VERSION "dbc-export 1 2025.20.8"

NS_ :

BS_:

BU_: ADSP APB APP APS APSB BB BMS CC CMP CMPD CP DAS DI DIF DIR DPB EPAS3P EPAS3S EPASTP EPASTS EPBL EPBR ESP GTW HVP IBST ICR IDB OCS1P ODIN PARK PCS PLG PM PMF PMR PTC RADC RCM RCM2 RCU SCCM SDCR TAS TCU TPMS TRCM UDS UI UIS UMC USM VC VCFRONT VCLEFT VCRIGHT VCSEC

BO_ 998 RCU_alertMatrix: 8 RCU
 SG_ RCU_matrixIndex M : 0|4@1+ (1,0) [0|15] "" Vector__XXX
 SG_ RCU_a001_valveDriverFault m0 : 4|1@1+ (1,0) [0|1] "" Vector__XXX
 SG_ RCU_a002_solenoidValveFault m0 : 5|1@1+ (1,0) [0|1] "" Vector__XXX
 SG_ RCU_a003_pumpMotorFault m0 : 6|1@1+ (1,0) [0|1] "" Vector__XXX
 SG_ RCU_a004_supplyOvervoltage m0 : 7|1@1+ (1,0) [0|1] "" Vector__XXX
 SG_ RCU_a005_supplyUndervoltage m0 : 8|1@1+ (1,0) [0|1] "" Vector__XXX
 SG_ RCU_a006_wakeLineOpen m0 : 9|1@1+ (1,0) [0|1] "" Vector__XXX
 SG_ RCU_a007_pressureSensorFault m0 : 10|1@1+ (1,0) [0|1] "" Vector__XXX
 SG_ RCU_a008_pressureNotCalibrated m0 : 11|1@1+ (1,0) [0|1] "" Vector__XXX
 SG_ RCU_a009_brakeFluidLow m0 : 12|1@1+ (1,0) [0|1] "" Vector__XXX
 SG_ RCU_a010_pedalSensorFault m0 : 13|1@1+ (1,0) [0|1] "" Vector__XXX
 SG_ RCU_a011_idbPedalTravelMismatch m0 : 14|1@1+ (1,0) [0|1] "" Vector__XXX
 SG_ RCU_a012_pedalSensorNotCal m0 : 15|1@1+ (1,0) [0|1] "" Vector__XXX
 SG_ RCU_a013_mcuGenericFault m0 : 16|1@1+ (1,0) [0|1] "" Vector__XXX
 SG_ RCU_a014_asicTempHigh m0 : 17|1@1+ (1,0) [0|1] "" Vector__XXX
 SG_ RCU_a015_fluidLeakDetected m0 : 18|1@1+ (1,0) [0|1] "" Vector__XXX
 SG_ RCU_a016_partyBusOff m0 : 19|1@1+ (1,0) [0|1] "" Vector__XXX
 SG_ RCU_a017_chassisBusOff m0 : 20|1@1+ (1,0) [0|1] "" Vector__XXX
 SG_ RCU_a018_DItorquePathFaulted m0 : 21|1@1+ (1,0) [0|1] "" Vector__XXX
 SG_ RCU_a019_DItorquePathActive m0 : 22|1@1+ (1,0) [0|1] "" Vector__XXX
 SG_ RCU_a020_BBstatusDLC m0 : 23|1@1+ (1,0) [0|1] "" Vector__XXX
 SG_ RCU_a021_BBstatusChecksum m0 : 24|1@1+ (1,0) [0|1] "" Vector__XXX
 SG_ RCU_a022_BBstatusCounter m0 : 25|1@1+ (1,0) [0|1] "" Vector__XXX
 SG_ RCU_a023_IDBstatusDLC m0 : 26|1@1+ (1,0) [0|1] "" Vector__XXX
 SG_ RCU_a024_IDBstatusChecksum m0 : 27|1@1+ (1,0) [0|1] "" Vector__XXX
 SG_ RCU_a025_IDBstatusCounter m0 : 28|1@1+ (1,0) [0|1] "" Vector__XXX
 SG_ RCU_a026_DIchassisControlDLC m0 : 29|1@1+ (1,0) [0|1] "" Vector__XXX
 SG_ RCU_a027_DIchassisCtrlChecksum m0 : 30|1@1+ (1,0) [0|1] "" Vector__XXX
 SG_ RCU_a028_DIchassisControlCounter m0 : 31|1@1+ (1,0) [0|1] "" Vector__XXX
 SG_ RCU_a029_PMstate2DLC m0 : 32|1@1+ (1,0) [0|1] "" Vector__XXX
 SG_ RCU_a030_PMstate2Checksum m0 : 33|1@1+ (1,0) [0|1] "" Vector__XXX
 SG_ RCU_a031_PMstate2Counter m0 : 34|1@1+ (1,0) [0|1] "" Vector__XXX
 SG_ RCU_a032_VCFRONTLVPowerStateDLC m0 : 35|1@1+ (1,0) [0|1] "" Vector__XXX
 SG_ RCU_a033_VCFRONTLVPowerStateChec m0 : 36|1@1+ (1,0) [0|1] "" Vector__XXX
 SG_ RCU_a034_VCFRONTLVPowerStateCoun m0 : 37|1@1+ (1,0) [0|1] "" Vector__XXX
 SG_ RCU_a035_IDBpcpInvalid m0 : 38|1@1+ (1,0) [0|1] "" Vector__XXX
 SG_ RCU_a036_IDBpspInvalid m0 : 39|1@1+ (1,0) [0|1] "" Vector__XXX
 SG_ RCU_a037_IDBinputRodStrokeInvali m0 : 40|1@1+ (1,0) [0|1] "" Vector__XXX
 SG_ RCU_a038_DIsystemStatusDLC m0 : 41|1@1+ (1,0) [0|1] "" Vector__XXX
 SG_ RCU_a039_DIaccelPosInvalid m0 : 42|1@1+ (1,0) [0|1] "" Vector__XXX
 SG_ RCU_a040_DIgearInvalid m0 : 43|1@1+ (1,0) [0|1] "" Vector__XXX
 SG_ RCU_a041_DIsystemStatusCounter m0 : 44|1@1+ (1,0) [0|1] "" Vector__XXX
 SG_ RCU_a042_DIsystemStatusChecksum m0 : 45|1@1+ (1,0) [0|1] "" Vector__XXX
 SG_ RCU_a043_VCFRONTiBoosterLvStateI m0 : 46|1@1+ (1,0) [0|1] "" Vector__XXX
 SG_ RCU_a044_VCFRONTsensorsMIA m0 : 47|1@1+ (1,0) [0|1] "" Vector__XXX
 SG_ RCU_a045_VCFRONTtempInvalid m0 : 48|1@1+ (1,0) [0|1] "" Vector__XXX
 SG_ RCU_a046_brakeFluidLevelSNA m0 : 49|1@1+ (1,0) [0|1] "" Vector__XXX
 SG_ RCU_a047_ESPwheelSpeedsDLC m0 : 50|1@1+ (1,0) [0|1] "" Vector__XXX
 SG_ RCU_a048_ESPFrLWSSLInvalid m0 : 51|1@1+ (1,0) [0|1] "" Vector__XXX
 SG_ RCU_a049_ESPFrRWSSLInvalid m0 : 52|1@1+ (1,0) [0|1] "" Vector__XXX
 SG_ RCU_a050_ESPReLWSSLInvalid m0 : 53|1@1+ (1,0) [0|1] "" Vector__XXX
 SG_ RCU_a051_ESPReRWSSLInvalid m0 : 54|1@1+ (1,0) [0|1] "" Vector__XXX
 SG_ RCU_a052_ESPwheelSpeedsCounter m0 : 55|1@1+ (1,0) [0|1] "" Vector__XXX
 SG_ RCU_a053_ESPwheelSpeedsChecksum m0 : 56|1@1+ (1,0) [0|1] "" Vector__XXX
 SG_ RCU_a054_IDBcircuitPressFaulted m0 : 57|1@1+ (1,0) [0|1] "" Vector__XXX
 SG_ RCU_a055_IDBsimulatorPressFaulte m0 : 58|1@1+ (1,0) [0|1] "" Vector__XXX
 SG_ RCU_a056_redundantControllerIsMa m0 : 59|1@1+ (1,0) [0|1] "" Vector__XXX
 SG_ RCU_a057_PMebrCmdStateInvalid m0 : 60|1@1+ (1,0) [0|1] "" Vector__XXX
 SG_ RCU_a058_DIbrakeTorqueCommandAnd m0 : 61|1@1+ (1,0) [0|1] "" Vector__XXX

BO_ 831 RCU_info: 8 RCU
 SG_ RCU_infoIndex M : 0|8@1+ (1,0) [0|255] "" Vector__XXX
 SG_ RCU_infoPcbaID m11 : 16|8@1+ (1,0) [0|255] "" Vector__XXX
 SG_ RCU_infoAssemblyID m11 : 24|8@1+ (1,0) [0|255] "" Vector__XXX
 SG_ RCU_infoUsageID m11 : 32|16@1+ (1,0) [0|65535] "" Vector__XXX
 SG_ RCU_infoSubUsageID m11 : 48|16@1+ (1,0) [0|65535] "" Vector__XXX

BO_ 1344 SCCM_alertLog: 8 SCCM
 SG_ SCCM_alertID M : 0|15@1+ (1,0) [0|32767] "" Vector__XXX
 SG_ SCCM_alertState : 15|1@1+ (1,0) [0|1] "" Vector__XXX
 SG_ SCCM_a003_debouncePosition m3 : 16|8@1+ (1,0) [0|255] "-" Vector__XXX
 SG_ SCCM_a003_rawPosition m3 : 24|8@1+ (1,0) [0|255] "-" Vector__XXX
 SG_ SCCM_a003_errorPosition m3 : 32|8@1+ (1,0) [0|255] "-" Vector__XXX
 SG_ SCCM_a003_adcValue m3 : 40|8@1+ (1,0) [0|255] "-" Vector__XXX
 SG_ SCCM_a004_debouncePosition m4 : 16|8@1+ (1,0) [0|255] "-" Vector__XXX
 SG_ SCCM_a004_rawPosition m4 : 24|8@1+ (1,0) [0|255] "-" Vector__XXX
 SG_ SCCM_a004_errorPosition m4 : 32|8@1+ (1,0) [0|255] "-" Vector__XXX
 SG_ SCCM_a004_adcValue m4 : 40|8@1+ (1,0) [0|255] "-" Vector__XXX
 SG_ SCCM_a005_debouncePosition m5 : 16|8@1+ (1,0) [0|255] "-" Vector__XXX
 SG_ SCCM_a005_rawPosition m5 : 24|8@1+ (1,0) [0|255] "-" Vector__XXX
 SG_ SCCM_a005_errorPosition m5 : 32|8@1+ (1,0) [0|255] "-" Vector__XXX
 SG_ SCCM_a005_adcValue m5 : 40|8@1+ (1,0) [0|255] "-" Vector__XXX
 SG_ SCCM_a006_debouncePosition m6 : 16|8@1+ (1,0) [0|255] "-" Vector__XXX
 SG_ SCCM_a006_rawPosition m6 : 24|8@1+ (1,0) [0|255] "-" Vector__XXX
 SG_ SCCM_a006_errorPosition m6 : 32|8@1+ (1,0) [0|255] "-" Vector__XXX
 SG_ SCCM_a006_adcValue m6 : 40|8@1+ (1,0) [0|255] "-" Vector__XXX
 SG_ SCCM_a007_debouncePosition m7 : 16|8@1+ (1,0) [0|255] "-" Vector__XXX
 SG_ SCCM_a007_rawPosition m7 : 24|8@1+ (1,0) [0|255] "-" Vector__XXX
 SG_ SCCM_a007_errorPosition m7 : 32|8@1+ (1,0) [0|255] "-" Vector__XXX
 SG_ SCCM_a007_adcValue1 m7 : 40|8@1+ (1,0) [0|255] "-" Vector__XXX
 SG_ SCCM_a007_adcValue2 m7 : 48|8@1+ (1,0) [0|255] "-" Vector__XXX
 SG_ SCCM_a008_debouncePosition m8 : 16|8@1+ (1,0) [0|255] "-" Vector__XXX
 SG_ SCCM_a008_rawPosition m8 : 24|8@1+ (1,0) [0|255] "-" Vector__XXX
 SG_ SCCM_a008_errorPosition m8 : 32|8@1+ (1,0) [0|255] "-" Vector__XXX
 SG_ SCCM_a008_adcValue1 m8 : 40|8@1+ (1,0) [0|255] "-" Vector__XXX
 SG_ SCCM_a008_adcValue2 m8 : 48|8@1+ (1,0) [0|255] "-" Vector__XXX
 SG_ SCCM_a009_debouncePosition m9 : 16|8@1+ (1,0) [0|255] "-" Vector__XXX
 SG_ SCCM_a009_rawPosition m9 : 24|8@1+ (1,0) [0|255] "-" Vector__XXX
 SG_ SCCM_a009_errorPosition m9 : 32|8@1+ (1,0) [0|255] "-" Vector__XXX
 SG_ SCCM_a009_adcValue1 m9 : 40|8@1+ (1,0) [0|255] "-" Vector__XXX
 SG_ SCCM_a009_adcValue2 m9 : 48|8@1+ (1,0) [0|255] "-" Vector__XXX
 SG_ SCCM_a010_debouncePosition m10 : 16|8@1+ (1,0) [0|255] "-" Vector__XXX
 SG_ SCCM_a010_rawPosition m10 : 24|8@1+ (1,0) [0|255] "-" Vector__XXX
 SG_ SCCM_a010_errorPosition m10 : 32|8@1+ (1,0) [0|255] "-" Vector__XXX
 SG_ SCCM_a010_adcValue1 m10 : 40|8@1+ (1,0) [0|255] "-" Vector__XXX
 SG_ SCCM_a010_adcValue2 m10 : 48|8@1+ (1,0) [0|255] "-" Vector__XXX
 SG_ SCCM_a011_debouncePosition m11 : 16|8@1+ (1,0) [0|255] "-" Vector__XXX
 SG_ SCCM_a011_rawPosition m11 : 24|8@1+ (1,0) [0|255] "-" Vector__XXX
 SG_ SCCM_a011_errorPosition m11 : 32|8@1+ (1,0) [0|255] "-" Vector__XXX
 SG_ SCCM_a011_adcValue1 m11 : 40|8@1+ (1,0) [0|255] "-" Vector__XXX
 SG_ SCCM_a011_adcValue2 m11 : 48|8@1+ (1,0) [0|255] "-" Vector__XXX
 SG_ SCCM_a012_debouncePosition m12 : 16|8@1+ (1,0) [0|255] "-" Vector__XXX
 SG_ SCCM_a012_rawPosition m12 : 24|8@1+ (1,0) [0|255] "-" Vector__XXX
 SG_ SCCM_a012_errorPosition m12 : 32|8@1+ (1,0) [0|255] "-" Vector__XXX
 SG_ SCCM_a012_adcValue1 m12 : 40|8@1+ (1,0) [0|255] "-" Vector__XXX
 SG_ SCCM_a012_adcValue2 m12 : 48|8@1+ (1,0) [0|255] "-" Vector__XXX
 SG_ SCCM_a013_voltage m13 : 16|8@1+ (1,0) [0|255] "-" Vector__XXX
 SG_ SCCM_a014_voltage m14 : 16|8@1+ (1,0) [0|255] "-" Vector__XXX
 SG_ SCCM_a015_intMainIndex m15 : 16|8@1+ (1,0) [0|255] "-" Vector__XXX
 SG_ SCCM_a015_intSubIndex m15 : 24|8@1+ (1,0) [0|255] "-" Vector__XXX
 SG_ SCCM_a015_intMemIndex m15 : 32|8@1+ (1,0) [0|255] "-" Vector__XXX
 SG_ SCCM_a016_mainAdcTest m16 : 16|4@1+ (1,0) [0|15] "-" Vector__XXX
 SG_ SCCM_a016_mainCpuTest m16 : 20|4@1+ (1,0) [0|15] "-" Vector__XXX
 SG_ SCCM_a016_wdtTest m16 : 24|4@1+ (1,0) [0|15] "-" Vector__XXX
 SG_ SCCM_a016_subCpuTest m16 : 28|4@1+ (1,0) [0|15] "-" Vector__XXX
 SG_ SCCM_a016_subAdcTest m16 : 32|4@1+ (1,0) [0|15] "-" Vector__XXX
 SG_ SCCM_a017_mainRamTest m17 : 16|4@1+ (1,0) [0|15] "-" Vector__XXX
 SG_ SCCM_a017_mainRomTest m17 : 20|4@1+ (1,0) [0|15] "-" Vector__XXX
 SG_ SCCM_a017_stackHardLimitTest m17 : 24|4@1+ (1,0) [0|15] "-" Vector__XXX
 SG_ SCCM_a017_mainDataFlashTest m17 : 28|4@1+ (1,0) [0|15] "-" Vector__XXX
 SG_ SCCM_a017_subRamTest m17 : 32|4@1+ (1,0) [0|15] "-" Vector__XXX
 SG_ SCCM_a017_subRomTest m17 : 36|4@1+ (1,0) [0|15] "-" Vector__XXX
 SG_ SCCM_a017_subStackHardLimitTest m17 : 40|4@1+ (1,0) [0|15] "-" Vector__XXX
 SG_ SCCM_a017_svError m17 : 44|16@1+ (1,0) [0|65535] "-" Vector__XXX
 SG_ SCCM_a018_internalSASState m18 : 16|8@1+ (1,0) [0|255] "-" Vector__XXX
 SG_ SCCM_a019_internalSASState m19 : 16|8@1+ (1,0) [0|255] "-" Vector__XXX
 SG_ SCCM_a020_internalSASState m20 : 16|8@1+ (1,0) [0|255] "-" Vector__XXX
 SG_ SCCM_a021_adcValue1 m21 : 16|8@1+ (1,0) [0|255] "-" Vector__XXX
 SG_ SCCM_a021_adcValue2 m21 : 24|8@1+ (1,0) [0|255] "-" Vector__XXX
 SG_ SCCM_a021_adcValue3 m21 : 32|8@1+ (1,0) [0|255] "-" Vector__XXX
 SG_ SCCM_a021_adcValue4 m21 : 40|8@1+ (1,0) [0|255] "-" Vector__XXX
 SG_ SCCM_a021_adcValue5 m21 : 48|8@1+ (1,0) [0|255] "-" Vector__XXX
 SG_ SCCM_a021_adcValue6 m21 : 56|8@1+ (1,0) [0|255] "-" Vector__XXX
 SG_ SCCM_a022_adcValue1 m22 : 16|8@1+ (1,0) [0|255] "-" Vector__XXX
 SG_ SCCM_a022_adcValue2 m22 : 24|8@1+ (1,0) [0|255] "-" Vector__XXX
 SG_ SCCM_a022_adcValue3 m22 : 32|8@1+ (1,0) [0|255] "-" Vector__XXX
 SG_ SCCM_a022_adcValue4 m22 : 40|8@1+ (1,0) [0|255] "-" Vector__XXX
 SG_ SCCM_a022_adcValue5 m22 : 48|8@1+ (1,0) [0|255] "-" Vector__XXX
 SG_ SCCM_a022_adcValue6 m22 : 56|8@1+ (1,0) [0|255] "-" Vector__XXX
 SG_ SCCM_a023_adcValue1 m23 : 16|8@1+ (1,0) [0|255] "-" Vector__XXX
 SG_ SCCM_a023_adcValue2 m23 : 24|8@1+ (1,0) [0|255] "-" Vector__XXX
 SG_ SCCM_a023_adcValue3 m23 : 32|8@1+ (1,0) [0|255] "-" Vector__XXX
 SG_ SCCM_a023_adcValue4 m23 : 40|8@1+ (1,0) [0|255] "-" Vector__XXX
 SG_ SCCM_a023_adcValue5 m23 : 48|8@1+ (1,0) [0|255] "-" Vector__XXX
 SG_ SCCM_a023_adcValue6 m23 : 56|8@1+ (1,0) [0|255] "-" Vector__XXX
 SG_ SCCM_a024_adcValue1 m24 : 16|8@1+ (1,0) [0|255] "-" Vector__XXX
 SG_ SCCM_a024_adcValue2 m24 : 24|8@1+ (1,0) [0|255] "-" Vector__XXX
 SG_ SCCM_a024_adcValue3 m24 : 32|8@1+ (1,0) [0|255] "-" Vector__XXX
 SG_ SCCM_a024_adcValue4 m24 : 40|8@1+ (1,0) [0|255] "-" Vector__XXX
 SG_ SCCM_a024_adcValue5 m24 : 48|8@1+ (1,0) [0|255] "-" Vector__XXX
 SG_ SCCM_a024_adcValue6 m24 : 56|8@1+ (1,0) [0|255] "-" Vector__XXX
 SG_ SCCM_a025_taskState m25 : 16|16@1+ (1,0) [0|65535] "-" Vector__XXX
 SG_ SCCM_a026_debouncePosition m26 : 16|8@1+ (1,0) [0|255] "-" Vector__XXX
 SG_ SCCM_a026_rawPosition m26 : 24|8@1+ (1,0) [0|255] "-" Vector__XXX
 SG_ SCCM_a026_errorPosition m26 : 32|8@1+ (1,0) [0|255] "-" Vector__XXX
 SG_ SCCM_a026_adcValue1 m26 : 40|8@1+ (1,0) [0|255] "-" Vector__XXX
 SG_ SCCM_a026_adcValue2 m26 : 48|8@1+ (1,0) [0|255] "-" Vector__XXX
 SG_ SCCM_a027_debouncePosition m27 : 16|8@1+ (1,0) [0|255] "-" Vector__XXX
 SG_ SCCM_a027_rawPosition m27 : 24|8@1+ (1,0) [0|255] "-" Vector__XXX
 SG_ SCCM_a027_errorPosition m27 : 32|8@1+ (1,0) [0|255] "-" Vector__XXX
 SG_ SCCM_a027_adcValue1 m27 : 40|8@1+ (1,0) [0|255] "-" Vector__XXX
 SG_ SCCM_a027_adcValue2 m27 : 48|8@1+ (1,0) [0|255] "-" Vector__XXX
 SG_ SCCM_a028_debouncePosition m28 : 16|8@1+ (1,0) [0|255] "-" Vector__XXX
 SG_ SCCM_a028_rawPosition m28 : 24|8@1+ (1,0) [0|255] "-" Vector__XXX
 SG_ SCCM_a028_errorPosition m28 : 32|8@1+ (1,0) [0|255] "-" Vector__XXX
 SG_ SCCM_a028_adcValue1 m28 : 40|8@1+ (1,0) [0|255] "-" Vector__XXX
 SG_ SCCM_a028_adcValue2 m28 : 48|8@1+ (1,0) [0|255] "-" Vector__XXX
 SG_ SCCM_a029_debouncePosition m29 : 16|8@1+ (1,0) [0|255] "-" Vector__XXX
 SG_ SCCM_a029_rawPosition m29 : 24|8@1+ (1,0) [0|255] "-" Vector__XXX
 SG_ SCCM_a029_errorPosition m29 : 32|8@1+ (1,0) [0|255] "-" Vector__XXX
 SG_ SCCM_a029_adcValue1 m29 : 40|8@1+ (1,0) [0|255] "-" Vector__XXX
 SG_ SCCM_a029_adcValue2 m29 : 48|8@1+ (1,0) [0|255] "-" Vector__XXX
 SG_ SCCM_a061_voltage m61 : 16|8@1+ (0.1,0) [0|25.5] "V" Vector__XXX
 SG_ SCCM_a062_voltage m62 : 16|8@1+ (0.1,0) [0|25.5] "V" Vector__XXX
 SG_ SCCM_a063_UntrimmedAngle m63 : 16|16@1+ (0.1,-819.2) [-819.2|5734.3] "deg" Vector__XXX
 SG_ SCCM_a064_Speed m64 : 16|16@1+ (0.5,-4096) [-4096|28671.5] "deg/s" Vector__XXX
 SG_ SCCM_a065_M1RawAngleCurrent m65 : 16|12@1+ (0.08791209,0) [0|360.00000855] "deg" Vector__XXX
 SG_ SCCM_a065_M1RawAnglePrevious m65 : 28|12@1+ (0.08791209,0) [0|360.00000855] "deg" Vector__XXX
 SG_ SCCM_a065_M2RawAngleCurrent m65 : 40|12@1+ (0.08791209,0) [0|360.00000855] "deg" Vector__XXX
 SG_ SCCM_a065_M2RawAnglePrevious m65 : 52|12@1+ (0.08791209,0) [0|360.00000855] "deg" Vector__XXX
 SG_ SCCM_a066_M1RawAngleCurrent m66 : 16|12@1+ (0.08791209,0) [0|360.00000855] "deg" Vector__XXX
 SG_ SCCM_a066_M1RawAnglePrevious m66 : 28|12@1+ (0.08791209,0) [0|360.00000855] "deg" Vector__XXX
 SG_ SCCM_a066_M2RawAngleCurrent m66 : 40|12@1+ (0.08791209,0) [0|360.00000855] "deg" Vector__XXX
 SG_ SCCM_a066_M2RawAnglePrevious m66 : 52|12@1+ (0.08791209,0) [0|360.00000855] "deg" Vector__XXX
 SG_ SCCM_a071_M1LogicBISTFailed m71 : 16|1@1+ (1,0) [0|1] "" Vector__XXX
 SG_ SCCM_a071_M1PowerOnReset m71 : 17|1@1+ (1,0) [0|1] "" Vector__XXX
 SG_ SCCM_a071_M1UnderVoltage m71 : 18|1@1+ (1,0) [0|1] "" Vector__XXX
 SG_ SCCM_a071_M1OverVoltage m71 : 19|1@1+ (1,0) [0|1] "" Vector__XXX
 SG_ SCCM_a071_M1DualBitError m71 : 20|1@1+ (1,0) [0|1] "" Vector__XXX
 SG_ SCCM_a071_M1RefVoltageOutOfRange m71 : 21|1@1+ (1,0) [0|1] "" Vector__XXX
 SG_ SCCM_a071_M1RegisterParityError m71 : 22|1@1+ (1,0) [0|1] "" Vector__XXX
 SG_ SCCM_a071_M1OscillatorFreqError m71 : 23|1@1+ (1,0) [0|1] "" Vector__XXX
 SG_ SCCM_a071_M1SignalOutOfRange m71 : 24|1@1+ (1,0) [0|1] "" Vector__XXX
 SG_ SCCM_a071_M1TempOutOfRange m71 : 25|1@1+ (1,0) [0|1] "" Vector__XXX
 SG_ SCCM_a071_M1AngleMismatch m71 : 26|1@1+ (1,0) [0|1] "" Vector__XXX
 SG_ SCCM_a071_M1RadiusOutOfRange m71 : 27|1@1+ (1,0) [0|1] "" Vector__XXX
 SG_ SCCM_a071_M2LogicBISTFailed m71 : 28|1@1+ (1,0) [0|1] "" Vector__XXX
 SG_ SCCM_a071_M2PowerOnReset m71 : 29|1@1+ (1,0) [0|1] "" Vector__XXX
 SG_ SCCM_a071_M2UnderVoltage m71 : 30|1@1+ (1,0) [0|1] "" Vector__XXX
 SG_ SCCM_a071_M2OverVoltage m71 : 31|1@1+ (1,0) [0|1] "" Vector__XXX
 SG_ SCCM_a071_M2DualBitError m71 : 32|1@1+ (1,0) [0|1] "" Vector__XXX
 SG_ SCCM_a071_M2RefVoltageOutOfRange m71 : 33|1@1+ (1,0) [0|1] "" Vector__XXX
 SG_ SCCM_a071_M2RegisterParityError m71 : 34|1@1+ (1,0) [0|1] "" Vector__XXX
 SG_ SCCM_a071_M2OscillatorFreqError m71 : 35|1@1+ (1,0) [0|1] "" Vector__XXX
 SG_ SCCM_a071_M2SignalOutOfRange m71 : 36|1@1+ (1,0) [0|1] "" Vector__XXX
 SG_ SCCM_a071_M2TempOutOfRange m71 : 37|1@1+ (1,0) [0|1] "" Vector__XXX
 SG_ SCCM_a071_M2AngleMismatch m71 : 38|1@1+ (1,0) [0|1] "" Vector__XXX
 SG_ SCCM_a071_M2RadiusOutOfRange m71 : 39|1@1+ (1,0) [0|1] "" Vector__XXX
 SG_ SCCM_a071_M1ProcessLogicFailed m71 : 40|1@1+ (1,0) [0|1] "" Vector__XXX
 SG_ SCCM_a071_M2ProcessLogicFailed m71 : 41|1@1+ (1,0) [0|1] "" Vector__XXX
 SG_ SCCM_a071_TSOSCHighFreqError m71 : 42|1@1+ (1,0) [0|1] "" Vector__XXX
 SG_ SCCM_a071_TSOSCLowFreqError m71 : 43|1@1+ (1,0) [0|1] "" Vector__XXX
 SG_ SCCM_a071_TSOPRStatMismatch m71 : 44|1@1+ (1,0) [0|1] "" Vector__XXX
 SG_ SCCM_a071_TSCRCStatError m71 : 45|1@1+ (1,0) [0|1] "" Vector__XXX
 SG_ SCCM_a071_TSFrameStatError m71 : 46|1@1+ (1,0) [0|1] "" Vector__XXX
 SG_ SCCM_a071_TSOverVoltage m71 : 47|1@1+ (1,0) [0|1] "" Vector__XXX
 SG_ SCCM_a071_TSUnderVoltage m71 : 48|1@1+ (1,0) [0|1] "" Vector__XXX
 SG_ SCCM_a071_TSPowerOnReset m71 : 49|1@1+ (1,0) [0|1] "" Vector__XXX
 SG_ SCCM_a071_TSLDOStatError m71 : 50|1@1+ (1,0) [0|1] "" Vector__XXX
 SG_ SCCM_a071_TSTempOutOfRange m71 : 51|1@1+ (1,0) [0|1] "" Vector__XXX
 SG_ SCCM_a071_TSAlertIntegrityCheck m71 : 52|1@1+ (1,0) [0|1] "" Vector__XXX
 SG_ SCCM_a071_TSMemoryCRCError m71 : 53|1@1+ (1,0) [0|1] "" Vector__XXX
 SG_ SCCM_a071_TSAFECheck m71 : 54|1@1+ (1,0) [0|1] "" Vector__XXX
 SG_ SCCM_a071_TSADCCheck m71 : 55|1@1+ (1,0) [0|1] "" Vector__XXX
 SG_ SCCM_a071_TSConfigFault m71 : 56|1@1+ (1,0) [0|1] "" Vector__XXX
 SG_ SCCM_a072_M1CRCCalculated m72 : 16|4@1+ (1,0) [0|15] "" Vector__XXX
 SG_ SCCM_a072_M1CRCReceived m72 : 20|4@1+ (1,0) [0|15] "" Vector__XXX
 SG_ SCCM_a072_M2CRCCalculated m72 : 24|4@1+ (1,0) [0|15] "" Vector__XXX
 SG_ SCCM_a072_M2CRCReceived m72 : 28|4@1+ (1,0) [0|15] "" Vector__XXX
 SG_ SCCM_a072_TSCRCCalculated m72 : 32|4@1+ (1,0) [0|15] "" Vector__XXX
 SG_ SCCM_a072_TSCRCReceived m72 : 36|4@1+ (1,0) [0|15] "" Vector__XXX
 SG_ SCCM_a075_ClockOutOfRange m75 : 16|1@1+ (1,0) [0|1] "" Vector__XXX
 SG_ SCCM_a075_ExtWatchdogTestFailed m75 : 17|1@1+ (1,0) [0|1] "" Vector__XXX
 SG_ SCCM_a075_InterruptMonitorError m75 : 18|1@1+ (1,0) [0|1] "" Vector__XXX
 SG_ SCCM_a076_RAMTestFailed m76 : 16|1@1+ (1,0) [0|1] "" Vector__XXX
 SG_ SCCM_a076_NVMTestFailed m76 : 17|1@1+ (1,0) [0|1] "" Vector__XXX
 SG_ SCCM_a077_M1ExpectAngleCurrent m77 : 16|12@1+ (0.08791209,0) [0|360.00000855] "deg" Vector__XXX
 SG_ SCCM_a077_M1ExpectAnglePrevious m77 : 28|12@1+ (0.08791209,0) [0|360.00000855] "deg" Vector__XXX
 SG_ SCCM_a077_M1AngleCurrent m77 : 40|12@1+ (0.08791209,0) [0|360.00000855] "deg" Vector__XXX
 SG_ SCCM_a077_M1AnglePrevious m77 : 52|12@1+ (0.08791209,0) [0|360.00000855] "deg" Vector__XXX
 SG_ SCCM_a079_ChipTemperature m79 : 16|11@1+ (0.1,-50) [-50|154.7] "degC" Vector__XXX
 SG_ SCCM_a081_StartupTestStatus m81 : 16|3@1+ (1,0) [0|7] "" Vector__XXX
 SG_ SCCM_a081_sCheckTestFailedData m81 : 19|8@1+ (1,0) [0|255] "" Vector__XXX
 SG_ SCCM_a081_sBootTestFailedData m81 : 27|16@1+ (1,0) [0|65535] "" Vector__XXX
 SG_ SCCM_a081_BISTTestFailedData m81 : 43|16@1+ (1,0) [0|65535] "" Vector__XXX
 SG_ SCCM_a082_RuntimeTestStatus m82 : 16|2@1+ (1,0) [0|3] "" Vector__XXX
 SG_ SCCM_a082_sCheckTestFailedData m82 : 18|8@1+ (1,0) [0|255] "" Vector__XXX
 SG_ SCCM_a082_ArrayIntegrFailedData m82 : 26|8@1+ (1,0) [0|255] "" Vector__XXX
 SG_ SCCM_a121_turnIndicatorStalkAngl m121 : 16|12@1+ (0.1,-180) [-180|229.5] "deg" Vector__XXX
 SG_ SCCM_a121_turnIndicatorHallAngle m121 : 28|12@1+ (0.1,-180) [-180|229.5] "deg" Vector__XXX
 SG_ SCCM_a122_turnIndicatorSpeed m122 : 16|12@1+ (0.02,-36) [-36|45.9] "deg/ms" Vector__XXX
 SG_ SCCM_a123_turnIndicatorStalkAngl m123 : 16|12@1+ (0.1,-180) [-180|229.5] "deg" Vector__XXX
 SG_ SCCM_a124_turnIndicatorStalkAngl m124 : 16|12@1+ (0.1,-180) [-180|229.5] "deg" Vector__XXX
 SG_ SCCM_a125_turnIndicatorHallAngle m125 : 16|12@1+ (0.1,-180) [-180|229.5] "deg" Vector__XXX
 SG_ SCCM_a125_turnIndicatorVectorAng m125 : 28|12@1+ (0.1,-180) [-180|229.5] "deg" Vector__XXX
 SG_ SCCM_a126_turnIndicatorXVectorOu m126 : 16|1@1+ (1,0) [0|1] "" Vector__XXX
 SG_ SCCM_a126_turnIndicatorYVectorOu m126 : 17|1@1+ (1,0) [0|1] "" Vector__XXX
 SG_ SCCM_a126_turnIndicatorZVectorOu m126 : 18|1@1+ (1,0) [0|1] "" Vector__XXX
 SG_ SCCM_a126_turnIndicatorResu_0001 m126 : 19|1@1+ (1,0) [0|1] "" Vector__XXX
 SG_ SCCM_a126_turnIndicatorXMagnitud m126 : 24|8@1+ (1,0) [0|255] "mT" Vector__XXX
 SG_ SCCM_a126_turnIndicatorYMagnitud m126 : 32|8@1+ (1,0) [0|255] "mT" Vector__XXX
 SG_ SCCM_a126_turnIndicatorZMagnitud m126 : 40|8@1+ (1,0) [0|255] "mT" Vector__XXX
 SG_ SCCM_a126_turnIndicatorResultant m126 : 48|8@1+ (1,0) [0|255] "mT" Vector__XXX

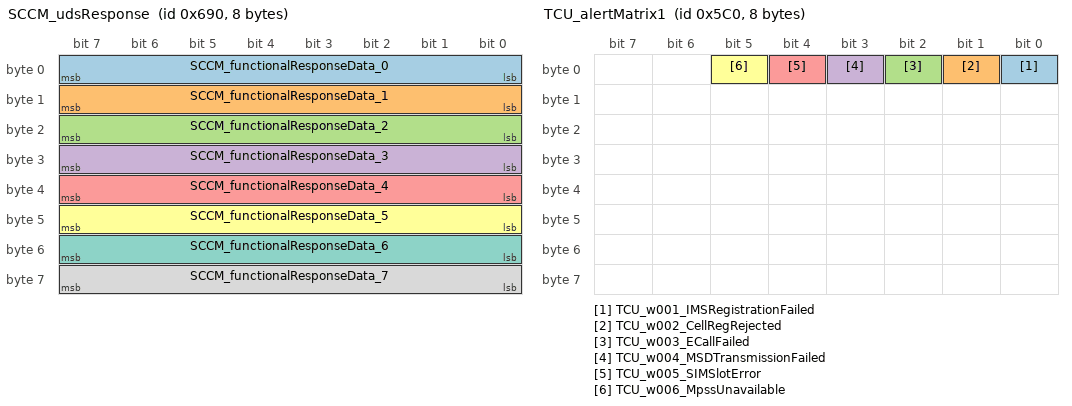
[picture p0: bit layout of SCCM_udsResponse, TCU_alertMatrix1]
BO_ 1680 SCCM_udsResponse: 8 SCCM
 SG_ SCCM_functionalResponseData_0 : 7|8@0+ (1,0) [0|255] "" Vector__XXX
 SG_ SCCM_functionalResponseData_1 : 15|8@0+ (1,0) [0|255] "" Vector__XXX
 SG_ SCCM_functionalResponseData_2 : 23|8@0+ (1,0) [0|255] "" Vector__XXX
 SG_ SCCM_functionalResponseData_3 : 31|8@0+ (1,0) [0|255] "" Vector__XXX
 SG_ SCCM_functionalResponseData_4 : 39|8@0+ (1,0) [0|255] "" Vector__XXX
 SG_ SCCM_functionalResponseData_5 : 47|8@0+ (1,0) [0|255] "" Vector__XXX
 SG_ SCCM_functionalResponseData_6 : 55|8@0+ (1,0) [0|255] "" Vector__XXX
 SG_ SCCM_functionalResponseData_7 : 63|8@0+ (1,0) [0|255] "" Vector__XXX

BO_ 1531 SDCR_alertLog: 8 SDCR
 SG_ SDCR_alertID M : 0|6@1+ (1,0) [0|63] "" Vector__XXX
 SG_ SDCR_alertState : 15|1@1+ (1,0) [0|1] "" Vector__XXX
 SG_ SDCR_a001_pyroSenseV m1 : 16|8@1+ (0.02,0) [0|5.1] "V" Vector__XXX
 SG_ SDCR_a001_HVBackupSupplyV m1 : 24|8@1+ (0.15,0) [0|38.25] "V" Vector__XXX
 SG_ SDCR_a001_boostRailV m1 : 32|8@1+ (0.15,0) [0|38.25] "V" Vector__XXX
 SG_ SDCR_a001_expectedPyroV_max m1 : 40|8@1+ (0.02,0) [0|5.1] "V" Vector__XXX
 SG_ SDCR_a001_expectedPyroV_min m1 : 48|8@1+ (0.02,0) [0|5.1] "V" Vector__XXX
 SG_ SDCR_a001_fromState m1 : 56|3@1+ (1,0) [0|7] "" Vector__XXX
 SG_ SDCR_a004_HVBackupSupplyV m4 : 16|8@1+ (0.15,0) [0|38.25] "V" Vector__XXX
 SG_ SDCR_a004_boostRailV m4 : 24|8@1+ (0.15,0) [0|38.25] "V" Vector__XXX
 SG_ SDCR_a004_diPresent m4 : 32|1@1+ (1,0) [0|1] "" Vector__XXX
 SG_ SDCR_a004_pmRunningPin m4 : 33|1@1+ (1,0) [0|1] "" Vector__XXX
 SG_ SDCR_a006_pyroArmed m6 : 16|1@1+ (1,0) [0|1] "" Vector__XXX
 SG_ SDCR_a006_triggerReason_faultCur m6 : 17|1@1+ (1,0) [0|1] "" Vector__XXX
 SG_ SDCR_a006_triggerReason_hvBadAtS m6 : 18|1@1+ (1,0) [0|1] "" Vector__XXX
 SG_ SDCR_a006_triggerReason_highBack m6 : 19|1@1+ (1,0) [0|1] "" Vector__XXX
 SG_ SDCR_a006_faultCurrentsDetected m6 : 20|1@1+ (1,0) [0|1] "" Vector__XXX
 SG_ SDCR_a006_diUartMIA m6 : 21|1@1+ (1,0) [0|1] "" Vector__XXX
 SG_ SDCR_a006_pmRunningPin m6 : 22|1@1+ (1,0) [0|1] "" Vector__XXX
 SG_ SDCR_a006_hvPowerGood m6 : 23|1@1+ (1,0) [0|1] "" Vector__XXX
 SG_ SDCR_a006_hvbkupPGoodPin m6 : 24|1@1+ (1,0) [0|1] "" Vector__XXX
 SG_ SDCR_a006_hvPowerNotGoodQualifie m6 : 25|1@1+ (1,0) [0|1] "" Vector__XXX
 SG_ SDCR_a006_speedValid m6 : 26|1@1+ (1,0) [0|1] "" Vector__XXX
 SG_ SDCR_a006_speedFromVoltage m6 : 27|1@1+ (1,0) [0|1] "" Vector__XXX
 SG_ SDCR_a006_HVBackupSupplyV m6 : 28|7@1+ (0.3,0) [0|38.1] "V" Vector__XXX
 SG_ SDCR_a006_boostRailV m6 : 35|7@1+ (0.3,0) [0|38.1] "V" Vector__XXX
 SG_ SDCR_a006_maxAbsSpeed m6 : 42|12@1- (1,0) [-2048|2047] "Hz" Vector__XXX
 SG_ SDCR_a006_vBat m6 : 54|7@1+ (8,0) [0|1016] "V" Vector__XXX
 SG_ SDCR_a007_faultReason_faultCurre m7 : 16|1@1+ (1,0) [0|1] "" Vector__XXX
 SG_ SDCR_a007_faultReason_unmitigate m7 : 17|1@1+ (1,0) [0|1] "" Vector__XXX
 SG_ SDCR_a007_faultReason_propagatin m7 : 18|1@1+ (1,0) [0|1] "" Vector__XXX
 SG_ SDCR_a007_speedWasValid m7 : 19|1@1+ (1,0) [0|1] "" Vector__XXX
 SG_ SDCR_a007_imbalanceSeen m7 : 20|1@1+ (1,0) [0|1] "" Vector__XXX
 SG_ SDCR_a007_ucrSeen m7 : 21|1@1+ (1,0) [0|1] "" Vector__XXX
 SG_ SDCR_a007_phaseVoltagePresent m7 : 22|1@1+ (1,0) [0|1] "" Vector__XXX
 SG_ SDCR_a007_speedFromVoltage m7 : 23|1@1+ (1,0) [0|1] "" Vector__XXX
 SG_ SDCR_a007_transientHandling m7 : 24|2@1+ (1,0) [0|3] "" Vector__XXX
 SG_ SDCR_a007_maxAbsElcSpeed m7 : 26|9@1+ (4,0) [0|2044] "Hz" Vector__XXX
 SG_ SDCR_a007_avgIa m7 : 35|10@1- (4,0) [-2048|2044] "A" Vector__XXX
 SG_ SDCR_a007_avgIb m7 : 45|10@1- (4,0) [-2048|2044] "A" Vector__XXX
 SG_ SDCR_a007_maxAbsCurrents m7 : 55|9@1+ (4,0) [0|2044] "A" Vector__XXX
 SG_ SDCR_a008_dcLinkInfo m8 : 16|1@1+ (1,0) [0|1] "" Vector__XXX
 SG_ SDCR_a009_diVersion m9 : 16|2@1+ (1,0) [0|3] "" Vector__XXX
 SG_ SDCR_a009_sdcVersion m9 : 18|2@1+ (1,0) [0|3] "" Vector__XXX
 SG_ SDCR_a010_pgood m10 : 16|1@1+ (1,0) [0|1] "" Vector__XXX
 SG_ SDCR_a010_boostRailV m10 : 24|8@1+ (0.15,0) [0|38.25] "V" Vector__XXX
 SG_ SDCR_a010_Vref m10 : 32|8@1+ (0.02,0) [0|5.1] "V" Vector__XXX
 SG_ SDCR_a011_IaAvg m11 : 16|16@1- (0.1,0) [-3276.8|3276.7] "A" Vector__XXX
 SG_ SDCR_a011_IbAvg m11 : 32|16@1- (0.1,0) [-3276.8|3276.7] "A" Vector__XXX
 SG_ SDCR_a012_boostRailV m12 : 16|8@1+ (0.15,0) [0|38.25] "V" Vector__XXX
 SG_ SDCR_a012_HVBackupSupplyV m12 : 24|8@1+ (0.15,0) [0|38.25] "V" Vector__XXX
 SG_ SDCR_a012_vBat m12 : 32|10@1+ (2,0) [0|2046] "V" Vector__XXX
 SG_ SDCR_a012_vbkupGoodFdbk m12 : 42|1@1+ (1,0) [0|1] "" Vector__XXX
 SG_ SDCR_a013_boostRailV m13 : 16|8@1+ (0.15,0) [0|38.25] "V" Vector__XXX
 SG_ SDCR_a013_HVBackupSupplyV m13 : 24|8@1+ (0.15,0) [0|38.25] "V" Vector__XXX
 SG_ SDCR_a013_vBat m13 : 32|10@1+ (2,0) [0|2046] "V" Vector__XXX
 SG_ SDCR_a013_vbkupGoodFdbk m13 : 42|1@1+ (1,0) [0|1] "" Vector__XXX
 SG_ SDCR_a014_reason_vBusShortedLow m14 : 16|1@1+ (1,0) [0|1] "" Vector__XXX
 SG_ SDCR_a014_reason_vBusShortedHigh m14 : 17|1@1+ (1,0) [0|1] "" Vector__XXX
 SG_ SDCR_a014_boostRailV m14 : 24|8@1+ (0.15,0) [0|38.25] "V" Vector__XXX
 SG_ SDCR_a014_HVBackupSupplyV m14 : 32|8@1+ (0.15,0) [0|38.25] "V" Vector__XXX
 SG_ SDCR_a014_vBat m14 : 40|10@1+ (2,0) [0|2046] "V" Vector__XXX
 SG_ SDCR_a014_vbkupGoodFdbk m14 : 50|1@1+ (1,0) [0|1] "" Vector__XXX
 SG_ SDCR_a015_reason_vPhaseShortedLo m15 : 16|1@1+ (1,0) [0|1] "" Vector__XXX
 SG_ SDCR_a015_reason_vPhaseShortedHi m15 : 17|1@1+ (1,0) [0|1] "" Vector__XXX
 SG_ SDCR_a015_diSwitchingPin m15 : 18|1@1+ (1,0) [0|1] "" Vector__XXX
 SG_ SDCR_a015_vBat m15 : 19|10@1+ (2,0) [0|2046] "V" Vector__XXX
 SG_ SDCR_a015_va m15 : 29|10@1+ (2,0) [0|2046] "V" Vector__XXX
 SG_ SDCR_a015_vb m15 : 40|10@1+ (2,0) [0|2046] "V" Vector__XXX
 SG_ SDCR_a015_vc m15 : 50|10@1+ (2,0) [0|2046] "V" Vector__XXX
 SG_ SDCR_a017_expectedConfigWord m17 : 16|16@1+ (1,0) [0|65535] "" Vector__XXX
 SG_ SDCR_a017_receivedConfigWord m17 : 32|16@1+ (1,0) [0|65535] "" Vector__XXX
 SG_ SDCR_a018_pyroArmed m18 : 16|1@1+ (1,0) [0|1] "" Vector__XXX
 SG_ SDCR_a018_triggerReason_faultCur m18 : 17|1@1+ (1,0) [0|1] "" Vector__XXX
 SG_ SDCR_a018_triggerReason_hvBadAtS m18 : 18|1@1+ (1,0) [0|1] "" Vector__XXX
 SG_ SDCR_a018_triggerReason_highBack m18 : 19|1@1+ (1,0) [0|1] "" Vector__XXX
 SG_ SDCR_a018_faultCurrentsDetected m18 : 20|1@1+ (1,0) [0|1] "" Vector__XXX
 SG_ SDCR_a018_diUartMIA m18 : 21|1@1+ (1,0) [0|1] "" Vector__XXX
 SG_ SDCR_a018_pmRunningPin m18 : 22|1@1+ (1,0) [0|1] "" Vector__XXX
 SG_ SDCR_a018_hvPowerGood m18 : 23|1@1+ (1,0) [0|1] "" Vector__XXX
 SG_ SDCR_a018_hvbkupPGoodPin m18 : 24|1@1+ (1,0) [0|1] "" Vector__XXX
 SG_ SDCR_a018_hvPowerNotGoodQualifie m18 : 25|1@1+ (1,0) [0|1] "" Vector__XXX
 SG_ SDCR_a018_speedValid m18 : 26|1@1+ (1,0) [0|1] "" Vector__XXX
 SG_ SDCR_a018_speedFromVoltage m18 : 27|1@1+ (1,0) [0|1] "" Vector__XXX
 SG_ SDCR_a018_HVBackupSupplyV m18 : 28|7@1+ (0.3,0) [0|38.1] "V" Vector__XXX
 SG_ SDCR_a018_boostRailV m18 : 35|7@1+ (0.3,0) [0|38.1] "V" Vector__XXX
 SG_ SDCR_a018_maxAbsSpeed m18 : 42|12@1- (1,0) [-2048|2047] "Hz" Vector__XXX
 SG_ SDCR_a018_vBat m18 : 54|7@1+ (8,0) [0|1016] "V" Vector__XXX
 SG_ SDCR_a019_faultReason_faultCurre m19 : 16|1@1+ (1,0) [0|1] "" Vector__XXX
 SG_ SDCR_a019_faultReason_unmitigate m19 : 17|1@1+ (1,0) [0|1] "" Vector__XXX
 SG_ SDCR_a019_faultReason_propagatin m19 : 18|1@1+ (1,0) [0|1] "" Vector__XXX
 SG_ SDCR_a019_speedWasValid m19 : 19|1@1+ (1,0) [0|1] "" Vector__XXX
 SG_ SDCR_a019_imbalanceSeen m19 : 20|1@1+ (1,0) [0|1] "" Vector__XXX
 SG_ SDCR_a019_ucrSeen m19 : 21|1@1+ (1,0) [0|1] "" Vector__XXX
 SG_ SDCR_a019_phaseVoltagePresent m19 : 22|1@1+ (1,0) [0|1] "" Vector__XXX
 SG_ SDCR_a019_speedFromVoltage m19 : 23|1@1+ (1,0) [0|1] "" Vector__XXX
 SG_ SDCR_a019_transientHandling m19 : 24|2@1+ (1,0) [0|3] "" Vector__XXX
 SG_ SDCR_a019_maxAbsElcSpeed m19 : 26|9@1+ (4,0) [0|2044] "Hz" Vector__XXX
 SG_ SDCR_a019_avgIa m19 : 35|10@1- (4,0) [-2048|2044] "A" Vector__XXX
 SG_ SDCR_a019_avgIb m19 : 45|10@1- (4,0) [-2048|2044] "A" Vector__XXX
 SG_ SDCR_a019_maxAbsCurrents m19 : 55|9@1+ (4,0) [0|2044] "A" Vector__XXX
 SG_ SDCR_a020_errorCode m20 : 16|8@1+ (1,0) [0|255] "" Vector__XXX
 SG_ SDCR_a020_rxData0 m20 : 24|8@1+ (1,0) [0|255] "" Vector__XXX
 SG_ SDCR_a020_rxData1 m20 : 32|8@1+ (1,0) [0|255] "" Vector__XXX
 SG_ SDCR_a020_rxData2 m20 : 40|8@1+ (1,0) [0|255] "" Vector__XXX
 SG_ SDCR_a020_rxData3 m20 : 48|8@1+ (1,0) [0|255] "" Vector__XXX
 SG_ SDCR_a020_rxData4 m20 : 56|8@1+ (1,0) [0|255] "" Vector__XXX
 SG_ SDCR_a021_busBarTempC m21 : 16|8@1+ (1,-40) [-39|215] "DegC" Vector__XXX
 SG_ SDCR_a021_busBarTempA m21 : 24|8@1+ (1,-40) [-39|215] "DegC" Vector__XXX
 SG_ SDCR_a021_tempCVoltage m21 : 32|8@1+ (0.02,0) [0|5.1] "V" Vector__XXX
 SG_ SDCR_a021_tempAVoltage m21 : 40|8@1+ (0.02,0) [0|5.1] "V" Vector__XXX
 SG_ SDCR_a024_time m24 : 16|1@1+ (1,0) [0|1] "" Vector__XXX
 SG_ SDCR_a025_diSwitchingFromUart m25 : 16|1@1+ (1,0) [0|1] "" Vector__XXX
 SG_ SDCR_a025_diSwitchingPin m25 : 17|1@1+ (1,0) [0|1] "" Vector__XXX
 SG_ SDCR_a025_pmRunningPin m25 : 18|1@1+ (1,0) [0|1] "" Vector__XXX
 SG_ SDCR_a025_diUartMIA m25 : 19|1@1+ (1,0) [0|1] "" Vector__XXX
 SG_ SDCR_a025_HVBackupSupplyV m25 : 24|8@1+ (0.15,0) [0|38.25] "V" Vector__XXX
 SG_ SDCR_a025_boostRailV m25 : 32|8@1+ (0.15,0) [0|38.25] "V" Vector__XXX
 SG_ SDCR_a028_LVPowerState m28 : 16|1@1+ (1,0) [0|1] "" Vector__XXX
 SG_ SDCR_a029_uartCommsMissing m29 : 16|1@1+ (1,0) [0|1] "" Vector__XXX
 SG_ SDCR_a029_canCommsMissing m29 : 17|1@1+ (1,0) [0|1] "" Vector__XXX
 SG_ SDCR_a029_lvState m29 : 18|2@1+ (1,0) [0|3] "" Vector__XXX
 SG_ SDCR_a034_Ia m34 : 16|16@1- (0.1,0) [-3276.8|3276.7] "A" Vector__XXX
 SG_ SDCR_a034_Ib m34 : 32|16@1- (0.1,0) [-3276.8|3276.7] "A" Vector__XXX

BO_ 1787 SDCR_udsResponse: 8 SDCR
 SG_ SDCR_udsResponseData : 7|64@0+ (1,0) [0|1.84467440737e+19] "" Vector__XXX

BO_ 1835 TAS_alertLog: 8 TAS
 SG_ TAS_alertID M : 0|9@1+ (1,0) [0|511] "" Vector__XXX
 SG_ TAS_alertState : 15|1@1+ (1,0) [0|1] "" Vector__XXX
 SG_ TAS_a001_InternalWatchdog m1 : 16|1@1+ (1,0) [0|1] "" Vector__XXX
 SG_ TAS_a002_CPUUndervoltage m2 : 16|1@1+ (1,0) [0|1] "" Vector__XXX
 SG_ TAS_a002_PowerOnReset m2 : 17|1@1+ (1,0) [0|1] "" Vector__XXX
 SG_ TAS_a003_AssertID m3 : 16|16@1+ (1,0) [0|65535] "" Vector__XXX
 SG_ TAS_a003_LineNumber m3 : 32|16@1+ (1,0) [0|65535] "" Vector__XXX
 SG_ TAS_a003_Data m3 : 48|16@1+ (1,0) [0|65535] "" Vector__XXX
 SG_ TAS_a012_ClockError m12 : 16|1@1+ (1,0) [0|1] "" Vector__XXX
 SG_ TAS_a012_FlashError m12 : 17|1@1+ (1,0) [0|1] "" Vector__XXX
 SG_ TAS_a012_SoftwareReset m12 : 18|1@1+ (1,0) [0|1] "" Vector__XXX
 SG_ TAS_a012_CheckstopReset m12 : 19|1@1+ (1,0) [0|1] "" Vector__XXX
 SG_ TAS_a012_DebugReset m12 : 20|1@1+ (1,0) [0|1] "" Vector__XXX
 SG_ TAS_a012_ExternalReset m12 : 21|1@1+ (1,0) [0|1] "" Vector__XXX
 SG_ TAS_a021_Task1msLate m21 : 16|1@1+ (1,0) [0|1] "" Vector__XXX
 SG_ TAS_a021_Task1msStarved m21 : 17|1@1+ (1,0) [0|1] "" Vector__XXX
 SG_ TAS_a021_Task1msMissed m21 : 18|1@1+ (1,0) [0|1] "" Vector__XXX
 SG_ TAS_a021_Task10msLate m21 : 19|1@1+ (1,0) [0|1] "" Vector__XXX
 SG_ TAS_a021_Task10msStarved m21 : 20|1@1+ (1,0) [0|1] "" Vector__XXX
 SG_ TAS_a021_Task10msMissed m21 : 21|1@1+ (1,0) [0|1] "" Vector__XXX
 SG_ TAS_a021_Task100msLate m21 : 22|1@1+ (1,0) [0|1] "" Vector__XXX
 SG_ TAS_a021_Task100msStarved m21 : 23|1@1+ (1,0) [0|1] "" Vector__XXX
 SG_ TAS_a021_Task100msMissed m21 : 24|1@1+ (1,0) [0|1] "" Vector__XXX
 SG_ TAS_a021_Task1000msLate m21 : 25|1@1+ (1,0) [0|1] "" Vector__XXX
 SG_ TAS_a021_Task1000msStarved m21 : 26|1@1+ (1,0) [0|1] "" Vector__XXX
 SG_ TAS_a021_Task1000msMissed m21 : 27|1@1+ (1,0) [0|1] "" Vector__XXX
 SG_ TAS_a022_TaskInitErrorCount m22 : 16|8@1+ (1,0) [0|255] "" Vector__XXX
 SG_ TAS_a022_TaskInitError0 m22 : 24|8@1+ (1,0) [0|255] "" Vector__XXX
 SG_ TAS_a022_TaskInitError1 m22 : 32|8@1+ (1,0) [0|255] "" Vector__XXX
 SG_ TAS_a022_TaskInitError2 m22 : 40|8@1+ (1,0) [0|255] "" Vector__XXX
 SG_ TAS_a022_TaskInitError3 m22 : 48|8@1+ (1,0) [0|255] "" Vector__XXX
 SG_ TAS_a022_TaskInitError4 m22 : 56|8@1+ (1,0) [0|255] "" Vector__XXX
 SG_ TAS_a025_vehicleLockAtCrash m25 : 16|1@1+ (1,0) [0|1] "" Vector__XXX
 SG_ TAS_a025_CANCrashIsActive m25 : 17|1@1+ (1,0) [0|1] "" Vector__XXX
 SG_ TAS_a025_appCrashIsActive m25 : 18|1@1+ (1,0) [0|1] "" Vector__XXX
 SG_ TAS_a025_lastCrashEvent m25 : 24|32@1+ (1,0) [0|4294967295] "" Vector__XXX
 SG_ TAS_a030_PWMdutyCycleFL m30 : 16|16@1+ (0.0025,0) [0|163.8375] "%" Vector__XXX
 SG_ TAS_a030_PWMfrequencyFL m30 : 32|16@1+ (0.025,0) [0|1638.375] "Hz" Vector__XXX
 SG_ TAS_a030_PWMfaultFL m30 : 48|4@1+ (1,0) [0|15] "" Vector__XXX
 SG_ TAS_a031_PWMdutyCycleFR m31 : 16|16@1+ (0.0025,0) [0|163.8375] "%" Vector__XXX
 SG_ TAS_a031_PWMfrequencyFR m31 : 32|16@1+ (0.025,0) [0|1638.375] "Hz" Vector__XXX
 SG_ TAS_a031_PWMfaultFR m31 : 48|4@1+ (1,0) [0|15] "" Vector__XXX
 SG_ TAS_a032_PWMdutyCycleRL m32 : 16|16@1+ (0.0025,0) [0|163.8375] "%" Vector__XXX
 SG_ TAS_a032_PWMfrequencyRL m32 : 32|16@1+ (0.025,0) [0|1638.375] "Hz" Vector__XXX
 SG_ TAS_a032_PWMfaultRL m32 : 48|4@1+ (1,0) [0|15] "" Vector__XXX
 SG_ TAS_a033_PWMdutyCycleRR m33 : 16|16@1+ (0.0025,0) [0|163.8375] "%" Vector__XXX
 SG_ TAS_a033_PWMfrequencyRR m33 : 32|16@1+ (0.025,0) [0|1638.375] "Hz" Vector__XXX
 SG_ TAS_a033_PWMfaultRR m33 : 48|4@1+ (1,0) [0|15] "" Vector__XXX
 SG_ TAS_a034_PWMdutyCycleFL m34 : 16|16@1+ (0.0025,0) [0|163.8375] "%" Vector__XXX
 SG_ TAS_a034_PWMfrequencyFL m34 : 32|16@1+ (0.025,0) [0|1638.375] "Hz" Vector__XXX
 SG_ TAS_a034_PWMfaultFL m34 : 48|4@1+ (1,0) [0|15] "" Vector__XXX
 SG_ TAS_a035_PWMdutyCycleFR m35 : 16|16@1+ (0.0025,0) [0|163.8375] "%" Vector__XXX
 SG_ TAS_a035_PWMfrequencyFR m35 : 32|16@1+ (0.025,0) [0|1638.375] "Hz" Vector__XXX
 SG_ TAS_a035_PWMfaultFR m35 : 48|4@1+ (1,0) [0|15] "" Vector__XXX
 SG_ TAS_a036_PWMdutyCycleRL m36 : 16|16@1+ (0.0025,0) [0|163.8375] "%" Vector__XXX
 SG_ TAS_a036_PWMfrequencyRL m36 : 32|16@1+ (0.025,0) [0|1638.375] "Hz" Vector__XXX
 SG_ TAS_a036_PWMfaultRL m36 : 48|4@1+ (1,0) [0|15] "" Vector__XXX
 SG_ TAS_a037_PWMdutyCycleRR m37 : 16|16@1+ (0.0025,0) [0|163.8375] "%" Vector__XXX
 SG_ TAS_a037_PWMfrequencyRR m37 : 32|16@1+ (0.025,0) [0|1638.375] "Hz" Vector__XXX
 SG_ TAS_a037_PWMfaultRR m37 : 48|4@1+ (1,0) [0|15] "" Vector__XXX
 SG_ TAS_a038_PWMdutyCycleFL m38 : 16|16@1+ (0.0025,0) [0|163.8375] "%" Vector__XXX
 SG_ TAS_a038_PWMfrequencyFL m38 : 32|16@1+ (0.025,0) [0|1638.375] "Hz" Vector__XXX
 SG_ TAS_a038_PWMfaultFL m38 : 48|4@1+ (1,0) [0|15] "" Vector__XXX
 SG_ TAS_a039_PWMdutyCycleFR m39 : 16|16@1+ (0.0025,0) [0|163.8375] "%" Vector__XXX
 SG_ TAS_a039_PWMfrequencyFR m39 : 32|16@1+ (0.025,0) [0|1638.375] "Hz" Vector__XXX
 SG_ TAS_a039_PWMfaultFR m39 : 48|4@1+ (1,0) [0|15] "" Vector__XXX
 SG_ TAS_a040_PWMdutyCycleRL m40 : 16|16@1+ (0.0025,0) [0|163.8375] "%" Vector__XXX
 SG_ TAS_a040_PWMfrequencyRL m40 : 32|16@1+ (0.025,0) [0|1638.375] "Hz" Vector__XXX
 SG_ TAS_a040_PWMfaultRL m40 : 48|4@1+ (1,0) [0|15] "" Vector__XXX
 SG_ TAS_a041_PWMdutyCycleRR m41 : 16|16@1+ (0.0025,0) [0|163.8375] "%" Vector__XXX
 SG_ TAS_a041_PWMfrequencyRR m41 : 32|16@1+ (0.025,0) [0|1638.375] "Hz" Vector__XXX
 SG_ TAS_a041_PWMfaultRR m41 : 48|4@1+ (1,0) [0|15] "" Vector__XXX
 SG_ TAS_a070_voltage12V m70 : 16|16@1+ (0.001,0) [0|65.535] "V" Vector__XXX
 SG_ TAS_a071_voltage12V m71 : 16|16@1+ (0.001,0) [0|65.535] "V" Vector__XXX
 SG_ TAS_a072_voltage5VOnBoard m72 : 16|16@1+ (0.001,0) [0|65.535] "V" Vector__XXX
 SG_ TAS_a073_voltage5VOnBoard m73 : 16|16@1+ (0.001,0) [0|65.535] "V" Vector__XXX
 SG_ TAS_a074_voltage5VOffBoard m74 : 16|16@1+ (0.001,0) [0|65.535] "V" Vector__XXX
 SG_ TAS_a075_voltage5VOffBoard m75 : 16|16@1+ (0.001,0) [0|65.535] "V" Vector__XXX
 SG_ TAS_a076_voltage5VOffBoard m76 : 16|16@1+ (0.001,0) [0|65.535] "V" Vector__XXX
 SG_ TAS_a077_sensorVoltage m77 : 16|16@1+ (0.001,0) [0|65.535] "V" Vector__XXX
 SG_ TAS_a077_sensorRefVoltage m77 : 32|16@1+ (0.001,0) [0|65.535] "V" Vector__XXX
 SG_ TAS_a078_sensorVoltage m78 : 16|16@1+ (0.001,0) [0|65.535] "V" Vector__XXX
 SG_ TAS_a078_sensorRefVoltage m78 : 32|16@1+ (0.001,0) [0|65.535] "V" Vector__XXX
 SG_ TAS_a080_voltage5VHeight m80 : 16|16@1+ (0.001,0) [0|65.535] "V" Vector__XXX
 SG_ TAS_a081_voltage5VHeight m81 : 16|16@1+ (0.001,0) [0|65.535] "V" Vector__XXX
 SG_ TAS_a082_voltage5VHeight m82 : 16|16@1+ (0.001,0) [0|65.535] "V" Vector__XXX
 SG_ TAS_a083_voltage5VAnalog m83 : 16|16@1+ (0.001,0) [0|65.535] "V" Vector__XXX
 SG_ TAS_a084_voltage5VAnalog m84 : 16|16@1+ (0.001,0) [0|65.535] "V" Vector__XXX
 SG_ TAS_a085_voltage5VAnalog m85 : 16|16@1+ (0.001,0) [0|65.535] "V" Vector__XXX
 SG_ TAS_a086_voltage12VSwitched m86 : 16|16@1+ (0.001,0) [0|65.535] "V" Vector__XXX
 SG_ TAS_a087_voltage12VSwitched m87 : 16|16@1+ (0.001,0) [0|65.535] "V" Vector__XXX
 SG_ TAS_a093_readError m93 : 16|1@1+ (1,0) [0|1] "" Vector__XXX
 SG_ TAS_a093_IVOR2Exception m93 : 17|1@1+ (1,0) [0|1] "" Vector__XXX
 SG_ TAS_a098_VCFRONT_LVPowerState_MI m98 : 16|1@1+ (1,0) [0|1] "" Vector__XXX
 SG_ TAS_a098_VCFRONT_sensors_MIA m98 : 17|1@1+ (1,0) [0|1] "" Vector__XXX
 SG_ TAS_a098_VCFRONT_status_MIA m98 : 18|1@1+ (1,0) [0|1] "" Vector__XXX
 SG_ TAS_a098_VCFRONT_systemStatus_MI m98 : 19|1@1+ (1,0) [0|1] "" Vector__XXX
 SG_ TAS_a098_VCFRONT_vehNm_MIA m98 : 20|1@1+ (1,0) [0|1] "" Vector__XXX
 SG_ TAS_a099_UI_chassisControl_MIA m99 : 16|1@1+ (1,0) [0|1] "" Vector__XXX
 SG_ TAS_a099_UI_driverAssistMapData_ m99 : 17|1@1+ (1,0) [0|1] "" Vector__XXX
 SG_ TAS_a099_UI_suspensionControl_MI m99 : 18|1@1+ (1,0) [0|1] "" Vector__XXX
 SG_ TAS_a099_UI_vehicleModes_MIA m99 : 19|1@1+ (1,0) [0|1] "" Vector__XXX
 SG_ TAS_a100_RCM_inertial1_MIA m100 : 16|1@1+ (1,0) [0|1] "" Vector__XXX
 SG_ TAS_a100_RCM_inertial2_MIA m100 : 17|1@1+ (1,0) [0|1] "" Vector__XXX
 SG_ TAS_a101_ESP_brakeTorque_MIA m101 : 16|1@1+ (1,0) [0|1] "" Vector__XXX
 SG_ TAS_a101_ESP_status_MIA m101 : 17|1@1+ (1,0) [0|1] "" Vector__XXX
 SG_ TAS_a101_ESP_wheelRotation_MIA m101 : 18|1@1+ (1,0) [0|1] "" Vector__XXX
 SG_ TAS_a102_DI_chassisControl_MIA m102 : 16|1@1+ (1,0) [0|1] "" Vector__XXX
 SG_ TAS_a102_DI_locStatus_MIA m102 : 17|1@1+ (1,0) [0|1] "" Vector__XXX
 SG_ TAS_a102_DI_speed_MIA m102 : 18|1@1+ (1,0) [0|1] "" Vector__XXX
 SG_ TAS_a102_DI_systemStatus_MIA m102 : 19|1@1+ (1,0) [0|1] "" Vector__XXX
 SG_ TAS_a102_DI_vehicleEstimates_MIA m102 : 20|1@1+ (1,0) [0|1] "" Vector__XXX
 SG_ TAS_a102_DIF_torque_MIA m102 : 21|1@1+ (1,0) [0|1] "" Vector__XXX
 SG_ TAS_a102_DIR_torque_MIA m102 : 22|1@1+ (1,0) [0|1] "" Vector__XXX
 SG_ TAS_a103_GTW_carConfig_MIA m103 : 16|1@1+ (1,0) [0|1] "" Vector__XXX
 SG_ TAS_a103_GTW_time_MIA m103 : 17|1@1+ (1,0) [0|1] "" Vector__XXX
 SG_ TAS_a103_GTW_vehNm_MIA m103 : 18|1@1+ (1,0) [0|1] "" Vector__XXX
 SG_ TAS_a103_GTW_vin_MIA m103 : 19|1@1+ (1,0) [0|1] "" Vector__XXX
 SG_ TAS_a164_detectedDamperSolenoid m164 : 16|3@1+ (1,0) [0|7] "" Vector__XXX
 SG_ TAS_a164_expectedDamperSolenoid m164 : 19|3@1+ (1,0) [0|7] "" Vector__XXX
 SG_ TAS_a165_damperValveFault m165 : 16|4@1+ (1,0) [0|15] "" Vector__XXX
 SG_ TAS_a166_damperValveFault m166 : 16|4@1+ (1,0) [0|15] "" Vector__XXX
 SG_ TAS_a167_damperValveFault m167 : 16|4@1+ (1,0) [0|15] "" Vector__XXX
 SG_ TAS_a168_damperValveFault m168 : 16|4@1+ (1,0) [0|15] "" Vector__XXX
 SG_ TAS_a169_damperValveFault m169 : 16|4@1+ (1,0) [0|15] "" Vector__XXX
 SG_ TAS_a170_damperValveFault m170 : 16|4@1+ (1,0) [0|15] "" Vector__XXX
 SG_ TAS_a171_damperValveFault m171 : 16|4@1+ (1,0) [0|15] "" Vector__XXX
 SG_ TAS_a172_damperValveFault m172 : 16|4@1+ (1,0) [0|15] "" Vector__XXX
 SG_ TAS_a173_heightDelta_mm m173 : 16|8@1+ (1,-128) [-128|127] "mm" Vector__XXX
 SG_ TAS_a174_heightDelta_mm m174 : 16|8@1+ (1,-128) [-128|127] "mm" Vector__XXX
 SG_ TAS_a175_heightDelta_mm m175 : 16|8@1+ (1,-128) [-128|127] "mm" Vector__XXX
 SG_ TAS_a176_heightDelta_mm m176 : 16|8@1+ (1,-128) [-128|127] "mm" Vector__XXX
 SG_ TAS_a190_a2bFaultType m190 : 16|4@1+ (1,0) [0|15] "" Vector__XXX
 SG_ TAS_a190_a2bInterruptType m190 : 24|8@1+ (1,0) [0|255] "" Vector__XXX
 SG_ TAS_a190_a2bFaultSource m190 : 32|2@1+ (1,0) [0|3] "" Vector__XXX
 SG_ TAS_a191_a2bFaultType m191 : 16|4@1+ (1,0) [0|15] "" Vector__XXX
 SG_ TAS_a191_a2bInterruptType m191 : 24|8@1+ (1,0) [0|255] "" Vector__XXX
 SG_ TAS_a191_a2bFaultSource m191 : 32|2@1+ (1,0) [0|3] "" Vector__XXX
 SG_ TAS_a192_rideHeightVelDspFL m192 : 16|5@1- (0.2,0) [-3.2|3] "mps" Vector__XXX
 SG_ TAS_a192_rideHeightVelDspFR m192 : 24|5@1- (0.2,0) [-3.2|3] "mps" Vector__XXX
 SG_ TAS_a192_rideHeightVelDspRL m192 : 32|5@1- (0.2,0) [-3.2|3] "mps" Vector__XXX
 SG_ TAS_a192_rideHeightVelDspRR m192 : 37|5@1- (0.2,0) [-3.2|3] "mps" Vector__XXX
 SG_ TAS_a192_rideHeightVelObserverFL m192 : 42|5@1- (0.2,0) [-3.2|3] "mps" Vector__XXX
 SG_ TAS_a192_rideHeightVelObserverFR m192 : 47|5@1- (0.2,0) [-3.2|3] "mps" Vector__XXX
 SG_ TAS_a192_rideHeightVelObserverRL m192 : 52|5@1- (0.2,0) [-3.2|3] "mps" Vector__XXX
 SG_ TAS_a192_rideHeightVelObserverRR m192 : 57|5@1- (0.2,0) [-3.2|3] "mps" Vector__XXX
 SG_ TAS_a192_alertVersion m192 : 62|2@1+ (1,0) [0|3] "" Vector__XXX
 SG_ TAS_a193_EPAS3P_sysStatus_MIA m193 : 16|1@1+ (1,0) [0|1] "" Vector__XXX
 SG_ TAS_a210_heightSensorDeltaFL m210 : 16|8@1+ (1,-128) [-128|127] "mm" Vector__XXX
 SG_ TAS_a210_heightSensorDeltaFR m210 : 24|8@1+ (1,-128) [-128|127] "mm" Vector__XXX
 SG_ TAS_a210_heightSensorDeltaRL m210 : 32|8@1+ (1,-128) [-128|127] "mm" Vector__XXX
 SG_ TAS_a210_heightSensorDeltaRR m210 : 40|8@1+ (1,-128) [-128|127] "mm" Vector__XXX
 SG_ TAS_a220_galleryPressure m220 : 16|8@1+ (0.1,0) [0|25.5] "bara" Vector__XXX
 SG_ TAS_a220_timeInExhaust m220 : 24|32@1+ (1,0) [0|4294967295] "ms" Vector__XXX
 SG_ TAS_a221_galleryPressureDelta m221 : 16|8@1+ (0.1,0) [0|25.5] "bar" Vector__XXX
 SG_ TAS_a221_timeInIdle m221 : 24|32@1+ (1,0) [0|4294967295] "ms" Vector__XXX
 SG_ TAS_a222_galleryPressureDelta m222 : 16|8@1+ (0.1,0) [0|25.5] "bar" Vector__XXX
 SG_ TAS_a223_galleryPressure m223 : 16|8@1+ (0.1,0) [0|25.5] "bara" Vector__XXX
 SG_ TAS_a223_valveOnFL m223 : 24|1@1+ (1,0) [0|1] "" Vector__XXX
 SG_ TAS_a223_valveOnFR m223 : 25|1@1+ (1,0) [0|1] "" Vector__XXX
 SG_ TAS_a223_valveOnRL m223 : 26|1@1+ (1,0) [0|1] "" Vector__XXX
 SG_ TAS_a223_valveOnRR m223 : 27|1@1+ (1,0) [0|1] "" Vector__XXX
 SG_ TAS_a223_valveOnReservoir m223 : 28|1@1+ (1,0) [0|1] "" Vector__XXX
 SG_ TAS_a224_galleryPressure m224 : 16|8@1+ (0.1,0) [0|25.5] "bara" Vector__XXX
 SG_ TAS_a224_valveOnFL m224 : 24|1@1+ (1,0) [0|1] "" Vector__XXX
 SG_ TAS_a224_valveOnFR m224 : 25|1@1+ (1,0) [0|1] "" Vector__XXX
 SG_ TAS_a224_valveOnRL m224 : 26|1@1+ (1,0) [0|1] "" Vector__XXX
 SG_ TAS_a224_valveOnRR m224 : 27|1@1+ (1,0) [0|1] "" Vector__XXX
 SG_ TAS_a224_valveOnReservoir m224 : 28|1@1+ (1,0) [0|1] "" Vector__XXX
 SG_ TAS_a225_galleryPressure m225 : 16|8@1+ (0.1,0) [0|25.5] "bara" Vector__XXX
 SG_ TAS_a226_PWMdutyCycleFL m226 : 16|16@1+ (0.0025,0) [0|163.8375] "%" Vector__XXX
 SG_ TAS_a226_PWMfrequencyFL m226 : 32|16@1+ (0.025,0) [0|1638.375] "Hz" Vector__XXX
 SG_ TAS_a226_PWMfaultFL m226 : 48|4@1+ (1,0) [0|15] "" Vector__XXX
 SG_ TAS_a227_PWMdutyCycleFR m227 : 16|16@1+ (0.0025,0) [0|163.8375] "%" Vector__XXX
 SG_ TAS_a227_PWMfrequencyFR m227 : 32|16@1+ (0.025,0) [0|1638.375] "Hz" Vector__XXX
 SG_ TAS_a227_PWMfaultFR m227 : 48|4@1+ (1,0) [0|15] "" Vector__XXX
 SG_ TAS_a228_PWMdutyCycleRL m228 : 16|16@1+ (0.0025,0) [0|163.8375] "%" Vector__XXX
 SG_ TAS_a228_PWMfrequencyRL m228 : 32|16@1+ (0.025,0) [0|1638.375] "Hz" Vector__XXX
 SG_ TAS_a228_PWMfaultRL m228 : 48|4@1+ (1,0) [0|15] "" Vector__XXX
 SG_ TAS_a229_PWMdutyCycleRR m229 : 16|16@1+ (0.0025,0) [0|163.8375] "%" Vector__XXX
 SG_ TAS_a229_PWMfrequencyRR m229 : 32|16@1+ (0.025,0) [0|1638.375] "Hz" Vector__XXX
 SG_ TAS_a229_PWMfaultRR m229 : 48|4@1+ (1,0) [0|15] "" Vector__XXX
 SG_ TAS_a232_detectedSuspensionType m232 : 16|3@1+ (1,0) [0|7] "" Vector__XXX
 SG_ TAS_a232_expectedSuspensionType m232 : 19|3@1+ (1,0) [0|7] "" Vector__XXX
 SG_ TAS_a234_detectedDamperHydraulic m234 : 16|2@1+ (1,0) [0|3] "" Vector__XXX
 SG_ TAS_a234_expectedDamperHydraulic m234 : 18|2@1+ (1,0) [0|3] "" Vector__XXX
 SG_ TAS_a240_highAdjustCountRatio m240 : 16|1@1+ (1,0) [0|1] "" Vector__XXX
 SG_ TAS_a240_highAdjustTimeRatio m240 : 17|1@1+ (1,0) [0|1] "" Vector__XXX
 SG_ TAS_a240_highCrossPressure m240 : 18|1@1+ (1,0) [0|1] "" Vector__XXX
 SG_ TAS_a240_highCompExhTimeRatio m240 : 19|1@1+ (1,0) [0|1] "" Vector__XXX
 SG_ TAS_a240_adjustCountRatioSpring m240 : 20|3@1+ (1,0) [0|7] "" Vector__XXX
 SG_ TAS_a240_adjustCountRatio m240 : 24|8@1+ (0.02952756,0) [0|7.50000024] "InflateCount/DeflateCount" Vector__XXX
 SG_ TAS_a240_adjustTimeRatioSpring m240 : 32|3@1+ (1,0) [0|7] "" Vector__XXX
 SG_ TAS_a240_adjustTimeRatio m240 : 40|8@1+ (0.02952756,0) [0|7.50000024] "InflateTime/DeflateTime" Vector__XXX
 SG_ TAS_a240_compExhTimeRatio m240 : 48|8@1+ (0.0294117648154,0) [0|7.50000002793] "CompressorTime/ExhaustTime" Vector__XXX
 SG_ TAS_a240_crossPressure m240 : 56|8@1- (0.1,0) [-12.8|12.7] "bara/bara" Vector__XXX
 SG_ TAS_a285_twistLevel m285 : 16|8@1+ (1,-128) [-128|127] "mm" Vector__XXX
 SG_ TAS_a290_twistLevel m290 : 16|8@1+ (1,-128) [-128|127] "mm" Vector__XXX
 SG_ TAS_a291_frontAxleHeight m291 : 16|8@1+ (1,-128) [-128|127] "mm" Vector__XXX
 SG_ TAS_a292_rearAxleHeight m292 : 16|8@1+ (1,-128) [-128|127] "mm" Vector__XXX
 SG_ TAS_a293_frontAxleHeight m293 : 16|8@1+ (1,-128) [-128|127] "mm" Vector__XXX
 SG_ TAS_a294_rearAxleHeight m294 : 16|8@1+ (1,-128) [-128|127] "mm" Vector__XXX
 SG_ TAS_a295_targetHeight m295 : 16|8@1+ (1,-128) [-128|127] "mm" Vector__XXX
 SG_ TAS_a296_detectedChassisType m296 : 16|3@1+ (1,0) [0|7] "" Vector__XXX
 SG_ TAS_a296_expectedChassisType m296 : 19|3@1+ (1,0) [0|7] "" Vector__XXX
 SG_ TAS_a319_detectedDrivetrainType m319 : 16|2@1+ (1,0) [0|3] "" Vector__XXX
 SG_ TAS_a319_expectedDrivetrainType m319 : 18|2@1+ (1,0) [0|3] "" Vector__XXX

BO_ 852 TAS_alertMatrix: 8 TAS
 SG_ TAS_matrixIndex M : 0|4@1+ (1,0) [0|15] "" Vector__XXX
 SG_ TAS_a001_WatchdogReset m0 : 4|1@1+ (1,0) [0|1] "" Vector__XXX
 SG_ TAS_a002_PowerLossReset m0 : 5|1@1+ (1,0) [0|1] "" Vector__XXX
 SG_ TAS_a003_SWAssertion m0 : 6|1@1+ (1,0) [0|1] "" Vector__XXX
 SG_ TAS_a012_CPUReset m0 : 15|1@1+ (1,0) [0|1] "" Vector__XXX
 SG_ TAS_a015_NVMMError m0 : 18|1@1+ (1,0) [0|1] "" Vector__XXX
 SG_ TAS_a016_NVMMRecordError m0 : 19|1@1+ (1,0) [0|1] "" Vector__XXX
 SG_ TAS_a021_TaskSchedulerError m0 : 24|1@1+ (1,0) [0|1] "" Vector__XXX
 SG_ TAS_a022_TaskInitError m0 : 25|1@1+ (1,0) [0|1] "" Vector__XXX
 SG_ TAS_a023_rtosResetRequested m0 : 26|1@1+ (1,0) [0|1] "" Vector__XXX
 SG_ TAS_a024_prefetchAbort m0 : 27|1@1+ (1,0) [0|1] "" Vector__XXX
 SG_ TAS_a025_CrashEvent m0 : 28|1@1+ (1,0) [0|1] "" Vector__XXX
 SG_ TAS_a030_PWMerrorFL m0 : 33|1@1+ (1,0) [0|1] "" Vector__XXX
 SG_ TAS_a031_PWMerrorFR m0 : 34|1@1+ (1,0) [0|1] "" Vector__XXX
 SG_ TAS_a032_PWMerrorRL m0 : 35|1@1+ (1,0) [0|1] "" Vector__XXX
 SG_ TAS_a033_PWMerrorRR m0 : 36|1@1+ (1,0) [0|1] "" Vector__XXX
 SG_ TAS_a034_PWMshortFL m0 : 37|1@1+ (1,0) [0|1] "" Vector__XXX
 SG_ TAS_a035_PWMshortFR m0 : 38|1@1+ (1,0) [0|1] "" Vector__XXX
 SG_ TAS_a036_PWMshortRL m0 : 39|1@1+ (1,0) [0|1] "" Vector__XXX
 SG_ TAS_a037_PWMshortRR m0 : 40|1@1+ (1,0) [0|1] "" Vector__XXX
 SG_ TAS_a038_PWMopenFL m0 : 41|1@1+ (1,0) [0|1] "" Vector__XXX
 SG_ TAS_a039_PWMopenFR m0 : 42|1@1+ (1,0) [0|1] "" Vector__XXX
 SG_ TAS_a040_PWMopenRL m0 : 43|1@1+ (1,0) [0|1] "" Vector__XXX
 SG_ TAS_a041_PWMopenRR m0 : 44|1@1+ (1,0) [0|1] "" Vector__XXX
 SG_ TAS_a043_Task1msError m0 : 46|1@1+ (1,0) [0|1] "" Vector__XXX
 SG_ TAS_a044_Task10msError m0 : 47|1@1+ (1,0) [0|1] "" Vector__XXX
 SG_ TAS_a045_Task100msError m0 : 48|1@1+ (1,0) [0|1] "" Vector__XXX
 SG_ TAS_a046_Task1000msError m0 : 49|1@1+ (1,0) [0|1] "" Vector__XXX
 SG_ TAS_a061_XCPConnected m1 : 4|1@1+ (1,0) [0|1] "" Vector__XXX
 SG_ TAS_a062_XCPWasConnected m1 : 5|1@1+ (1,0) [0|1] "" Vector__XXX
 SG_ TAS_a063_abortFault m1 : 6|1@1+ (1,0) [0|1] "" Vector__XXX
 SG_ TAS_a064_abortFaultExt m1 : 7|1@1+ (1,0) [0|1] "" Vector__XXX
 SG_ TAS_a065_ahbWriteFault m1 : 8|1@1+ (1,0) [0|1] "" Vector__XXX
 SG_ TAS_a066_undefinedInstructionAbo m1 : 9|1@1+ (1,0) [0|1] "" Vector__XXX
 SG_ TAS_a067_reservedHandlerAbort m1 : 10|1@1+ (1,0) [0|1] "" Vector__XXX
 SG_ TAS_a070_underVoltage12V m1 : 13|1@1+ (1,0) [0|1] "" Vector__XXX
 SG_ TAS_a071_overVoltage12V m1 : 14|1@1+ (1,0) [0|1] "" Vector__XXX
 SG_ TAS_a072_shortCircuit5VOnBoard m1 : 15|1@1+ (1,0) [0|1] "" Vector__XXX
 SG_ TAS_a073_underVoltage5VOnBoard m1 : 16|1@1+ (1,0) [0|1] "" Vector__XXX
 SG_ TAS_a074_shortCircuit5VOffBoard m1 : 17|1@1+ (1,0) [0|1] "" Vector__XXX
 SG_ TAS_a075_underVoltage5VOffBoard m1 : 18|1@1+ (1,0) [0|1] "" Vector__XXX
 SG_ TAS_a076_overVoltage5VOffBoard m1 : 19|1@1+ (1,0) [0|1] "" Vector__XXX
 SG_ TAS_a077_pressureSigVTooLow m1 : 20|1@1+ (1,0) [0|1] "" Vector__XXX
 SG_ TAS_a078_pressureSigVTooHigh m1 : 21|1@1+ (1,0) [0|1] "" Vector__XXX
 SG_ TAS_a080_shortCircuit5VHeight m1 : 23|1@1+ (1,0) [0|1] "" Vector__XXX
 SG_ TAS_a081_underVoltage5VHeight m1 : 24|1@1+ (1,0) [0|1] "" Vector__XXX
 SG_ TAS_a082_overVoltage5VHeight m1 : 25|1@1+ (1,0) [0|1] "" Vector__XXX
 SG_ TAS_a083_shortCircuit5VAnalog m1 : 26|1@1+ (1,0) [0|1] "" Vector__XXX
 SG_ TAS_a084_underVoltage5VAnalog m1 : 27|1@1+ (1,0) [0|1] "" Vector__XXX
 SG_ TAS_a085_overVoltage5VAnalog m1 : 28|1@1+ (1,0) [0|1] "" Vector__XXX
 SG_ TAS_a086_underVoltage12VSwtchd m1 : 29|1@1+ (1,0) [0|1] "" Vector__XXX
 SG_ TAS_a087_overVoltage12VSwtchd m1 : 30|1@1+ (1,0) [0|1] "" Vector__XXX
 SG_ TAS_a093_OTPError m1 : 36|1@1+ (1,0) [0|1] "" Vector__XXX
 SG_ TAS_a098_VCFRONT_MIA m1 : 41|1@1+ (1,0) [0|1] "" Vector__XXX
 SG_ TAS_a099_UI_MIA m1 : 42|1@1+ (1,0) [0|1] "" Vector__XXX
 SG_ TAS_a100_RCM_MIA m1 : 43|1@1+ (1,0) [0|1] "" Vector__XXX
 SG_ TAS_a101_ESP_MIA m1 : 44|1@1+ (1,0) [0|1] "" Vector__XXX
 SG_ TAS_a102_DI_MIA m1 : 45|1@1+ (1,0) [0|1] "" Vector__XXX
 SG_ TAS_a103_GTW_MIA m1 : 46|1@1+ (1,0) [0|1] "" Vector__XXX
 SG_ TAS_a105_ECUDebugMode m1 : 48|1@1+ (1,0) [0|1] "" Vector__XXX
 SG_ TAS_a106_HighCPULoad m1 : 49|1@1+ (1,0) [0|1] "" Vector__XXX
 SG_ TAS_a107_HighStackUsage m1 : 50|1@1+ (1,0) [0|1] "" Vector__XXX
 SG_ TAS_a150_accelAvgImplausible_FL_ m2 : 33|1@1+ (1,0) [0|1] "" Vector__XXX
 SG_ TAS_a151_accelAvgImplausible_FL_ m2 : 34|1@1+ (1,0) [0|1] "" Vector__XXX
 SG_ TAS_a152_accelAvgImplausible_FL_ m2 : 35|1@1+ (1,0) [0|1] "" Vector__XXX
 SG_ TAS_a153_accelAvgImplausible_FR_ m2 : 36|1@1+ (1,0) [0|1] "" Vector__XXX
 SG_ TAS_a154_accelAvgImplausible_FR_ m2 : 37|1@1+ (1,0) [0|1] "" Vector__XXX
 SG_ TAS_a155_accelAvgImplausible_FR_ m2 : 38|1@1+ (1,0) [0|1] "" Vector__XXX
 SG_ TAS_a156_accelAvgImplausible_RL_ m2 : 39|1@1+ (1,0) [0|1] "" Vector__XXX
 SG_ TAS_a157_accelAvgImplausible_RL_ m2 : 40|1@1+ (1,0) [0|1] "" Vector__XXX
 SG_ TAS_a158_accelAvgImplausible_RL_ m2 : 41|1@1+ (1,0) [0|1] "" Vector__XXX
 SG_ TAS_a159_accelAvgImplausible_RR_ m2 : 42|1@1+ (1,0) [0|1] "" Vector__XXX
 SG_ TAS_a160_accelAvgImplausible_RR_ m2 : 43|1@1+ (1,0) [0|1] "" Vector__XXX
 SG_ TAS_a161_accelAvgImplausible_RR_ m2 : 44|1@1+ (1,0) [0|1] "" Vector__XXX
 SG_ TAS_a164_damperSolenoidMismatch m2 : 47|1@1+ (1,0) [0|1] "" Vector__XXX
 SG_ TAS_a165_damperValveCompFL m2 : 48|1@1+ (1,0) [0|1] "" Vector__XXX
 SG_ TAS_a166_damperValveRbndFL m2 : 49|1@1+ (1,0) [0|1] "" Vector__XXX
 SG_ TAS_a167_damperValveCompFR m2 : 50|1@1+ (1,0) [0|1] "" Vector__XXX
 SG_ TAS_a168_damperValveRbndFR m2 : 51|1@1+ (1,0) [0|1] "" Vector__XXX
 SG_ TAS_a169_damperValveCompRL m2 : 52|1@1+ (1,0) [0|1] "" Vector__XXX
 SG_ TAS_a170_damperValveRbndRL m2 : 53|1@1+ (1,0) [0|1] "" Vector__XXX
 SG_ TAS_a171_damperValveCompRR m2 : 54|1@1+ (1,0) [0|1] "" Vector__XXX
 SG_ TAS_a172_damperValveRbndRR m2 : 55|1@1+ (1,0) [0|1] "" Vector__XXX
 SG_ TAS_a173_staticLeakDetectFL m2 : 56|1@1+ (1,0) [0|1] "" Vector__XXX
 SG_ TAS_a174_staticLeakDetectFR m2 : 57|1@1+ (1,0) [0|1] "" Vector__XXX
 SG_ TAS_a175_staticLeakDetectRL m2 : 58|1@1+ (1,0) [0|1] "" Vector__XXX
 SG_ TAS_a176_staticLeakDetectRR m2 : 59|1@1+ (1,0) [0|1] "" Vector__XXX
 SG_ TAS_a190_a2bFrontAxleFault m3 : 13|1@1+ (1,0) [0|1] "" Vector__XXX
 SG_ TAS_a191_a2bRearAxleFault m3 : 14|1@1+ (1,0) [0|1] "" Vector__XXX
 SG_ TAS_a192_rideHeightObserverDiver m3 : 15|1@1+ (1,0) [0|1] "" Vector__XXX
 SG_ TAS_a193_EPAS3P_MIA m3 : 16|1@1+ (1,0) [0|1] "" Vector__XXX
 SG_ TAS_a194_a2bFrontAxleDataError m3 : 17|1@1+ (1,0) [0|1] "" Vector__XXX
 SG_ TAS_a195_a2bRearAxleDataError m3 : 18|1@1+ (1,0) [0|1] "" Vector__XXX
 SG_ TAS_a196_adaptiveDampingUsingDSP m3 : 19|1@1+ (1,0) [0|1] "" Vector__XXX
 SG_ TAS_a197_invalidAdaptiveModeRequ m3 : 20|1@1+ (1,0) [0|1] "" Vector__XXX
 SG_ TAS_a200_jackModeActive m3 : 23|1@1+ (1,0) [0|1] "" Vector__XXX
 SG_ TAS_a201_low12VBattery m3 : 24|1@1+ (1,0) [0|1] "" Vector__XXX
 SG_ TAS_a210_outOfRangeCalibration m3 : 33|1@1+ (1,0) [0|1] "" Vector__XXX
 SG_ TAS_a211_noRideHeightCalib m3 : 34|1@1+ (1,0) [0|1] "" Vector__XXX
 SG_ TAS_a213_yellowWarningLamp m3 : 36|1@1+ (1,0) [0|1] "" Vector__XXX
 SG_ TAS_a214_redWarningLamp m3 : 37|1@1+ (1,0) [0|1] "" Vector__XXX
 SG_ TAS_a215_limpHomeMode10 m3 : 38|1@1+ (1,0) [0|1] "" Vector__XXX
 SG_ TAS_a216_limpHomeMode20 m3 : 39|1@1+ (1,0) [0|1] "" Vector__XXX
 SG_ TAS_a217_limpHomeMode30 m3 : 40|1@1+ (1,0) [0|1] "" Vector__XXX
 SG_ TAS_a218_limpHomeMode40 m3 : 41|1@1+ (1,0) [0|1] "" Vector__XXX
 SG_ TAS_a220_exhaustGalleryFault m3 : 43|1@1+ (1,0) [0|1] "" Vector__XXX
 SG_ TAS_a221_valveLeakDetected m3 : 44|1@1+ (1,0) [0|1] "" Vector__XXX
 SG_ TAS_a222_compressorPrefillFault m3 : 45|1@1+ (1,0) [0|1] "" Vector__XXX
 SG_ TAS_a223_blockedAirline m3 : 46|1@1+ (1,0) [0|1] "" Vector__XXX
 SG_ TAS_a224_openAirline m3 : 47|1@1+ (1,0) [0|1] "" Vector__XXX
 SG_ TAS_a225_galleryPressureTooHigh m3 : 48|1@1+ (1,0) [0|1] "" Vector__XXX
 SG_ TAS_a226_PWMfastDetectFL m3 : 49|1@1+ (1,0) [0|1] "" Vector__XXX
 SG_ TAS_a227_PWMfastDetectFR m3 : 50|1@1+ (1,0) [0|1] "" Vector__XXX
 SG_ TAS_a228_PWMfastDetectRL m3 : 51|1@1+ (1,0) [0|1] "" Vector__XXX
 SG_ TAS_a229_PWMfastDetectRR m3 : 52|1@1+ (1,0) [0|1] "" Vector__XXX
 SG_ TAS_a230_notifyGeofence m3 : 53|1@1+ (1,0) [0|1] "" Vector__XXX
 SG_ TAS_a231_notifyRoughRoadRaise m3 : 54|1@1+ (1,0) [0|1] "" Vector__XXX
 SG_ TAS_a232_suspensionTypeMismatch m3 : 55|1@1+ (1,0) [0|1] "" Vector__XXX
 SG_ TAS_a233_compressorStuckOn m3 : 56|1@1+ (1,0) [0|1] "" Vector__XXX
 SG_ TAS_a234_damperHydraulicMismatch m3 : 57|1@1+ (1,0) [0|1] "" Vector__XXX
 SG_ TAS_a240_airSpringLeak m3 : 63|1@1+ (1,0) [0|1] "" Vector__XXX
 SG_ TAS_a284_serviceRunModeActive m4 : 47|1@1+ (1,0) [0|1] "" Vector__XXX
 SG_ TAS_a285_twistSustainedUserVis m4 : 48|1@1+ (1,0) [0|1] "" Vector__XXX
 SG_ TAS_a286_driveCycleStats1 m4 : 49|1@1+ (1,0) [0|1] "" Vector__XXX
 SG_ TAS_a287_driveCycleStats2 m4 : 50|1@1+ (1,0) [0|1] "" Vector__XXX
 SG_ TAS_a288_driveCycleStats3 m4 : 51|1@1+ (1,0) [0|1] "" Vector__XXX
 SG_ TAS_a289_driveCycleStats4 m4 : 52|1@1+ (1,0) [0|1] "" Vector__XXX
 SG_ TAS_a290_twistSustainedAtSpeed m4 : 53|1@1+ (1,0) [0|1] "" Vector__XXX
 SG_ TAS_a291_frontAxleTooHigh m4 : 54|1@1+ (1,0) [0|1] "" Vector__XXX
 SG_ TAS_a292_rearAxleTooHigh m4 : 55|1@1+ (1,0) [0|1] "" Vector__XXX
 SG_ TAS_a293_frontAxleTooLow m4 : 56|1@1+ (1,0) [0|1] "" Vector__XXX
 SG_ TAS_a294_rearAxleTooLow m4 : 57|1@1+ (1,0) [0|1] "" Vector__XXX
 SG_ TAS_a295_targetHeightNotMet m4 : 58|1@1+ (1,0) [0|1] "" Vector__XXX
 SG_ TAS_a296_chassisTypeMismatch m4 : 59|1@1+ (1,0) [0|1] "" Vector__XXX
 SG_ TAS_a297_vinMismatch m4 : 60|1@1+ (1,0) [0|1] "" Vector__XXX
 SG_ TAS_a298_vinNotLearned m4 : 61|1@1+ (1,0) [0|1] "" Vector__XXX
 SG_ TAS_a299_offsetEstimateTooLarge m4 : 62|1@1+ (1,0) [0|1] "" Vector__XXX
 SG_ TAS_a300_offsetEstimateData1 m4 : 63|1@1+ (1,0) [0|1] "" Vector__XXX
 SG_ TAS_a301_offsetEstimateData2 m5 : 4|1@1+ (1,0) [0|1] "" Vector__XXX
 SG_ TAS_a303_massEstimateFrozen m5 : 6|1@1+ (1,0) [0|1] "" Vector__XXX
 SG_ TAS_a304_massEstimateFrozenData m5 : 7|1@1+ (1,0) [0|1] "" Vector__XXX
 SG_ TAS_a305_newEndstopPosition m5 : 8|1@1+ (1,0) [0|1] "" Vector__XXX
 SG_ TAS_a306_hardwareProtectFrozen m5 : 9|1@1+ (1,0) [0|1] "" Vector__XXX
 SG_ TAS_a307_endstopBoundaryComp m5 : 10|1@1+ (1,0) [0|1] "" Vector__XXX
 SG_ TAS_a308_endstopBoundaryRbnd m5 : 11|1@1+ (1,0) [0|1] "" Vector__XXX
 SG_ TAS_a309_controlFrozen m5 : 12|1@1+ (1,0) [0|1] "" Vector__XXX
 SG_ TAS_a310_controlFrozenData m5 : 13|1@1+ (1,0) [0|1] "" Vector__XXX
 SG_ TAS_a311_accelsMIA m5 : 14|1@1+ (1,0) [0|1] "" Vector__XXX
 SG_ TAS_a312_rotationalRatesMIA m5 : 15|1@1+ (1,0) [0|1] "" Vector__XXX
 SG_ TAS_a313_dampingCntrlDisabled m5 : 16|1@1+ (1,0) [0|1] "" Vector__XXX
 SG_ TAS_a314_dampingReduced m5 : 17|1@1+ (1,0) [0|1] "" Vector__XXX
 SG_ TAS_a315_pcbaHighTemp m5 : 18|1@1+ (1,0) [0|1] "" Vector__XXX
 SG_ TAS_a316_offsetsAccels m5 : 19|1@1+ (1,0) [0|1] "" Vector__XXX
 SG_ TAS_a317_offsetsRotationalRates m5 : 20|1@1+ (1,0) [0|1] "" Vector__XXX
 SG_ TAS_a318_dampingCntrlInputMIA m5 : 21|1@1+ (1,0) [0|1] "" Vector__XXX
 SG_ TAS_a319_drivetrainTypeMismatch m5 : 22|1@1+ (1,0) [0|1] "" Vector__XXX
 SG_ TAS_a320_offsetsRotationalRates m5 : 23|1@1+ (1,0) [0|1] "" Vector__XXX
 SG_ TAS_a321_speedBumpAttributes1 m5 : 24|1@1+ (1,0) [0|1] "" Vector__XXX
 SG_ TAS_a322_speedBumpAttributes2 m5 : 25|1@1+ (1,0) [0|1] "" Vector__XXX
 SG_ TAS_a332_levelingThresholds1 m5 : 35|1@1+ (1,0) [0|1] "" Vector__XXX
 SG_ TAS_a333_levelingThresholds2 m5 : 36|1@1+ (1,0) [0|1] "" Vector__XXX

BO_ 1627 TAS_udsResponse: 8 TAS
 SG_ TAS_udsResponseData : 7|64@0+ (1,0) [0|1.84467440737e+19] "" Vector__XXX

BO_ 1410 TCU_alertLog: 8 TCU
 SG_ TCU_alertID M : 0|3@1+ (1,0) [0|7] "" Vector__XXX
 SG_ TCU_alertState : 15|1@1+ (1,0) [0|1] "" Vector__XXX
 SG_ TCU_w001_FailCode m1 : 16|32@1+ (1,0) [0|4294967295] "" Vector__XXX
 SG_ TCU_w002_RejCause m2 : 16|32@1+ (1,0) [0|4294967295] "" Vector__XXX
 SG_ TCU_w003_CallFailCode m3 : 16|32@1+ (1,0) [0|4294967295] "" Vector__XXX
 SG_ TCU_w004_MSDFailCode m4 : 16|32@1+ (1,0) [0|4294967295] "" Vector__XXX
 SG_ TCU_w006_Count m6 : 16|32@1+ (1,0) [0|4294967295] "" Vector__XXX

BO_ 1472 TCU_alertMatrix1: 8 TCU
 SG_ TCU_w001_IMSRegistrationFailed : 0|1@1+ (1,0) [0|1] "" Vector__XXX
 SG_ TCU_w002_CellRegRejected : 1|1@1+ (1,0) [0|1] "" Vector__XXX
 SG_ TCU_w003_ECallFailed : 2|1@1+ (1,0) [0|1] "" Vector__XXX
 SG_ TCU_w004_MSDTransmissionFailed : 3|1@1+ (1,0) [0|1] "" Vector__XXX
 SG_ TCU_w005_SIMSlotError : 4|1@1+ (1,0) [0|1] "" Vector__XXX
 SG_ TCU_w006_MpssUnavailable : 5|1@1+ (1,0) [0|1] "" Vector__XXX

BO_ 1409 TCU_log: 8 TCU
 SG_ TCU_logMux M : 0|32@1+ (1,0) [0|4294967295] "" Vector__XXX
 SG_ TCU_cpuTemp m0 : 32|32@1+ (1,0) [0|4294967295] "C" Vector__XXX
 SG_ TCU_cpuUsage m1 : 32|32@1+ (1,0) [0|4294967295] "%" Vector__XXX
 SG_ TCU_mdmCoreTemperature m2 : 32|32@1+ (1,0) [0|4294967295] "C" Vector__XXX
 SG_ TCU_availableMemory m3 : 32|32@1+ (1,0) [0|4294967295] "KB" Vector__XXX
 SG_ TCU_pwm m4 : 32|32@1+ (1,0) [0|4294967295] "" Vector__XXX
 SG_ TCU_pwmcap m5 : 32|32@1+ (1,0) [0|4294967295] "" Vector__XXX
 SG_ TCU_totalResumes m6 : 32|32@1+ (1,0) [0|4294967295] "" Vector__XXX
 SG_ TCU_mdmUplinkQueueSize m7 : 32|32@1+ (1,0) [0|4294967295] "bytes" Vector__XXX
 SG_ TCU_mdmRSRP m8 : 32|32@1- (1,0) [-2147483648|2147483647] "dBm" Vector__XXX
 SG_ TCU_mdmSINR m9 : 32|32@1- (1,0) [-2147483648|2147483647] "dBm" Vector__XXX
 SG_ TCU_mdmUplinkAllowedRate m10 : 32|32@1+ (1,0) [0|4294967295] "Kbps" Vector__XXX
 SG_ TCU_mdmUplinkAvgRage m11 : 32|32@1+ (1,0) [0|4294967295] "" Vector__XXX
 SG_ TCU_mdmServiceState m12 : 32|32@1+ (1,0) [0|4294967295] "" Vector__XXX
 SG_ TCU_mdmIMSStatus m13 : 32|32@1+ (1,0) [0|4294967295] "" Vector__XXX
 SG_ TCU_mdmSIMStatus m14 : 32|32@1+ (1,0) [0|4294967295] "" Vector__XXX
 SG_ TCU_mdmBusyActive m15 : 32|32@1+ (1,0) [0|4294967294] "" Vector__XXX

BO_ 1408 TCU_status: 8 TCU
 SG_ TCU_statusMux M : 0|32@1+ (1,0) [0|4294967295] "" Vector__XXX
 SG_ TCU_wakeUpReason m0 : 32|32@1+ (1,0) [0|4294967294] "" Vector__XXX
 SG_ TCU_tcuCmdId m1 : 32|1@1+ (1,0) [0|1] "" Vector__XXX
 SG_ TCU_goingToSleep m2 : 32|32@1+ (1,0) [0|4294967294] "" Vector__XXX

BO_ 1631 TPMS_udsResponse: 8 TPMS
 SG_ TPMS_udsResponseData : 7|64@0+ (1,0) [0|1.84467440737e+19] "" Vector__XXX

BO_TX_BU_ 998 : RCU;
BO_TX_BU_ 831 : RCU;
BO_TX_BU_ 1344 : SCCM;
BO_TX_BU_ 1680 : SCCM;
BO_TX_BU_ 1531 : SDCR;
BO_TX_BU_ 1787 : SDCR;
BO_TX_BU_ 1835 : TAS;
BO_TX_BU_ 852 : TAS;
BO_TX_BU_ 1627 : TAS;
BO_TX_BU_ 1410 : TCU;
BO_TX_BU_ 1472 : TCU;
BO_TX_BU_ 1409 : TCU;
BO_TX_BU_ 1408 : TCU;
BO_TX_BU_ 1631 : TPMS;
CM_ BO_ 998 "RCU ECU message: alert matrix";
CM_ SG_ 998 RCU_matrixIndex "RCU ECU: matrix index";
CM_ SG_ 998 RCU_a001_valveDriverFault "RCU ECU: a001 valve driver fault";
CM_ SG_ 998 RCU_a002_solenoidValveFault "RCU ECU: a002 solenoid valve fault";
CM_ SG_ 998 RCU_a003_pumpMotorFault "RCU ECU: a003 pump motor fault";
CM_ SG_ 998 RCU_a004_supplyOvervoltage "RCU ECU: a004 supply overvoltage";
CM_ SG_ 998 RCU_a005_supplyUndervoltage "RCU ECU: a005 supply undervoltage";
CM_ SG_ 998 RCU_a006_wakeLineOpen "RCU ECU: a006 wake line open";
CM_ SG_ 998 RCU_a007_pressureSensorFault "RCU ECU: a007 pressure sensor fault";
CM_ SG_ 998 RCU_a008_pressureNotCalibrated "RCU ECU: a008 pressure not calibrated";
CM_ SG_ 998 RCU_a009_brakeFluidLow "RCU ECU: a009 brake fluid low";
CM_ SG_ 998 RCU_a010_pedalSensorFault "RCU ECU: a010 pedal sensor fault";
CM_ SG_ 998 RCU_a011_idbPedalTravelMismatch "RCU ECU: a011 idb pedal travel mismatch";
CM_ SG_ 998 RCU_a012_pedalSensorNotCal "RCU ECU: a012 pedal sensor not cal";
CM_ SG_ 998 RCU_a013_mcuGenericFault "RCU ECU: a013 mcu generic fault";
CM_ SG_ 998 RCU_a014_asicTempHigh "RCU ECU: a014 asic temp high";
CM_ SG_ 998 RCU_a015_fluidLeakDetected "RCU ECU: a015 fluid leak detected";
CM_ SG_ 998 RCU_a016_partyBusOff "RCU ECU: a016 party bus off";
CM_ SG_ 998 RCU_a017_chassisBusOff "RCU ECU: a017 chassis bus off";
CM_ SG_ 998 RCU_a018_DItorquePathFaulted "RCU ECU: a018 d itorque path faulted";
CM_ SG_ 998 RCU_a019_DItorquePathActive "RCU ECU: a019 d itorque path active";
CM_ SG_ 998 RCU_a020_BBstatusDLC "RCU ECU: a020 b bstatus DLC";
CM_ SG_ 998 RCU_a021_BBstatusChecksum "RCU ECU: a021 b bstatus checksum";
CM_ SG_ 998 RCU_a022_BBstatusCounter "RCU ECU: a022 b bstatus counter";
CM_ SG_ 998 RCU_a023_IDBstatusDLC "RCU ECU: a023 ID bstatus DLC";
CM_ SG_ 998 RCU_a024_IDBstatusChecksum "RCU ECU: a024 ID bstatus checksum";
CM_ SG_ 998 RCU_a025_IDBstatusCounter "RCU ECU: a025 ID bstatus counter";
CM_ SG_ 998 RCU_a026_DIchassisControlDLC "RCU ECU: a026 d ichassis control DLC";
CM_ SG_ 998 RCU_a027_DIchassisCtrlChecksum "RCU ECU: a027 d ichassis ctrl checksum";
CM_ SG_ 998 RCU_a028_DIchassisControlCounter "RCU ECU: a028 d ichassis control counter";
CM_ SG_ 998 RCU_a029_PMstate2DLC "RCU ECU: a029 p mstate2 DLC";
CM_ SG_ 998 RCU_a030_PMstate2Checksum "RCU ECU: a030 p mstate2 checksum";
CM_ SG_ 998 RCU_a031_PMstate2Counter "RCU ECU: a031 p mstate2 counter";
CM_ SG_ 998 RCU_a032_VCFRONTLVPowerStateDLC "RCU ECU: a032 VCFRONTLV power state DLC";
CM_ SG_ 998 RCU_a033_VCFRONTLVPowerStateChec "RCU ECU: a033 VCFRONTLV power state checksum";
CM_ SG_ 998 RCU_a034_VCFRONTLVPowerStateCoun "RCU ECU: a034 VCFRONTLV power state counter";
CM_ SG_ 998 RCU_a035_IDBpcpInvalid "RCU ECU: a035 ID bpcp invalid";
CM_ SG_ 998 RCU_a036_IDBpspInvalid "RCU ECU: a036 ID bpsp invalid";
CM_ SG_ 998 RCU_a037_IDBinputRodStrokeInvali "RCU ECU: a037 ID binput rod stroke invalid";
CM_ SG_ 998 RCU_a038_DIsystemStatusDLC "RCU ECU: a038 d isystem status DLC";
CM_ SG_ 998 RCU_a039_DIaccelPosInvalid "RCU ECU: a039 d iaccel pos invalid";
CM_ SG_ 998 RCU_a040_DIgearInvalid "RCU ECU: a040 d igear invalid";
CM_ SG_ 998 RCU_a041_DIsystemStatusCounter "RCU ECU: a041 d isystem status counter";
CM_ SG_ 998 RCU_a042_DIsystemStatusChecksum "RCU ECU: a042 d isystem status checksum";
CM_ SG_ 998 RCU_a043_VCFRONTiBoosterLvStateI "RCU ECU: a043 VCFRON ti booster lv state invalid";
CM_ SG_ 998 RCU_a044_VCFRONTsensorsMIA "RCU ECU: a044 VCFRON tsensors MIA";
CM_ SG_ 998 RCU_a045_VCFRONTtempInvalid "RCU ECU: a045 VCFRON ttemp invalid";
CM_ SG_ 998 RCU_a046_brakeFluidLevelSNA "RCU ECU: a046 brake fluid level SNA";
CM_ SG_ 998 RCU_a047_ESPwheelSpeedsDLC "RCU ECU: a047 ES pwheel speeds DLC";
CM_ SG_ 998 RCU_a048_ESPFrLWSSLInvalid "RCU ECU: a048 ESP fr LWSSL invalid";
CM_ SG_ 998 RCU_a049_ESPFrRWSSLInvalid "RCU ECU: a049 ESP fr RWSSL invalid";
CM_ SG_ 998 RCU_a050_ESPReLWSSLInvalid "RCU ECU: a050 ESP re LWSSL invalid";
CM_ SG_ 998 RCU_a051_ESPReRWSSLInvalid "RCU ECU: a051 ESP re RWSSL invalid";
CM_ SG_ 998 RCU_a052_ESPwheelSpeedsCounter "RCU ECU: a052 ES pwheel speeds counter";
CM_ SG_ 998 RCU_a053_ESPwheelSpeedsChecksum "RCU ECU: a053 ES pwheel speeds checksum";
CM_ SG_ 998 RCU_a054_IDBcircuitPressFaulted "RCU ECU: a054 ID bcircuit press faulted";
CM_ SG_ 998 RCU_a055_IDBsimulatorPressFaulte "RCU ECU: a055 ID bsimulator press faulted";
CM_ SG_ 998 RCU_a056_redundantControllerIsMa "RCU ECU: a056 redundant controller is master";
CM_ SG_ 998 RCU_a057_PMebrCmdStateInvalid "RCU ECU: a057 p mebr cmd state invalid";
CM_ SG_ 998 RCU_a058_DIbrakeTorqueCommandAnd "RCU ECU: a058 d ibrake torque command and flag mismatch";
CM_ BO_ 831 "RCU ECU message: info";
CM_ SG_ 831 RCU_infoIndex "RCU ECU: info index";
CM_ SG_ 831 RCU_infoPcbaID "RCU ECU: info pcba ID";
CM_ SG_ 831 RCU_infoAssemblyID "RCU ECU: info assembly ID";
CM_ SG_ 831 RCU_infoUsageID "RCU ECU: info usage ID";
CM_ SG_ 831 RCU_infoSubUsageID "RCU ECU: info sub usage ID";
CM_ BO_ 1344 "Steering column control module message: alert log";
CM_ SG_ 1344 SCCM_alertID "Steering column control module: alert ID";
CM_ SG_ 1344 SCCM_alertState "Steering column control module: alert state";
CM_ SG_ 1344 SCCM_a003_debouncePosition "Steering column control module: a003 debounce position";
CM_ SG_ 1344 SCCM_a003_rawPosition "Steering column control module: a003 raw position";
CM_ SG_ 1344 SCCM_a003_errorPosition "Steering column control module: a003 error position";
CM_ SG_ 1344 SCCM_a003_adcValue "Steering column control module: a003 adc value";
CM_ SG_ 1344 SCCM_a004_debouncePosition "Steering column control module: a004 debounce position";
CM_ SG_ 1344 SCCM_a004_rawPosition "Steering column control module: a004 raw position";
CM_ SG_ 1344 SCCM_a004_errorPosition "Steering column control module: a004 error position";
CM_ SG_ 1344 SCCM_a004_adcValue "Steering column control module: a004 adc value";
CM_ SG_ 1344 SCCM_a005_debouncePosition "Steering column control module: a005 debounce position";
CM_ SG_ 1344 SCCM_a005_rawPosition "Steering column control module: a005 raw position";
CM_ SG_ 1344 SCCM_a005_errorPosition "Steering column control module: a005 error position";
CM_ SG_ 1344 SCCM_a005_adcValue "Steering column control module: a005 adc value";
CM_ SG_ 1344 SCCM_a006_debouncePosition "Steering column control module: a006 debounce position";
CM_ SG_ 1344 SCCM_a006_rawPosition "Steering column control module: a006 raw position";
CM_ SG_ 1344 SCCM_a006_errorPosition "Steering column control module: a006 error position";
CM_ SG_ 1344 SCCM_a006_adcValue "Steering column control module: a006 adc value";
CM_ SG_ 1344 SCCM_a007_debouncePosition "Steering column control module: a007 debounce position";
CM_ SG_ 1344 SCCM_a007_rawPosition "Steering column control module: a007 raw position";
CM_ SG_ 1344 SCCM_a007_errorPosition "Steering column control module: a007 error position";
CM_ SG_ 1344 SCCM_a007_adcValue1 "Steering column control module: a007 adc value1";
CM_ SG_ 1344 SCCM_a007_adcValue2 "Steering column control module: a007 adc value2";
CM_ SG_ 1344 SCCM_a008_debouncePosition "Steering column control module: a008 debounce position";
CM_ SG_ 1344 SCCM_a008_rawPosition "Steering column control module: a008 raw position";
CM_ SG_ 1344 SCCM_a008_errorPosition "Steering column control module: a008 error position";
CM_ SG_ 1344 SCCM_a008_adcValue1 "Steering column control module: a008 adc value1";
CM_ SG_ 1344 SCCM_a008_adcValue2 "Steering column control module: a008 adc value2";
CM_ SG_ 1344 SCCM_a009_debouncePosition "Steering column control module: a009 debounce position";
CM_ SG_ 1344 SCCM_a009_rawPosition "Steering column control module: a009 raw position";
CM_ SG_ 1344 SCCM_a009_errorPosition "Steering column control module: a009 error position";
CM_ SG_ 1344 SCCM_a009_adcValue1 "Steering column control module: a009 adc value1";
CM_ SG_ 1344 SCCM_a009_adcValue2 "Steering column control module: a009 adc value2";
CM_ SG_ 1344 SCCM_a010_debouncePosition "Steering column control module: a010 debounce position";
CM_ SG_ 1344 SCCM_a010_rawPosition "Steering column control module: a010 raw position";
CM_ SG_ 1344 SCCM_a010_errorPosition "Steering column control module: a010 error position";
CM_ SG_ 1344 SCCM_a010_adcValue1 "Steering column control module: a010 adc value1";
CM_ SG_ 1344 SCCM_a010_adcValue2 "Steering column control module: a010 adc value2";
CM_ SG_ 1344 SCCM_a011_debouncePosition "Steering column control module: a011 debounce position";
CM_ SG_ 1344 SCCM_a011_rawPosition "Steering column control module: a011 raw position";
CM_ SG_ 1344 SCCM_a011_errorPosition "Steering column control module: a011 error position";
CM_ SG_ 1344 SCCM_a011_adcValue1 "Steering column control module: a011 adc value1";
CM_ SG_ 1344 SCCM_a011_adcValue2 "Steering column control module: a011 adc value2";
CM_ SG_ 1344 SCCM_a012_debouncePosition "Steering column control module: a012 debounce position";
CM_ SG_ 1344 SCCM_a012_rawPosition "Steering column control module: a012 raw position";
CM_ SG_ 1344 SCCM_a012_errorPosition "Steering column control module: a012 error position";
CM_ SG_ 1344 SCCM_a012_adcValue1 "Steering column control module: a012 adc value1";
CM_ SG_ 1344 SCCM_a012_adcValue2 "Steering column control module: a012 adc value2";
CM_ SG_ 1344 SCCM_a013_voltage "Steering column control module: a013 voltage";
CM_ SG_ 1344 SCCM_a014_voltage "Steering column control module: a014 voltage";
CM_ SG_ 1344 SCCM_a015_intMainIndex "Steering column control module: a015 int main index";
CM_ SG_ 1344 SCCM_a015_intSubIndex "Steering column control module: a015 int sub index";
CM_ SG_ 1344 SCCM_a015_intMemIndex "Steering column control module: a015 int mem index";
CM_ SG_ 1344 SCCM_a016_mainAdcTest "Steering column control module: a016 main adc test";
CM_ SG_ 1344 SCCM_a016_mainCpuTest "Steering column control module: a016 main cpu test";
CM_ SG_ 1344 SCCM_a016_wdtTest "Steering column control module: a016 wdt test";
CM_ SG_ 1344 SCCM_a016_subCpuTest "Steering column control module: a016 sub cpu test";
CM_ SG_ 1344 SCCM_a016_subAdcTest "Steering column control module: a016 sub adc test";
CM_ SG_ 1344 SCCM_a017_mainRamTest "Steering column control module: a017 main ram test";
CM_ SG_ 1344 SCCM_a017_mainRomTest "Steering column control module: a017 main rom test";
CM_ SG_ 1344 SCCM_a017_stackHardLimitTest "Steering column control module: a017 stack hard limit test";
CM_ SG_ 1344 SCCM_a017_mainDataFlashTest "Steering column control module: a017 main data flash test";
CM_ SG_ 1344 SCCM_a017_subRamTest "Steering column control module: a017 sub ram test";
CM_ SG_ 1344 SCCM_a017_subRomTest "Steering column control module: a017 sub rom test";
CM_ SG_ 1344 SCCM_a017_subStackHardLimitTest "Steering column control module: a017 sub stack hard limit test";
CM_ SG_ 1344 SCCM_a017_svError "Steering column control module: a017 sv error";
CM_ SG_ 1344 SCCM_a018_internalSASState "Steering column control module: a018 internal SAS state";
CM_ SG_ 1344 SCCM_a019_internalSASState "Steering column control module: a019 internal SAS state";
CM_ SG_ 1344 SCCM_a020_internalSASState "Steering column control module: a020 internal SAS state";
CM_ SG_ 1344 SCCM_a021_adcValue1 "Steering column control module: a021 adc value1";
CM_ SG_ 1344 SCCM_a021_adcValue2 "Steering column control module: a021 adc value2";
CM_ SG_ 1344 SCCM_a021_adcValue3 "Steering column control module: a021 adc value3";
CM_ SG_ 1344 SCCM_a021_adcValue4 "Steering column control module: a021 adc value4";
CM_ SG_ 1344 SCCM_a021_adcValue5 "Steering column control module: a021 adc value5";
CM_ SG_ 1344 SCCM_a021_adcValue6 "Steering column control module: a021 adc value6";
CM_ SG_ 1344 SCCM_a022_adcValue1 "Steering column control module: a022 adc value1";
CM_ SG_ 1344 SCCM_a022_adcValue2 "Steering column control module: a022 adc value2";
CM_ SG_ 1344 SCCM_a022_adcValue3 "Steering column control module: a022 adc value3";
CM_ SG_ 1344 SCCM_a022_adcValue4 "Steering column control module: a022 adc value4";
CM_ SG_ 1344 SCCM_a022_adcValue5 "Steering column control module: a022 adc value5";
CM_ SG_ 1344 SCCM_a022_adcValue6 "Steering column control module: a022 adc value6";
CM_ SG_ 1344 SCCM_a023_adcValue1 "Steering column control module: a023 adc value1";
CM_ SG_ 1344 SCCM_a023_adcValue2 "Steering column control module: a023 adc value2";
CM_ SG_ 1344 SCCM_a023_adcValue3 "Steering column control module: a023 adc value3";
CM_ SG_ 1344 SCCM_a023_adcValue4 "Steering column control module: a023 adc value4";
CM_ SG_ 1344 SCCM_a023_adcValue5 "Steering column control module: a023 adc value5";
CM_ SG_ 1344 SCCM_a023_adcValue6 "Steering column control module: a023 adc value6";
CM_ SG_ 1344 SCCM_a024_adcValue1 "Steering column control module: a024 adc value1";
CM_ SG_ 1344 SCCM_a024_adcValue2 "Steering column control module: a024 adc value2";
CM_ SG_ 1344 SCCM_a024_adcValue3 "Steering column control module: a024 adc value3";
CM_ SG_ 1344 SCCM_a024_adcValue4 "Steering column control module: a024 adc value4";
CM_ SG_ 1344 SCCM_a024_adcValue5 "Steering column control module: a024 adc value5";
CM_ SG_ 1344 SCCM_a024_adcValue6 "Steering column control module: a024 adc value6";
CM_ SG_ 1344 SCCM_a025_taskState "Steering column control module: a025 task state";
CM_ SG_ 1344 SCCM_a026_debouncePosition "Steering column control module: a026 debounce position";
CM_ SG_ 1344 SCCM_a026_rawPosition "Steering column control module: a026 raw position";
CM_ SG_ 1344 SCCM_a026_errorPosition "Steering column control module: a026 error position";
CM_ SG_ 1344 SCCM_a026_adcValue1 "Steering column control module: a026 adc value1";
CM_ SG_ 1344 SCCM_a026_adcValue2 "Steering column control module: a026 adc value2";
CM_ SG_ 1344 SCCM_a027_debouncePosition "Steering column control module: a027 debounce position";
CM_ SG_ 1344 SCCM_a027_rawPosition "Steering column control module: a027 raw position";
CM_ SG_ 1344 SCCM_a027_errorPosition "Steering column control module: a027 error position";
CM_ SG_ 1344 SCCM_a027_adcValue1 "Steering column control module: a027 adc value1";
CM_ SG_ 1344 SCCM_a027_adcValue2 "Steering column control module: a027 adc value2";
CM_ SG_ 1344 SCCM_a028_debouncePosition "Steering column control module: a028 debounce position";
CM_ SG_ 1344 SCCM_a028_rawPosition "Steering column control module: a028 raw position";
CM_ SG_ 1344 SCCM_a028_errorPosition "Steering column control module: a028 error position";
CM_ SG_ 1344 SCCM_a028_adcValue1 "Steering column control module: a028 adc value1";
CM_ SG_ 1344 SCCM_a028_adcValue2 "Steering column control module: a028 adc value2";
CM_ SG_ 1344 SCCM_a029_debouncePosition "Steering column control module: a029 debounce position";
CM_ SG_ 1344 SCCM_a029_rawPosition "Steering column control module: a029 raw position";
CM_ SG_ 1344 SCCM_a029_errorPosition "Steering column control module: a029 error position";
CM_ SG_ 1344 SCCM_a029_adcValue1 "Steering column control module: a029 adc value1";
CM_ SG_ 1344 SCCM_a029_adcValue2 "Steering column control module: a029 adc value2";
CM_ SG_ 1344 SCCM_a061_voltage "Steering column control module: a061 voltage";
CM_ SG_ 1344 SCCM_a062_voltage "Steering column control module: a062 voltage";
CM_ SG_ 1344 SCCM_a063_UntrimmedAngle "Steering column control module: a063 untrimmed angle; raw 16383 = signal not available (SNA)";
CM_ SG_ 1344 SCCM_a064_Speed "Steering column control module: a064 speed; raw 16383 = signal not available (SNA)";
CM_ SG_ 1344 SCCM_a065_M1RawAngleCurrent "Steering column control module: a065 M1 raw angle current";
CM_ SG_ 1344 SCCM_a065_M1RawAnglePrevious "Steering column control module: a065 M1 raw angle previous";
CM_ SG_ 1344 SCCM_a065_M2RawAngleCurrent "Steering column control module: a065 M2 raw angle current";
CM_ SG_ 1344 SCCM_a065_M2RawAnglePrevious "Steering column control module: a065 M2 raw angle previous";
CM_ SG_ 1344 SCCM_a066_M1RawAngleCurrent "Steering column control module: a066 M1 raw angle current";
CM_ SG_ 1344 SCCM_a066_M1RawAnglePrevious "Steering column control module: a066 M1 raw angle previous";
CM_ SG_ 1344 SCCM_a066_M2RawAngleCurrent "Steering column control module: a066 M2 raw angle current";
CM_ SG_ 1344 SCCM_a066_M2RawAnglePrevious "Steering column control module: a066 M2 raw angle previous";
CM_ SG_ 1344 SCCM_a071_M1LogicBISTFailed "Steering column control module: a071 M1 logic BIST failed";
CM_ SG_ 1344 SCCM_a071_M1PowerOnReset "Steering column control module: a071 M1 power on reset";
CM_ SG_ 1344 SCCM_a071_M1UnderVoltage "Steering column control module: a071 M1 under voltage";
CM_ SG_ 1344 SCCM_a071_M1OverVoltage "Steering column control module: a071 M1 over voltage";
CM_ SG_ 1344 SCCM_a071_M1DualBitError "Steering column control module: a071 M1 dual bit error";
CM_ SG_ 1344 SCCM_a071_M1RefVoltageOutOfRange "Steering column control module: a071 M1 ref voltage out of range";
CM_ SG_ 1344 SCCM_a071_M1RegisterParityError "Steering column control module: a071 M1 register parity error";
CM_ SG_ 1344 SCCM_a071_M1OscillatorFreqError "Steering column control module: a071 M1 oscillator freq error";
CM_ SG_ 1344 SCCM_a071_M1SignalOutOfRange "Steering column control module: a071 M1 signal out of range";
CM_ SG_ 1344 SCCM_a071_M1TempOutOfRange "Steering column control module: a071 M1 temp out of range";
CM_ SG_ 1344 SCCM_a071_M1AngleMismatch "Steering column control module: a071 M1 angle mismatch";
CM_ SG_ 1344 SCCM_a071_M1RadiusOutOfRange "Steering column control module: a071 M1 radius out of range";
CM_ SG_ 1344 SCCM_a071_M2LogicBISTFailed "Steering column control module: a071 M2 logic BIST failed";
CM_ SG_ 1344 SCCM_a071_M2PowerOnReset "Steering column control module: a071 M2 power on reset";
CM_ SG_ 1344 SCCM_a071_M2UnderVoltage "Steering column control module: a071 M2 under voltage";
CM_ SG_ 1344 SCCM_a071_M2OverVoltage "Steering column control module: a071 M2 over voltage";
CM_ SG_ 1344 SCCM_a071_M2DualBitError "Steering column control module: a071 M2 dual bit error";
CM_ SG_ 1344 SCCM_a071_M2RefVoltageOutOfRange "Steering column control module: a071 M2 ref voltage out of range";
CM_ SG_ 1344 SCCM_a071_M2RegisterParityError "Steering column control module: a071 M2 register parity error";
CM_ SG_ 1344 SCCM_a071_M2OscillatorFreqError "Steering column control module: a071 M2 oscillator freq error";
CM_ SG_ 1344 SCCM_a071_M2SignalOutOfRange "Steering column control module: a071 M2 signal out of range";
CM_ SG_ 1344 SCCM_a071_M2TempOutOfRange "Steering column control module: a071 M2 temp out of range";
CM_ SG_ 1344 SCCM_a071_M2AngleMismatch "Steering column control module: a071 M2 angle mismatch";
CM_ SG_ 1344 SCCM_a071_M2RadiusOutOfRange "Steering column control module: a071 M2 radius out of range";
CM_ SG_ 1344 SCCM_a071_M1ProcessLogicFailed "Steering column control module: a071 M1 process logic failed";
CM_ SG_ 1344 SCCM_a071_M2ProcessLogicFailed "Steering column control module: a071 M2 process logic failed";
CM_ SG_ 1344 SCCM_a071_TSOSCHighFreqError "Steering column control module: a071 TSOSC high freq error";
CM_ SG_ 1344 SCCM_a071_TSOSCLowFreqError "Steering column control module: a071 TSOSC low freq error";
CM_ SG_ 1344 SCCM_a071_TSOPRStatMismatch "Steering column control module: a071 TSOPR stat mismatch";
CM_ SG_ 1344 SCCM_a071_TSCRCStatError "Steering column control module: a071 TSCRC stat error";
CM_ SG_ 1344 SCCM_a071_TSFrameStatError "Steering column control module: a071 TS frame stat error";
CM_ SG_ 1344 SCCM_a071_TSOverVoltage "Steering column control module: a071 TS over voltage";
CM_ SG_ 1344 SCCM_a071_TSUnderVoltage "Steering column control module: a071 TS under voltage";
CM_ SG_ 1344 SCCM_a071_TSPowerOnReset "Steering column control module: a071 TS power on reset";
CM_ SG_ 1344 SCCM_a071_TSLDOStatError "Steering column control module: a071 TSLDO stat error";
CM_ SG_ 1344 SCCM_a071_TSTempOutOfRange "Steering column control module: a071 TS temp out of range";
CM_ SG_ 1344 SCCM_a071_TSAlertIntegrityCheck "Steering column control module: a071 TS alert integrity check";
CM_ SG_ 1344 SCCM_a071_TSMemoryCRCError "Steering column control module: a071 TS memory CRC error";
CM_ SG_ 1344 SCCM_a071_TSAFECheck "Steering column control module: a071 TSAFE check";
CM_ SG_ 1344 SCCM_a071_TSADCCheck "Steering column control module: a071 TSADC check";
CM_ SG_ 1344 SCCM_a071_TSConfigFault "Steering column control module: a071 TS config fault";
CM_ SG_ 1344 SCCM_a072_M1CRCCalculated "Steering column control module: a072 M1 CRC calculated";
CM_ SG_ 1344 SCCM_a072_M1CRCReceived "Steering column control module: a072 M1 CRC received";
CM_ SG_ 1344 SCCM_a072_M2CRCCalculated "Steering column control module: a072 M2 CRC calculated";
CM_ SG_ 1344 SCCM_a072_M2CRCReceived "Steering column control module: a072 M2 CRC received";
CM_ SG_ 1344 SCCM_a072_TSCRCCalculated "Steering column control module: a072 TSCRC calculated";
CM_ SG_ 1344 SCCM_a072_TSCRCReceived "Steering column control module: a072 TSCRC received";
CM_ SG_ 1344 SCCM_a075_ClockOutOfRange "Steering column control module: a075 clock out of range";
CM_ SG_ 1344 SCCM_a075_ExtWatchdogTestFailed "Steering column control module: a075 ext watchdog test failed";
CM_ SG_ 1344 SCCM_a075_InterruptMonitorError "Steering column control module: a075 interrupt monitor error";
CM_ SG_ 1344 SCCM_a076_RAMTestFailed "Steering column control module: a076 RAM test failed";
CM_ SG_ 1344 SCCM_a076_NVMTestFailed "Steering column control module: a076 NVM test failed";
CM_ SG_ 1344 SCCM_a077_M1ExpectAngleCurrent "Steering column control module: a077 M1 expect angle current";
CM_ SG_ 1344 SCCM_a077_M1ExpectAnglePrevious "Steering column control module: a077 M1 expect angle previous";
CM_ SG_ 1344 SCCM_a077_M1AngleCurrent "Steering column control module: a077 M1 angle current";
CM_ SG_ 1344 SCCM_a077_M1AnglePrevious "Steering column control module: a077 M1 angle previous";
CM_ SG_ 1344 SCCM_a079_ChipTemperature "Steering column control module: a079 chip temperature";
CM_ SG_ 1344 SCCM_a081_StartupTestStatus "Steering column control module: a081 startup test status";
CM_ SG_ 1344 SCCM_a081_sCheckTestFailedData "Steering column control module: a081 s check test failed data";
CM_ SG_ 1344 SCCM_a081_sBootTestFailedData "Steering column control module: a081 s boot test failed data";
CM_ SG_ 1344 SCCM_a081_BISTTestFailedData "Steering column control module: a081 BIST test failed data";
CM_ SG_ 1344 SCCM_a082_RuntimeTestStatus "Steering column control module: a082 runtime test status";
CM_ SG_ 1344 SCCM_a082_sCheckTestFailedData "Steering column control module: a082 s check test failed data";
CM_ SG_ 1344 SCCM_a082_ArrayIntegrFailedData "Steering column control module: a082 array integr failed data";
CM_ SG_ 1344 SCCM_a121_turnIndicatorStalkAngl "Steering column control module: a121 turn indicator stalk angle";
CM_ SG_ 1344 SCCM_a121_turnIndicatorHallAngle "Steering column control module: a121 turn indicator hall angle";
CM_ SG_ 1344 SCCM_a122_turnIndicatorSpeed "Steering column control module: a122 turn indicator speed";
CM_ SG_ 1344 SCCM_a123_turnIndicatorStalkAngl "Steering column control module: a123 turn indicator stalk angle";
CM_ SG_ 1344 SCCM_a124_turnIndicatorStalkAngl "Steering column control module: a124 turn indicator stalk angle";
CM_ SG_ 1344 SCCM_a125_turnIndicatorHallAngle "Steering column control module: a125 turn indicator hall angle";
CM_ SG_ 1344 SCCM_a125_turnIndicatorVectorAng "Steering column control module: a125 turn indicator vector angle";
CM_ SG_ 1344 SCCM_a126_turnIndicatorXVectorOu "Steering column control module: a126 turn indicator x vector out of range";
CM_ SG_ 1344 SCCM_a126_turnIndicatorYVectorOu "Steering column control module: a126 turn indicator y vector out of range";
CM_ SG_ 1344 SCCM_a126_turnIndicatorZVectorOu "Steering column control module: a126 turn indicator z vector out of range";
CM_ SG_ 1344 SCCM_a126_turnIndicatorResu_0001 "Steering column control module: a126 turn indicator resultant out of range";
CM_ SG_ 1344 SCCM_a126_turnIndicatorXMagnitud "Steering column control module: a126 turn indicator x magnitude";
CM_ SG_ 1344 SCCM_a126_turnIndicatorYMagnitud "Steering column control module: a126 turn indicator y magnitude";
CM_ SG_ 1344 SCCM_a126_turnIndicatorZMagnitud "Steering column control module: a126 turn indicator z magnitude";
CM_ SG_ 1344 SCCM_a126_turnIndicatorResultant "Steering column control module: a126 turn indicator resultant magnitude";
CM_ BO_ 1680 "Steering column control module message: uds response";
CM_ SG_ 1680 SCCM_functionalResponseData_0 "Steering column control module: functional response data 0";
CM_ SG_ 1680 SCCM_functionalResponseData_1 "Steering column control module: functional response data 1";
CM_ SG_ 1680 SCCM_functionalResponseData_2 "Steering column control module: functional response data 2";
CM_ SG_ 1680 SCCM_functionalResponseData_3 "Steering column control module: functional response data 3";
CM_ SG_ 1680 SCCM_functionalResponseData_4 "Steering column control module: functional response data 4";
CM_ SG_ 1680 SCCM_functionalResponseData_5 "Steering column control module: functional response data 5";
CM_ SG_ 1680 SCCM_functionalResponseData_6 "Steering column control module: functional response data 6";
CM_ SG_ 1680 SCCM_functionalResponseData_7 "Steering column control module: functional response data 7";
CM_ BO_ 1531 "SDCR ECU message: alert log";
CM_ SG_ 1531 SDCR_alertID "SDCR ECU: alert ID";
CM_ SG_ 1531 SDCR_alertState "SDCR ECU: alert state";
CM_ SG_ 1531 SDCR_a001_pyroSenseV "SDCR ECU: a001 pyro sense v";
CM_ SG_ 1531 SDCR_a001_HVBackupSupplyV "SDCR ECU: a001 HV backup supply v";
CM_ SG_ 1531 SDCR_a001_boostRailV "SDCR ECU: a001 boost rail v";
CM_ SG_ 1531 SDCR_a001_expectedPyroV_max "SDCR ECU: a001 expected pyro v max";
CM_ SG_ 1531 SDCR_a001_expectedPyroV_min "SDCR ECU: a001 expected pyro v min";
CM_ SG_ 1531 SDCR_a001_fromState "SDCR ECU: a001 from state";
CM_ SG_ 1531 SDCR_a004_HVBackupSupplyV "SDCR ECU: a004 HV backup supply v";
CM_ SG_ 1531 SDCR_a004_boostRailV "SDCR ECU: a004 boost rail v";
CM_ SG_ 1531 SDCR_a004_diPresent "SDCR ECU: a004 di present";
CM_ SG_ 1531 SDCR_a004_pmRunningPin "SDCR ECU: a004 pm running pin";
CM_ SG_ 1531 SDCR_a006_pyroArmed "SDCR ECU: a006 pyro armed";
CM_ SG_ 1531 SDCR_a006_triggerReason_faultCur "SDCR ECU: a006 trigger reason fault currents";
CM_ SG_ 1531 SDCR_a006_triggerReason_hvBadAtS "SDCR ECU: a006 trigger reason hv bad at speed";
CM_ SG_ 1531 SDCR_a006_triggerReason_highBack "SDCR ECU: a006 trigger reason high back EMF";
CM_ SG_ 1531 SDCR_a006_faultCurrentsDetected "SDCR ECU: a006 fault currents detected";
CM_ SG_ 1531 SDCR_a006_diUartMIA "SDCR ECU: a006 di uart MIA";
CM_ SG_ 1531 SDCR_a006_pmRunningPin "SDCR ECU: a006 pm running pin";
CM_ SG_ 1531 SDCR_a006_hvPowerGood "SDCR ECU: a006 hv power good";
CM_ SG_ 1531 SDCR_a006_hvbkupPGoodPin "SDCR ECU: a006 hvbkup p good pin";
CM_ SG_ 1531 SDCR_a006_hvPowerNotGoodQualifie "SDCR ECU: a006 hv power not good qualified";
CM_ SG_ 1531 SDCR_a006_speedValid "SDCR ECU: a006 speed valid";
CM_ SG_ 1531 SDCR_a006_speedFromVoltage "SDCR ECU: a006 speed from voltage";
CM_ SG_ 1531 SDCR_a006_HVBackupSupplyV "SDCR ECU: a006 HV backup supply v";
CM_ SG_ 1531 SDCR_a006_boostRailV "SDCR ECU: a006 boost rail v";
CM_ SG_ 1531 SDCR_a006_maxAbsSpeed "SDCR ECU: a006 max abs speed";
CM_ SG_ 1531 SDCR_a006_vBat "SDCR ECU: a006 v bat";
CM_ SG_ 1531 SDCR_a007_faultReason_faultCurre "SDCR ECU: a007 fault reason fault currents at speed";
CM_ SG_ 1531 SDCR_a007_faultReason_unmitigate "SDCR ECU: a007 fault reason unmitigated UCR";
CM_ SG_ 1531 SDCR_a007_faultReason_propagatin "SDCR ECU: a007 fault reason propagating3 PS";
CM_ SG_ 1531 SDCR_a007_speedWasValid "SDCR ECU: a007 speed was valid";
CM_ SG_ 1531 SDCR_a007_imbalanceSeen "SDCR ECU: a007 imbalance seen";
CM_ SG_ 1531 SDCR_a007_ucrSeen "SDCR ECU: a007 ucr seen";
CM_ SG_ 1531 SDCR_a007_phaseVoltagePresent "SDCR ECU: a007 phase voltage present";
CM_ SG_ 1531 SDCR_a007_speedFromVoltage "SDCR ECU: a007 speed from voltage";
CM_ SG_ 1531 SDCR_a007_transientHandling "SDCR ECU: a007 transient handling";
CM_ SG_ 1531 SDCR_a007_maxAbsElcSpeed "SDCR ECU: a007 max abs elc speed";
CM_ SG_ 1531 SDCR_a007_avgIa "SDCR ECU: a007 avg ia";
CM_ SG_ 1531 SDCR_a007_avgIb "SDCR ECU: a007 avg ib";
CM_ SG_ 1531 SDCR_a007_maxAbsCurrents "SDCR ECU: a007 max abs currents";
CM_ SG_ 1531 SDCR_a008_dcLinkInfo "SDCR ECU: a008 dc link info";
CM_ SG_ 1531 SDCR_a009_diVersion "SDCR ECU: a009 di version";
CM_ SG_ 1531 SDCR_a009_sdcVersion "SDCR ECU: a009 sdc version";
CM_ SG_ 1531 SDCR_a010_pgood "SDCR ECU: a010 pgood";
CM_ SG_ 1531 SDCR_a010_boostRailV "SDCR ECU: a010 boost rail v";
CM_ SG_ 1531 SDCR_a010_Vref "SDCR ECU: a010 vref";
CM_ SG_ 1531 SDCR_a011_IaAvg "SDCR ECU: a011 ia avg";
CM_ SG_ 1531 SDCR_a011_IbAvg "SDCR ECU: a011 ib avg";
CM_ SG_ 1531 SDCR_a012_boostRailV "SDCR ECU: a012 boost rail v";
CM_ SG_ 1531 SDCR_a012_HVBackupSupplyV "SDCR ECU: a012 HV backup supply v";
CM_ SG_ 1531 SDCR_a012_vBat "SDCR ECU: a012 v bat";
CM_ SG_ 1531 SDCR_a012_vbkupGoodFdbk "SDCR ECU: a012 vbkup good fdbk";
CM_ SG_ 1531 SDCR_a013_boostRailV "SDCR ECU: a013 boost rail v";
CM_ SG_ 1531 SDCR_a013_HVBackupSupplyV "SDCR ECU: a013 HV backup supply v";
CM_ SG_ 1531 SDCR_a013_vBat "SDCR ECU: a013 v bat";
CM_ SG_ 1531 SDCR_a013_vbkupGoodFdbk "SDCR ECU: a013 vbkup good fdbk";
CM_ SG_ 1531 SDCR_a014_reason_vBusShortedLow "SDCR ECU: a014 reason v bus shorted low";
CM_ SG_ 1531 SDCR_a014_reason_vBusShortedHigh "SDCR ECU: a014 reason v bus shorted high";
CM_ SG_ 1531 SDCR_a014_boostRailV "SDCR ECU: a014 boost rail v";
CM_ SG_ 1531 SDCR_a014_HVBackupSupplyV "SDCR ECU: a014 HV backup supply v";
CM_ SG_ 1531 SDCR_a014_vBat "SDCR ECU: a014 v bat";
CM_ SG_ 1531 SDCR_a014_vbkupGoodFdbk "SDCR ECU: a014 vbkup good fdbk";
CM_ SG_ 1531 SDCR_a015_reason_vPhaseShortedLo "SDCR ECU: a015 reason v phase shorted low";
CM_ SG_ 1531 SDCR_a015_reason_vPhaseShortedHi "SDCR ECU: a015 reason v phase shorted high";
CM_ SG_ 1531 SDCR_a015_diSwitchingPin "SDCR ECU: a015 di switching pin";
CM_ SG_ 1531 SDCR_a015_vBat "SDCR ECU: a015 v bat";
CM_ SG_ 1531 SDCR_a015_va "SDCR ECU: a015 va";
CM_ SG_ 1531 SDCR_a015_vb "SDCR ECU: a015 vb";
CM_ SG_ 1531 SDCR_a015_vc "SDCR ECU: a015 vc";
CM_ SG_ 1531 SDCR_a017_expectedConfigWord "SDCR ECU: a017 expected config word";
CM_ SG_ 1531 SDCR_a017_receivedConfigWord "SDCR ECU: a017 received config word";
CM_ SG_ 1531 SDCR_a018_pyroArmed "SDCR ECU: a018 pyro armed";
CM_ SG_ 1531 SDCR_a018_triggerReason_faultCur "SDCR ECU: a018 trigger reason fault currents";
CM_ SG_ 1531 SDCR_a018_triggerReason_hvBadAtS "SDCR ECU: a018 trigger reason hv bad at speed";
CM_ SG_ 1531 SDCR_a018_triggerReason_highBack "SDCR ECU: a018 trigger reason high back EMF";
CM_ SG_ 1531 SDCR_a018_faultCurrentsDetected "SDCR ECU: a018 fault currents detected";
CM_ SG_ 1531 SDCR_a018_diUartMIA "SDCR ECU: a018 di uart MIA";
CM_ SG_ 1531 SDCR_a018_pmRunningPin "SDCR ECU: a018 pm running pin";
CM_ SG_ 1531 SDCR_a018_hvPowerGood "SDCR ECU: a018 hv power good";
CM_ SG_ 1531 SDCR_a018_hvbkupPGoodPin "SDCR ECU: a018 hvbkup p good pin";
CM_ SG_ 1531 SDCR_a018_hvPowerNotGoodQualifie "SDCR ECU: a018 hv power not good qualified";
CM_ SG_ 1531 SDCR_a018_speedValid "SDCR ECU: a018 speed valid";
CM_ SG_ 1531 SDCR_a018_speedFromVoltage "SDCR ECU: a018 speed from voltage";
CM_ SG_ 1531 SDCR_a018_HVBackupSupplyV "SDCR ECU: a018 HV backup supply v";
CM_ SG_ 1531 SDCR_a018_boostRailV "SDCR ECU: a018 boost rail v";
CM_ SG_ 1531 SDCR_a018_maxAbsSpeed "SDCR ECU: a018 max abs speed";
CM_ SG_ 1531 SDCR_a018_vBat "SDCR ECU: a018 v bat";
CM_ SG_ 1531 SDCR_a019_faultReason_faultCurre "SDCR ECU: a019 fault reason fault currents at speed";
CM_ SG_ 1531 SDCR_a019_faultReason_unmitigate "SDCR ECU: a019 fault reason unmitigated UCR";
CM_ SG_ 1531 SDCR_a019_faultReason_propagatin "SDCR ECU: a019 fault reason propagating3 PS";
CM_ SG_ 1531 SDCR_a019_speedWasValid "SDCR ECU: a019 speed was valid";
CM_ SG_ 1531 SDCR_a019_imbalanceSeen "SDCR ECU: a019 imbalance seen";
CM_ SG_ 1531 SDCR_a019_ucrSeen "SDCR ECU: a019 ucr seen";
CM_ SG_ 1531 SDCR_a019_phaseVoltagePresent "SDCR ECU: a019 phase voltage present";
CM_ SG_ 1531 SDCR_a019_speedFromVoltage "SDCR ECU: a019 speed from voltage";
CM_ SG_ 1531 SDCR_a019_transientHandling "SDCR ECU: a019 transient handling";
CM_ SG_ 1531 SDCR_a019_maxAbsElcSpeed "SDCR ECU: a019 max abs elc speed";
CM_ SG_ 1531 SDCR_a019_avgIa "SDCR ECU: a019 avg ia";
CM_ SG_ 1531 SDCR_a019_avgIb "SDCR ECU: a019 avg ib";
CM_ SG_ 1531 SDCR_a019_maxAbsCurrents "SDCR ECU: a019 max abs currents";
CM_ SG_ 1531 SDCR_a020_errorCode "SDCR ECU: a020 error code";
CM_ SG_ 1531 SDCR_a020_rxData0 "SDCR ECU: a020 rx data0";
CM_ SG_ 1531 SDCR_a020_rxData1 "SDCR ECU: a020 rx data1";
CM_ SG_ 1531 SDCR_a020_rxData2 "SDCR ECU: a020 rx data2";
CM_ SG_ 1531 SDCR_a020_rxData3 "SDCR ECU: a020 rx data3";
CM_ SG_ 1531 SDCR_a020_rxData4 "SDCR ECU: a020 rx data4";
CM_ SG_ 1531 SDCR_a021_busBarTempC "SDCR ECU: a021 bus bar temp c; raw 0 = signal not available (SNA)";
CM_ SG_ 1531 SDCR_a021_busBarTempA "SDCR ECU: a021 bus bar temp a; raw 0 = signal not available (SNA)";
CM_ SG_ 1531 SDCR_a021_tempCVoltage "SDCR ECU: a021 temp c voltage";
CM_ SG_ 1531 SDCR_a021_tempAVoltage "SDCR ECU: a021 temp a voltage";
CM_ SG_ 1531 SDCR_a024_time "SDCR ECU: a024 time";
CM_ SG_ 1531 SDCR_a025_diSwitchingFromUart "SDCR ECU: a025 di switching from uart";
CM_ SG_ 1531 SDCR_a025_diSwitchingPin "SDCR ECU: a025 di switching pin";
CM_ SG_ 1531 SDCR_a025_pmRunningPin "SDCR ECU: a025 pm running pin";
CM_ SG_ 1531 SDCR_a025_diUartMIA "SDCR ECU: a025 di uart MIA";
CM_ SG_ 1531 SDCR_a025_HVBackupSupplyV "SDCR ECU: a025 HV backup supply v";
CM_ SG_ 1531 SDCR_a025_boostRailV "SDCR ECU: a025 boost rail v";
CM_ SG_ 1531 SDCR_a028_LVPowerState "SDCR ECU: a028 LV power state";
CM_ SG_ 1531 SDCR_a029_uartCommsMissing "SDCR ECU: a029 uart comms missing";
CM_ SG_ 1531 SDCR_a029_canCommsMissing "SDCR ECU: a029 can comms missing";
CM_ SG_ 1531 SDCR_a029_lvState "SDCR ECU: a029 lv state";
CM_ SG_ 1531 SDCR_a034_Ia "SDCR ECU: a034 ia";
CM_ SG_ 1531 SDCR_a034_Ib "SDCR ECU: a034 ib";
CM_ BO_ 1787 "SDCR ECU message: uds response";
CM_ SG_ 1787 SDCR_udsResponseData "SDCR ECU: uds response data";
CM_ BO_ 1835 "Air suspension controller message: alert log";
CM_ SG_ 1835 TAS_alertID "Air suspension controller: alert ID";
CM_ SG_ 1835 TAS_alertState "Air suspension controller: alert state";
CM_ SG_ 1835 TAS_a001_InternalWatchdog "Air suspension controller: a001 internal watchdog";
CM_ SG_ 1835 TAS_a002_CPUUndervoltage "Air suspension controller: a002 CPU undervoltage";
CM_ SG_ 1835 TAS_a002_PowerOnReset "Air suspension controller: a002 power on reset";
CM_ SG_ 1835 TAS_a003_AssertID "Air suspension controller: a003 assert ID";
CM_ SG_ 1835 TAS_a003_LineNumber "Air suspension controller: a003 line number";
CM_ SG_ 1835 TAS_a003_Data "Air suspension controller: a003 data";
CM_ SG_ 1835 TAS_a012_ClockError "Air suspension controller: a012 clock error";
CM_ SG_ 1835 TAS_a012_FlashError "Air suspension controller: a012 flash error";
CM_ SG_ 1835 TAS_a012_SoftwareReset "Air suspension controller: a012 software reset";
CM_ SG_ 1835 TAS_a012_CheckstopReset "Air suspension controller: a012 checkstop reset";
CM_ SG_ 1835 TAS_a012_DebugReset "Air suspension controller: a012 debug reset";
CM_ SG_ 1835 TAS_a012_ExternalReset "Air suspension controller: a012 external reset";
CM_ SG_ 1835 TAS_a021_Task1msLate "Air suspension controller: a021 task1ms late";
CM_ SG_ 1835 TAS_a021_Task1msStarved "Air suspension controller: a021 task1ms starved";
CM_ SG_ 1835 TAS_a021_Task1msMissed "Air suspension controller: a021 task1ms missed";
CM_ SG_ 1835 TAS_a021_Task10msLate "Air suspension controller: a021 task10ms late";
CM_ SG_ 1835 TAS_a021_Task10msStarved "Air suspension controller: a021 task10ms starved";
CM_ SG_ 1835 TAS_a021_Task10msMissed "Air suspension controller: a021 task10ms missed";
CM_ SG_ 1835 TAS_a021_Task100msLate "Air suspension controller: a021 task100ms late";
CM_ SG_ 1835 TAS_a021_Task100msStarved "Air suspension controller: a021 task100ms starved";
CM_ SG_ 1835 TAS_a021_Task100msMissed "Air suspension controller: a021 task100ms missed";
CM_ SG_ 1835 TAS_a021_Task1000msLate "Air suspension controller: a021 task1000ms late";
CM_ SG_ 1835 TAS_a021_Task1000msStarved "Air suspension controller: a021 task1000ms starved";
CM_ SG_ 1835 TAS_a021_Task1000msMissed "Air suspension controller: a021 task1000ms missed";
CM_ SG_ 1835 TAS_a022_TaskInitErrorCount "Air suspension controller: a022 task init error count";
CM_ SG_ 1835 TAS_a022_TaskInitError0 "Air suspension controller: a022 task init error0";
CM_ SG_ 1835 TAS_a022_TaskInitError1 "Air suspension controller: a022 task init error1";
CM_ SG_ 1835 TAS_a022_TaskInitError2 "Air suspension controller: a022 task init error2";
CM_ SG_ 1835 TAS_a022_TaskInitError3 "Air suspension controller: a022 task init error3";
CM_ SG_ 1835 TAS_a022_TaskInitError4 "Air suspension controller: a022 task init error4";
CM_ SG_ 1835 TAS_a025_vehicleLockAtCrash "Air suspension controller: a025 vehicle lock at crash";
CM_ SG_ 1835 TAS_a025_CANCrashIsActive "Air suspension controller: a025 CAN crash is active";
CM_ SG_ 1835 TAS_a025_appCrashIsActive "Air suspension controller: a025 app crash is active";
CM_ SG_ 1835 TAS_a025_lastCrashEvent "Air suspension controller: a025 last crash event";
CM_ SG_ 1835 TAS_a030_PWMdutyCycleFL "Air suspension controller: a030 PW mduty cycle FL";
CM_ SG_ 1835 TAS_a030_PWMfrequencyFL "Air suspension controller: a030 PW mfrequency FL";
CM_ SG_ 1835 TAS_a030_PWMfaultFL "Air suspension controller: a030 PW mfault FL";
CM_ SG_ 1835 TAS_a031_PWMdutyCycleFR "Air suspension controller: a031 PW mduty cycle FR";
CM_ SG_ 1835 TAS_a031_PWMfrequencyFR "Air suspension controller: a031 PW mfrequency FR";
CM_ SG_ 1835 TAS_a031_PWMfaultFR "Air suspension controller: a031 PW mfault FR";
CM_ SG_ 1835 TAS_a032_PWMdutyCycleRL "Air suspension controller: a032 PW mduty cycle RL";
CM_ SG_ 1835 TAS_a032_PWMfrequencyRL "Air suspension controller: a032 PW mfrequency RL";
CM_ SG_ 1835 TAS_a032_PWMfaultRL "Air suspension controller: a032 PW mfault RL";
CM_ SG_ 1835 TAS_a033_PWMdutyCycleRR "Air suspension controller: a033 PW mduty cycle RR";
CM_ SG_ 1835 TAS_a033_PWMfrequencyRR "Air suspension controller: a033 PW mfrequency RR";
CM_ SG_ 1835 TAS_a033_PWMfaultRR "Air suspension controller: a033 PW mfault RR";
CM_ SG_ 1835 TAS_a034_PWMdutyCycleFL "Air suspension controller: a034 PW mduty cycle FL";
CM_ SG_ 1835 TAS_a034_PWMfrequencyFL "Air suspension controller: a034 PW mfrequency FL";
CM_ SG_ 1835 TAS_a034_PWMfaultFL "Air suspension controller: a034 PW mfault FL";
CM_ SG_ 1835 TAS_a035_PWMdutyCycleFR "Air suspension controller: a035 PW mduty cycle FR";
CM_ SG_ 1835 TAS_a035_PWMfrequencyFR "Air suspension controller: a035 PW mfrequency FR";
CM_ SG_ 1835 TAS_a035_PWMfaultFR "Air suspension controller: a035 PW mfault FR";
CM_ SG_ 1835 TAS_a036_PWMdutyCycleRL "Air suspension controller: a036 PW mduty cycle RL";
CM_ SG_ 1835 TAS_a036_PWMfrequencyRL "Air suspension controller: a036 PW mfrequency RL";
CM_ SG_ 1835 TAS_a036_PWMfaultRL "Air suspension controller: a036 PW mfault RL";
CM_ SG_ 1835 TAS_a037_PWMdutyCycleRR "Air suspension controller: a037 PW mduty cycle RR";
CM_ SG_ 1835 TAS_a037_PWMfrequencyRR "Air suspension controller: a037 PW mfrequency RR";
CM_ SG_ 1835 TAS_a037_PWMfaultRR "Air suspension controller: a037 PW mfault RR";
CM_ SG_ 1835 TAS_a038_PWMdutyCycleFL "Air suspension controller: a038 PW mduty cycle FL";
CM_ SG_ 1835 TAS_a038_PWMfrequencyFL "Air suspension controller: a038 PW mfrequency FL";
CM_ SG_ 1835 TAS_a038_PWMfaultFL "Air suspension controller: a038 PW mfault FL";
CM_ SG_ 1835 TAS_a039_PWMdutyCycleFR "Air suspension controller: a039 PW mduty cycle FR";
CM_ SG_ 1835 TAS_a039_PWMfrequencyFR "Air suspension controller: a039 PW mfrequency FR";
CM_ SG_ 1835 TAS_a039_PWMfaultFR "Air suspension controller: a039 PW mfault FR";
CM_ SG_ 1835 TAS_a040_PWMdutyCycleRL "Air suspension controller: a040 PW mduty cycle RL";
CM_ SG_ 1835 TAS_a040_PWMfrequencyRL "Air suspension controller: a040 PW mfrequency RL";
CM_ SG_ 1835 TAS_a040_PWMfaultRL "Air suspension controller: a040 PW mfault RL";
CM_ SG_ 1835 TAS_a041_PWMdutyCycleRR "Air suspension controller: a041 PW mduty cycle RR";
CM_ SG_ 1835 TAS_a041_PWMfrequencyRR "Air suspension controller: a041 PW mfrequency RR";
CM_ SG_ 1835 TAS_a041_PWMfaultRR "Air suspension controller: a041 PW mfault RR";
CM_ SG_ 1835 TAS_a070_voltage12V "Air suspension controller: a070 voltage12 v";
CM_ SG_ 1835 TAS_a071_voltage12V "Air suspension controller: a071 voltage12 v";
CM_ SG_ 1835 TAS_a072_voltage5VOnBoard "Air suspension controller: a072 voltage5 v on board";
CM_ SG_ 1835 TAS_a073_voltage5VOnBoard "Air suspension controller: a073 voltage5 v on board";
CM_ SG_ 1835 TAS_a074_voltage5VOffBoard "Air suspension controller: a074 voltage5 v off board";
CM_ SG_ 1835 TAS_a075_voltage5VOffBoard "Air suspension controller: a075 voltage5 v off board";
CM_ SG_ 1835 TAS_a076_voltage5VOffBoard "Air suspension controller: a076 voltage5 v off board";
CM_ SG_ 1835 TAS_a077_sensorVoltage "Air suspension controller: a077 sensor voltage";
CM_ SG_ 1835 TAS_a077_sensorRefVoltage "Air suspension controller: a077 sensor ref voltage";
CM_ SG_ 1835 TAS_a078_sensorVoltage "Air suspension controller: a078 sensor voltage";
CM_ SG_ 1835 TAS_a078_sensorRefVoltage "Air suspension controller: a078 sensor ref voltage";
CM_ SG_ 1835 TAS_a080_voltage5VHeight "Air suspension controller: a080 voltage5 v height";
CM_ SG_ 1835 TAS_a081_voltage5VHeight "Air suspension controller: a081 voltage5 v height";
CM_ SG_ 1835 TAS_a082_voltage5VHeight "Air suspension controller: a082 voltage5 v height";
CM_ SG_ 1835 TAS_a083_voltage5VAnalog "Air suspension controller: a083 voltage5 v analog";
CM_ SG_ 1835 TAS_a084_voltage5VAnalog "Air suspension controller: a084 voltage5 v analog";
CM_ SG_ 1835 TAS_a085_voltage5VAnalog "Air suspension controller: a085 voltage5 v analog";
CM_ SG_ 1835 TAS_a086_voltage12VSwitched "Air suspension controller: a086 voltage12 v switched";
CM_ SG_ 1835 TAS_a087_voltage12VSwitched "Air suspension controller: a087 voltage12 v switched";
CM_ SG_ 1835 TAS_a093_readError "Air suspension controller: a093 read error";
CM_ SG_ 1835 TAS_a093_IVOR2Exception "Air suspension controller: a093 IVOR2 exception";
CM_ SG_ 1835 TAS_a098_VCFRONT_LVPowerState_MI "Air suspension controller: a098 VCFRONT LV power state MIA";
CM_ SG_ 1835 TAS_a098_VCFRONT_sensors_MIA "Air suspension controller: a098 VCFRONT sensors MIA";
CM_ SG_ 1835 TAS_a098_VCFRONT_status_MIA "Air suspension controller: a098 VCFRONT status MIA";
CM_ SG_ 1835 TAS_a098_VCFRONT_systemStatus_MI "Air suspension controller: a098 VCFRONT system status MIA";
CM_ SG_ 1835 TAS_a098_VCFRONT_vehNm_MIA "Air suspension controller: a098 VCFRONT veh nm MIA";
CM_ SG_ 1835 TAS_a099_UI_chassisControl_MIA "Air suspension controller: a099 UI chassis control MIA";
CM_ SG_ 1835 TAS_a099_UI_driverAssistMapData_ "Air suspension controller: a099 UI driver assist map data MIA";
CM_ SG_ 1835 TAS_a099_UI_suspensionControl_MI "Air suspension controller: a099 UI suspension control MIA";
CM_ SG_ 1835 TAS_a099_UI_vehicleModes_MIA "Air suspension controller: a099 UI vehicle modes MIA";
CM_ SG_ 1835 TAS_a100_RCM_inertial1_MIA "Air suspension controller: a100 RCM inertial1 MIA";
CM_ SG_ 1835 TAS_a100_RCM_inertial2_MIA "Air suspension controller: a100 RCM inertial2 MIA";
CM_ SG_ 1835 TAS_a101_ESP_brakeTorque_MIA "Air suspension controller: a101 ESP brake torque MIA";
CM_ SG_ 1835 TAS_a101_ESP_status_MIA "Air suspension controller: a101 ESP status MIA";
CM_ SG_ 1835 TAS_a101_ESP_wheelRotation_MIA "Air suspension controller: a101 ESP wheel rotation MIA";
CM_ SG_ 1835 TAS_a102_DI_chassisControl_MIA "Air suspension controller: a102 DI chassis control MIA";
CM_ SG_ 1835 TAS_a102_DI_locStatus_MIA "Air suspension controller: a102 DI loc status MIA";
CM_ SG_ 1835 TAS_a102_DI_speed_MIA "Air suspension controller: a102 DI speed MIA";
CM_ SG_ 1835 TAS_a102_DI_systemStatus_MIA "Air suspension controller: a102 DI system status MIA";
CM_ SG_ 1835 TAS_a102_DI_vehicleEstimates_MIA "Air suspension controller: a102 DI vehicle estimates MIA";
CM_ SG_ 1835 TAS_a102_DIF_torque_MIA "Air suspension controller: a102 DIF torque MIA";
CM_ SG_ 1835 TAS_a102_DIR_torque_MIA "Air suspension controller: a102 DIR torque MIA";
CM_ SG_ 1835 TAS_a103_GTW_carConfig_MIA "Air suspension controller: a103 GTW car config MIA";
CM_ SG_ 1835 TAS_a103_GTW_time_MIA "Air suspension controller: a103 GTW time MIA";
CM_ SG_ 1835 TAS_a103_GTW_vehNm_MIA "Air suspension controller: a103 GTW veh nm MIA";
CM_ SG_ 1835 TAS_a103_GTW_vin_MIA "Air suspension controller: a103 GTW vin MIA";
CM_ SG_ 1835 TAS_a164_detectedDamperSolenoid "Air suspension controller: a164 detected damper solenoid";
CM_ SG_ 1835 TAS_a164_expectedDamperSolenoid "Air suspension controller: a164 expected damper solenoid";
CM_ SG_ 1835 TAS_a165_damperValveFault "Air suspension controller: a165 damper valve fault";
CM_ SG_ 1835 TAS_a166_damperValveFault "Air suspension controller: a166 damper valve fault";
CM_ SG_ 1835 TAS_a167_damperValveFault "Air suspension controller: a167 damper valve fault";
CM_ SG_ 1835 TAS_a168_damperValveFault "Air suspension controller: a168 damper valve fault";
CM_ SG_ 1835 TAS_a169_damperValveFault "Air suspension controller: a169 damper valve fault";
CM_ SG_ 1835 TAS_a170_damperValveFault "Air suspension controller: a170 damper valve fault";
CM_ SG_ 1835 TAS_a171_damperValveFault "Air suspension controller: a171 damper valve fault";
CM_ SG_ 1835 TAS_a172_damperValveFault "Air suspension controller: a172 damper valve fault";
CM_ SG_ 1835 TAS_a173_heightDelta_mm "Air suspension controller: a173 height delta mm";
CM_ SG_ 1835 TAS_a174_heightDelta_mm "Air suspension controller: a174 height delta mm";
CM_ SG_ 1835 TAS_a175_heightDelta_mm "Air suspension controller: a175 height delta mm";
CM_ SG_ 1835 TAS_a176_heightDelta_mm "Air suspension controller: a176 height delta mm";
CM_ SG_ 1835 TAS_a190_a2bFaultType "Air suspension controller: a190 a2b fault type";
CM_ SG_ 1835 TAS_a190_a2bInterruptType "Air suspension controller: a190 a2b interrupt type";
CM_ SG_ 1835 TAS_a190_a2bFaultSource "Air suspension controller: a190 a2b fault source";
CM_ SG_ 1835 TAS_a191_a2bFaultType "Air suspension controller: a191 a2b fault type";
CM_ SG_ 1835 TAS_a191_a2bInterruptType "Air suspension controller: a191 a2b interrupt type";
CM_ SG_ 1835 TAS_a191_a2bFaultSource "Air suspension controller: a191 a2b fault source";
CM_ SG_ 1835 TAS_a192_rideHeightVelDspFL "Air suspension controller: a192 ride height vel dsp FL";
CM_ SG_ 1835 TAS_a192_rideHeightVelDspFR "Air suspension controller: a192 ride height vel dsp FR";
CM_ SG_ 1835 TAS_a192_rideHeightVelDspRL "Air suspension controller: a192 ride height vel dsp RL";
CM_ SG_ 1835 TAS_a192_rideHeightVelDspRR "Air suspension controller: a192 ride height vel dsp RR";
CM_ SG_ 1835 TAS_a192_rideHeightVelObserverFL "Air suspension controller: a192 ride height vel observer FL";
CM_ SG_ 1835 TAS_a192_rideHeightVelObserverFR "Air suspension controller: a192 ride height vel observer FR";
CM_ SG_ 1835 TAS_a192_rideHeightVelObserverRL "Air suspension controller: a192 ride height vel observer RL";
CM_ SG_ 1835 TAS_a192_rideHeightVelObserverRR "Air suspension controller: a192 ride height vel observer RR";
CM_ SG_ 1835 TAS_a192_alertVersion "Air suspension controller: a192 alert version";
CM_ SG_ 1835 TAS_a193_EPAS3P_sysStatus_MIA "Air suspension controller: a193 EPAS3 p sys status MIA";
CM_ SG_ 1835 TAS_a210_heightSensorDeltaFL "Air suspension controller: a210 height sensor delta FL";
CM_ SG_ 1835 TAS_a210_heightSensorDeltaFR "Air suspension controller: a210 height sensor delta FR";
CM_ SG_ 1835 TAS_a210_heightSensorDeltaRL "Air suspension controller: a210 height sensor delta RL";
CM_ SG_ 1835 TAS_a210_heightSensorDeltaRR "Air suspension controller: a210 height sensor delta RR";
CM_ SG_ 1835 TAS_a220_galleryPressure "Air suspension controller: a220 gallery pressure";
CM_ SG_ 1835 TAS_a220_timeInExhaust "Air suspension controller: a220 time in exhaust";
CM_ SG_ 1835 TAS_a221_galleryPressureDelta "Air suspension controller: a221 gallery pressure delta";
CM_ SG_ 1835 TAS_a221_timeInIdle "Air suspension controller: a221 time in idle";
CM_ SG_ 1835 TAS_a222_galleryPressureDelta "Air suspension controller: a222 gallery pressure delta";
CM_ SG_ 1835 TAS_a223_galleryPressure "Air suspension controller: a223 gallery pressure";
CM_ SG_ 1835 TAS_a223_valveOnFL "Air suspension controller: a223 valve on FL";
CM_ SG_ 1835 TAS_a223_valveOnFR "Air suspension controller: a223 valve on FR";
CM_ SG_ 1835 TAS_a223_valveOnRL "Air suspension controller: a223 valve on RL";
CM_ SG_ 1835 TAS_a223_valveOnRR "Air suspension controller: a223 valve on RR";
CM_ SG_ 1835 TAS_a223_valveOnReservoir "Air suspension controller: a223 valve on reservoir";
CM_ SG_ 1835 TAS_a224_galleryPressure "Air suspension controller: a224 gallery pressure";
CM_ SG_ 1835 TAS_a224_valveOnFL "Air suspension controller: a224 valve on FL";
CM_ SG_ 1835 TAS_a224_valveOnFR "Air suspension controller: a224 valve on FR";
CM_ SG_ 1835 TAS_a224_valveOnRL "Air suspension controller: a224 valve on RL";
CM_ SG_ 1835 TAS_a224_valveOnRR "Air suspension controller: a224 valve on RR";
CM_ SG_ 1835 TAS_a224_valveOnReservoir "Air suspension controller: a224 valve on reservoir";
CM_ SG_ 1835 TAS_a225_galleryPressure "Air suspension controller: a225 gallery pressure";
CM_ SG_ 1835 TAS_a226_PWMdutyCycleFL "Air suspension controller: a226 PW mduty cycle FL";
CM_ SG_ 1835 TAS_a226_PWMfrequencyFL "Air suspension controller: a226 PW mfrequency FL";
CM_ SG_ 1835 TAS_a226_PWMfaultFL "Air suspension controller: a226 PW mfault FL";
CM_ SG_ 1835 TAS_a227_PWMdutyCycleFR "Air suspension controller: a227 PW mduty cycle FR";
CM_ SG_ 1835 TAS_a227_PWMfrequencyFR "Air suspension controller: a227 PW mfrequency FR";
CM_ SG_ 1835 TAS_a227_PWMfaultFR "Air suspension controller: a227 PW mfault FR";
CM_ SG_ 1835 TAS_a228_PWMdutyCycleRL "Air suspension controller: a228 PW mduty cycle RL";
CM_ SG_ 1835 TAS_a228_PWMfrequencyRL "Air suspension controller: a228 PW mfrequency RL";
CM_ SG_ 1835 TAS_a228_PWMfaultRL "Air suspension controller: a228 PW mfault RL";
CM_ SG_ 1835 TAS_a229_PWMdutyCycleRR "Air suspension controller: a229 PW mduty cycle RR";
CM_ SG_ 1835 TAS_a229_PWMfrequencyRR "Air suspension controller: a229 PW mfrequency RR";
CM_ SG_ 1835 TAS_a229_PWMfaultRR "Air suspension controller: a229 PW mfault RR";
CM_ SG_ 1835 TAS_a232_detectedSuspensionType "Air suspension controller: a232 detected suspension type";
CM_ SG_ 1835 TAS_a232_expectedSuspensionType "Air suspension controller: a232 expected suspension type";
CM_ SG_ 1835 TAS_a234_detectedDamperHydraulic "Air suspension controller: a234 detected damper hydraulic";
CM_ SG_ 1835 TAS_a234_expectedDamperHydraulic "Air suspension controller: a234 expected damper hydraulic";
CM_ SG_ 1835 TAS_a240_highAdjustCountRatio "Air suspension controller: a240 high adjust count ratio";
CM_ SG_ 1835 TAS_a240_highAdjustTimeRatio "Air suspension controller: a240 high adjust time ratio";
CM_ SG_ 1835 TAS_a240_highCrossPressure "Air suspension controller: a240 high cross pressure";
CM_ SG_ 1835 TAS_a240_highCompExhTimeRatio "Air suspension controller: a240 high comp exh time ratio";
CM_ SG_ 1835 TAS_a240_adjustCountRatioSpring "Air suspension controller: a240 adjust count ratio spring";
CM_ SG_ 1835 TAS_a240_adjustCountRatio "Air suspension controller: a240 adjust count ratio; raw 255 = signal not available (SNA)";
CM_ SG_ 1835 TAS_a240_adjustTimeRatioSpring "Air suspension controller: a240 adjust time ratio spring";
CM_ SG_ 1835 TAS_a240_adjustTimeRatio "Air suspension controller: a240 adjust time ratio; raw 255 = signal not available (SNA)";
CM_ SG_ 1835 TAS_a240_compExhTimeRatio "Air suspension controller: a240 comp exh time ratio";
CM_ SG_ 1835 TAS_a240_crossPressure "Air suspension controller: a240 cross pressure";
CM_ SG_ 1835 TAS_a285_twistLevel "Air suspension controller: a285 twist level";
CM_ SG_ 1835 TAS_a290_twistLevel "Air suspension controller: a290 twist level";
CM_ SG_ 1835 TAS_a291_frontAxleHeight "Air suspension controller: a291 front axle height";
CM_ SG_ 1835 TAS_a292_rearAxleHeight "Air suspension controller: a292 rear axle height";
CM_ SG_ 1835 TAS_a293_frontAxleHeight "Air suspension controller: a293 front axle height";
CM_ SG_ 1835 TAS_a294_rearAxleHeight "Air suspension controller: a294 rear axle height";
CM_ SG_ 1835 TAS_a295_targetHeight "Air suspension controller: a295 target height";
CM_ SG_ 1835 TAS_a296_detectedChassisType "Air suspension controller: a296 detected chassis type";
CM_ SG_ 1835 TAS_a296_expectedChassisType "Air suspension controller: a296 expected chassis type";
CM_ SG_ 1835 TAS_a319_detectedDrivetrainType "Air suspension controller: a319 detected drivetrain type";
CM_ SG_ 1835 TAS_a319_expectedDrivetrainType "Air suspension controller: a319 expected drivetrain type";
CM_ BO_ 852 "Air suspension controller message: alert matrix";
CM_ SG_ 852 TAS_matrixIndex "Air suspension controller: matrix index";
CM_ SG_ 852 TAS_a001_WatchdogReset "Air suspension controller: a001 watchdog reset";
CM_ SG_ 852 TAS_a002_PowerLossReset "Air suspension controller: a002 power loss reset";
CM_ SG_ 852 TAS_a003_SWAssertion "Air suspension controller: a003 SW assertion";
CM_ SG_ 852 TAS_a012_CPUReset "Air suspension controller: a012 CPU reset";
CM_ SG_ 852 TAS_a015_NVMMError "Air suspension controller: a015 NVMM error";
CM_ SG_ 852 TAS_a016_NVMMRecordError "Air suspension controller: a016 NVMM record error";
CM_ SG_ 852 TAS_a021_TaskSchedulerError "Air suspension controller: a021 task scheduler error";
CM_ SG_ 852 TAS_a022_TaskInitError "Air suspension controller: a022 task init error";
CM_ SG_ 852 TAS_a023_rtosResetRequested "Air suspension controller: a023 rtos reset requested";
CM_ SG_ 852 TAS_a024_prefetchAbort "Air suspension controller: a024 prefetch abort";
CM_ SG_ 852 TAS_a025_CrashEvent "Air suspension controller: a025 crash event";
CM_ SG_ 852 TAS_a030_PWMerrorFL "Air suspension controller: a030 PW merror FL";
CM_ SG_ 852 TAS_a031_PWMerrorFR "Air suspension controller: a031 PW merror FR";
CM_ SG_ 852 TAS_a032_PWMerrorRL "Air suspension controller: a032 PW merror RL";
CM_ SG_ 852 TAS_a033_PWMerrorRR "Air suspension controller: a033 PW merror RR";
CM_ SG_ 852 TAS_a034_PWMshortFL "Air suspension controller: a034 PW mshort FL";
CM_ SG_ 852 TAS_a035_PWMshortFR "Air suspension controller: a035 PW mshort FR";
CM_ SG_ 852 TAS_a036_PWMshortRL "Air suspension controller: a036 PW mshort RL";
CM_ SG_ 852 TAS_a037_PWMshortRR "Air suspension controller: a037 PW mshort RR";
CM_ SG_ 852 TAS_a038_PWMopenFL "Air suspension controller: a038 PW mopen FL";
CM_ SG_ 852 TAS_a039_PWMopenFR "Air suspension controller: a039 PW mopen FR";
CM_ SG_ 852 TAS_a040_PWMopenRL "Air suspension controller: a040 PW mopen RL";
CM_ SG_ 852 TAS_a041_PWMopenRR "Air suspension controller: a041 PW mopen RR";
CM_ SG_ 852 TAS_a043_Task1msError "Air suspension controller: a043 task1ms error";
CM_ SG_ 852 TAS_a044_Task10msError "Air suspension controller: a044 task10ms error";
CM_ SG_ 852 TAS_a045_Task100msError "Air suspension controller: a045 task100ms error";
CM_ SG_ 852 TAS_a046_Task1000msError "Air suspension controller: a046 task1000ms error";
CM_ SG_ 852 TAS_a061_XCPConnected "Air suspension controller: a061 XCP connected";
CM_ SG_ 852 TAS_a062_XCPWasConnected "Air suspension controller: a062 XCP was connected";
CM_ SG_ 852 TAS_a063_abortFault "Air suspension controller: a063 abort fault";
CM_ SG_ 852 TAS_a064_abortFaultExt "Air suspension controller: a064 abort fault ext";
CM_ SG_ 852 TAS_a065_ahbWriteFault "Air suspension controller: a065 ahb write fault";
CM_ SG_ 852 TAS_a066_undefinedInstructionAbo "Air suspension controller: a066 undefined instruction abort";
CM_ SG_ 852 TAS_a067_reservedHandlerAbort "Air suspension controller: a067 reserved handler abort";
CM_ SG_ 852 TAS_a070_underVoltage12V "Air suspension controller: a070 under voltage12 v";
CM_ SG_ 852 TAS_a071_overVoltage12V "Air suspension controller: a071 over voltage12 v";
CM_ SG_ 852 TAS_a072_shortCircuit5VOnBoard "Air suspension controller: a072 short circuit5 v on board";
CM_ SG_ 852 TAS_a073_underVoltage5VOnBoard "Air suspension controller: a073 under voltage5 v on board";
CM_ SG_ 852 TAS_a074_shortCircuit5VOffBoard "Air suspension controller: a074 short circuit5 v off board";
CM_ SG_ 852 TAS_a075_underVoltage5VOffBoard "Air suspension controller: a075 under voltage5 v off board";
CM_ SG_ 852 TAS_a076_overVoltage5VOffBoard "Air suspension controller: a076 over voltage5 v off board";
CM_ SG_ 852 TAS_a077_pressureSigVTooLow "Air suspension controller: a077 pressure sig v too low";
CM_ SG_ 852 TAS_a078_pressureSigVTooHigh "Air suspension controller: a078 pressure sig v too high";
CM_ SG_ 852 TAS_a080_shortCircuit5VHeight "Air suspension controller: a080 short circuit5 v height";
CM_ SG_ 852 TAS_a081_underVoltage5VHeight "Air suspension controller: a081 under voltage5 v height";
CM_ SG_ 852 TAS_a082_overVoltage5VHeight "Air suspension controller: a082 over voltage5 v height";
CM_ SG_ 852 TAS_a083_shortCircuit5VAnalog "Air suspension controller: a083 short circuit5 v analog";
CM_ SG_ 852 TAS_a084_underVoltage5VAnalog "Air suspension controller: a084 under voltage5 v analog";
CM_ SG_ 852 TAS_a085_overVoltage5VAnalog "Air suspension controller: a085 over voltage5 v analog";
CM_ SG_ 852 TAS_a086_underVoltage12VSwtchd "Air suspension controller: a086 under voltage12 v swtchd";
CM_ SG_ 852 TAS_a087_overVoltage12VSwtchd "Air suspension controller: a087 over voltage12 v swtchd";
CM_ SG_ 852 TAS_a093_OTPError "Air suspension controller: a093 OTP error";
CM_ SG_ 852 TAS_a098_VCFRONT_MIA "Air suspension controller: a098 VCFRONT MIA";
CM_ SG_ 852 TAS_a099_UI_MIA "Air suspension controller: a099 UI MIA";
CM_ SG_ 852 TAS_a100_RCM_MIA "Air suspension controller: a100 RCM MIA";
CM_ SG_ 852 TAS_a101_ESP_MIA "Air suspension controller: a101 ESP MIA";
CM_ SG_ 852 TAS_a102_DI_MIA "Air suspension controller: a102 DI MIA";
CM_ SG_ 852 TAS_a103_GTW_MIA "Air suspension controller: a103 GTW MIA";
CM_ SG_ 852 TAS_a105_ECUDebugMode "Air suspension controller: a105 ECU debug mode";
CM_ SG_ 852 TAS_a106_HighCPULoad "Air suspension controller: a106 high CPU load";
CM_ SG_ 852 TAS_a107_HighStackUsage "Air suspension controller: a107 high stack usage";
CM_ SG_ 852 TAS_a150_accelAvgImplausible_FL_ "Air suspension controller: a150 accel avg implausible FL x";
CM_ SG_ 852 TAS_a151_accelAvgImplausible_FL_ "Air suspension controller: a151 accel avg implausible FL y";
CM_ SG_ 852 TAS_a152_accelAvgImplausible_FL_ "Air suspension controller: a152 accel avg implausible FL z";
CM_ SG_ 852 TAS_a153_accelAvgImplausible_FR_ "Air suspension controller: a153 accel avg implausible FR x";
CM_ SG_ 852 TAS_a154_accelAvgImplausible_FR_ "Air suspension controller: a154 accel avg implausible FR y";
CM_ SG_ 852 TAS_a155_accelAvgImplausible_FR_ "Air suspension controller: a155 accel avg implausible FR z";
CM_ SG_ 852 TAS_a156_accelAvgImplausible_RL_ "Air suspension controller: a156 accel avg implausible RL x";
CM_ SG_ 852 TAS_a157_accelAvgImplausible_RL_ "Air suspension controller: a157 accel avg implausible RL y";
CM_ SG_ 852 TAS_a158_accelAvgImplausible_RL_ "Air suspension controller: a158 accel avg implausible RL z";
CM_ SG_ 852 TAS_a159_accelAvgImplausible_RR_ "Air suspension controller: a159 accel avg implausible RR x";
CM_ SG_ 852 TAS_a160_accelAvgImplausible_RR_ "Air suspension controller: a160 accel avg implausible RR y";
CM_ SG_ 852 TAS_a161_accelAvgImplausible_RR_ "Air suspension controller: a161 accel avg implausible RR z";
CM_ SG_ 852 TAS_a164_damperSolenoidMismatch "Air suspension controller: a164 damper solenoid mismatch";
CM_ SG_ 852 TAS_a165_damperValveCompFL "Air suspension controller: a165 damper valve comp FL";
CM_ SG_ 852 TAS_a166_damperValveRbndFL "Air suspension controller: a166 damper valve rbnd FL";
CM_ SG_ 852 TAS_a167_damperValveCompFR "Air suspension controller: a167 damper valve comp FR";
CM_ SG_ 852 TAS_a168_damperValveRbndFR "Air suspension controller: a168 damper valve rbnd FR";
CM_ SG_ 852 TAS_a169_damperValveCompRL "Air suspension controller: a169 damper valve comp RL";
CM_ SG_ 852 TAS_a170_damperValveRbndRL "Air suspension controller: a170 damper valve rbnd RL";
CM_ SG_ 852 TAS_a171_damperValveCompRR "Air suspension controller: a171 damper valve comp RR";
CM_ SG_ 852 TAS_a172_damperValveRbndRR "Air suspension controller: a172 damper valve rbnd RR";
CM_ SG_ 852 TAS_a173_staticLeakDetectFL "Air suspension controller: a173 static leak detect FL";
CM_ SG_ 852 TAS_a174_staticLeakDetectFR "Air suspension controller: a174 static leak detect FR";
CM_ SG_ 852 TAS_a175_staticLeakDetectRL "Air suspension controller: a175 static leak detect RL";
CM_ SG_ 852 TAS_a176_staticLeakDetectRR "Air suspension controller: a176 static leak detect RR";
CM_ SG_ 852 TAS_a190_a2bFrontAxleFault "Air suspension controller: a190 a2b front axle fault";
CM_ SG_ 852 TAS_a191_a2bRearAxleFault "Air suspension controller: a191 a2b rear axle fault";
CM_ SG_ 852 TAS_a192_rideHeightObserverDiver "Air suspension controller: a192 ride height observer divergence";
CM_ SG_ 852 TAS_a193_EPAS3P_MIA "Air suspension controller: a193 EPAS3 p MIA";
CM_ SG_ 852 TAS_a194_a2bFrontAxleDataError "Air suspension controller: a194 a2b front axle data error";
CM_ SG_ 852 TAS_a195_a2bRearAxleDataError "Air suspension controller: a195 a2b rear axle data error";
CM_ SG_ 852 TAS_a196_adaptiveDampingUsingDSP "Air suspension controller: a196 adaptive damping using DSP";
CM_ SG_ 852 TAS_a197_invalidAdaptiveModeRequ "Air suspension controller: a197 invalid adaptive mode requested";
CM_ SG_ 852 TAS_a200_jackModeActive "Air suspension controller: a200 jack mode active";
CM_ SG_ 852 TAS_a201_low12VBattery "Air suspension controller: a201 low12 v battery";
CM_ SG_ 852 TAS_a210_outOfRangeCalibration "Air suspension controller: a210 out of range calibration";
CM_ SG_ 852 TAS_a211_noRideHeightCalib "Air suspension controller: a211 no ride height calib";
CM_ SG_ 852 TAS_a213_yellowWarningLamp "Air suspension controller: a213 yellow warning lamp";
CM_ SG_ 852 TAS_a214_redWarningLamp "Air suspension controller: a214 red warning lamp";
CM_ SG_ 852 TAS_a215_limpHomeMode10 "Air suspension controller: a215 limp home mode10";
CM_ SG_ 852 TAS_a216_limpHomeMode20 "Air suspension controller: a216 limp home mode20";
CM_ SG_ 852 TAS_a217_limpHomeMode30 "Air suspension controller: a217 limp home mode30";
CM_ SG_ 852 TAS_a218_limpHomeMode40 "Air suspension controller: a218 limp home mode40";
CM_ SG_ 852 TAS_a220_exhaustGalleryFault "Air suspension controller: a220 exhaust gallery fault";
CM_ SG_ 852 TAS_a221_valveLeakDetected "Air suspension controller: a221 valve leak detected";
CM_ SG_ 852 TAS_a222_compressorPrefillFault "Air suspension controller: a222 compressor prefill fault";
CM_ SG_ 852 TAS_a223_blockedAirline "Air suspension controller: a223 blocked airline";
CM_ SG_ 852 TAS_a224_openAirline "Air suspension controller: a224 open airline";
CM_ SG_ 852 TAS_a225_galleryPressureTooHigh "Air suspension controller: a225 gallery pressure too high";
CM_ SG_ 852 TAS_a226_PWMfastDetectFL "Air suspension controller: a226 PW mfast detect FL";
CM_ SG_ 852 TAS_a227_PWMfastDetectFR "Air suspension controller: a227 PW mfast detect FR";
CM_ SG_ 852 TAS_a228_PWMfastDetectRL "Air suspension controller: a228 PW mfast detect RL";
CM_ SG_ 852 TAS_a229_PWMfastDetectRR "Air suspension controller: a229 PW mfast detect RR";
CM_ SG_ 852 TAS_a230_notifyGeofence "Air suspension controller: a230 notify geofence";
CM_ SG_ 852 TAS_a231_notifyRoughRoadRaise "Air suspension controller: a231 notify rough road raise";
CM_ SG_ 852 TAS_a232_suspensionTypeMismatch "Air suspension controller: a232 suspension type mismatch";
CM_ SG_ 852 TAS_a233_compressorStuckOn "Air suspension controller: a233 compressor stuck on";
CM_ SG_ 852 TAS_a234_damperHydraulicMismatch "Air suspension controller: a234 damper hydraulic mismatch";
CM_ SG_ 852 TAS_a240_airSpringLeak "Air suspension controller: a240 air spring leak";
CM_ SG_ 852 TAS_a284_serviceRunModeActive "Air suspension controller: a284 service run mode active";
CM_ SG_ 852 TAS_a285_twistSustainedUserVis "Air suspension controller: a285 twist sustained user vis";
CM_ SG_ 852 TAS_a286_driveCycleStats1 "Air suspension controller: a286 drive cycle stats1";
CM_ SG_ 852 TAS_a287_driveCycleStats2 "Air suspension controller: a287 drive cycle stats2";
CM_ SG_ 852 TAS_a288_driveCycleStats3 "Air suspension controller: a288 drive cycle stats3";
CM_ SG_ 852 TAS_a289_driveCycleStats4 "Air suspension controller: a289 drive cycle stats4";
CM_ SG_ 852 TAS_a290_twistSustainedAtSpeed "Air suspension controller: a290 twist sustained at speed";
CM_ SG_ 852 TAS_a291_frontAxleTooHigh "Air suspension controller: a291 front axle too high";
CM_ SG_ 852 TAS_a292_rearAxleTooHigh "Air suspension controller: a292 rear axle too high";
CM_ SG_ 852 TAS_a293_frontAxleTooLow "Air suspension controller: a293 front axle too low";
CM_ SG_ 852 TAS_a294_rearAxleTooLow "Air suspension controller: a294 rear axle too low";
CM_ SG_ 852 TAS_a295_targetHeightNotMet "Air suspension controller: a295 target height not met";
CM_ SG_ 852 TAS_a296_chassisTypeMismatch "Air suspension controller: a296 chassis type mismatch";
CM_ SG_ 852 TAS_a297_vinMismatch "Air suspension controller: a297 vin mismatch";
CM_ SG_ 852 TAS_a298_vinNotLearned "Air suspension controller: a298 vin not learned";
CM_ SG_ 852 TAS_a299_offsetEstimateTooLarge "Air suspension controller: a299 offset estimate too large";
CM_ SG_ 852 TAS_a300_offsetEstimateData1 "Air suspension controller: a300 offset estimate data1";
CM_ SG_ 852 TAS_a301_offsetEstimateData2 "Air suspension controller: a301 offset estimate data2";
CM_ SG_ 852 TAS_a303_massEstimateFrozen "Air suspension controller: a303 mass estimate frozen";
CM_ SG_ 852 TAS_a304_massEstimateFrozenData "Air suspension controller: a304 mass estimate frozen data";
CM_ SG_ 852 TAS_a305_newEndstopPosition "Air suspension controller: a305 new endstop position";
CM_ SG_ 852 TAS_a306_hardwareProtectFrozen "Air suspension controller: a306 hardware protect frozen";
CM_ SG_ 852 TAS_a307_endstopBoundaryComp "Air suspension controller: a307 endstop boundary comp";
CM_ SG_ 852 TAS_a308_endstopBoundaryRbnd "Air suspension controller: a308 endstop boundary rbnd";
CM_ SG_ 852 TAS_a309_controlFrozen "Air suspension controller: a309 control frozen";
CM_ SG_ 852 TAS_a310_controlFrozenData "Air suspension controller: a310 control frozen data";
CM_ SG_ 852 TAS_a311_accelsMIA "Air suspension controller: a311 accels MIA";
CM_ SG_ 852 TAS_a312_rotationalRatesMIA "Air suspension controller: a312 rotational rates MIA";
CM_ SG_ 852 TAS_a313_dampingCntrlDisabled "Air suspension controller: a313 damping cntrl disabled";
CM_ SG_ 852 TAS_a314_dampingReduced "Air suspension controller: a314 damping reduced";
CM_ SG_ 852 TAS_a315_pcbaHighTemp "Air suspension controller: a315 pcba high temp";
CM_ SG_ 852 TAS_a316_offsetsAccels "Air suspension controller: a316 offsets accels";
CM_ SG_ 852 TAS_a317_offsetsRotationalRates "Air suspension controller: a317 offsets rotational rates";
CM_ SG_ 852 TAS_a318_dampingCntrlInputMIA "Air suspension controller: a318 damping cntrl input MIA";
CM_ SG_ 852 TAS_a319_drivetrainTypeMismatch "Air suspension controller: a319 drivetrain type mismatch";
CM_ SG_ 852 TAS_a320_offsetsRotationalRates "Air suspension controller: a320 offsets rotational rates";
CM_ SG_ 852 TAS_a321_speedBumpAttributes1 "Air suspension controller: a321 speed bump attributes1";
CM_ SG_ 852 TAS_a322_speedBumpAttributes2 "Air suspension controller: a322 speed bump attributes2";
CM_ SG_ 852 TAS_a332_levelingThresholds1 "Air suspension controller: a332 leveling thresholds1";
CM_ SG_ 852 TAS_a333_levelingThresholds2 "Air suspension controller: a333 leveling thresholds2";
CM_ BO_ 1627 "Air suspension controller message: uds response";
CM_ SG_ 1627 TAS_udsResponseData "Air suspension controller: uds response data";
CM_ BO_ 1410 "TCU ECU message: alert log";
CM_ SG_ 1410 TCU_alertID "TCU ECU: alert ID";
CM_ SG_ 1410 TCU_alertState "TCU ECU: alert state";
CM_ SG_ 1410 TCU_w001_FailCode "TCU ECU: w001 fail code";
CM_ SG_ 1410 TCU_w002_RejCause "TCU ECU: w002 rej cause";
CM_ SG_ 1410 TCU_w003_CallFailCode "TCU ECU: w003 call fail code";
CM_ SG_ 1410 TCU_w004_MSDFailCode "TCU ECU: w004 MSD fail code";
CM_ SG_ 1410 TCU_w006_Count "TCU ECU: w006 count";
CM_ BO_ 1472 "TCU ECU message: alert matrix1";
CM_ SG_ 1472 TCU_w001_IMSRegistrationFailed "TCU ECU: w001 IMS registration failed";
CM_ SG_ 1472 TCU_w002_CellRegRejected "TCU ECU: w002 cell reg rejected";
CM_ SG_ 1472 TCU_w003_ECallFailed "TCU ECU: w003 e call failed";
CM_ SG_ 1472 TCU_w004_MSDTransmissionFailed "TCU ECU: w004 MSD transmission failed";
CM_ SG_ 1472 TCU_w005_SIMSlotError "TCU ECU: w005 SIM slot error";
CM_ SG_ 1472 TCU_w006_MpssUnavailable "TCU ECU: w006 mpss unavailable";
CM_ BO_ 1409 "TCU ECU message: log";
CM_ SG_ 1409 TCU_logMux "TCU ECU: log mux";
CM_ SG_ 1409 TCU_cpuTemp "Indicates the current temperature reported by the Central Processing Unit (CPU) in the modem application processor";
CM_ SG_ 1409 TCU_cpuUsage "Indicates the current CPU usage in percentage reported by the modem application processor";
CM_ SG_ 1409 TCU_mdmCoreTemperature "Indicates the current Communication Processor (CP) temperature reported by the modem CP.";
CM_ SG_ 1409 TCU_availableMemory "Indicates the currently available Random Access Memory in the modem application processor";
CM_ SG_ 1409 TCU_pwm "Indicates the active Pulse Width Modulation (PWM) duty cycle applied to the modem fan.";
CM_ SG_ 1409 TCU_pwmcap "Indicates the active Pulse Width Modulation (PWM) duty cycle restriciton applied to the modem fan.";
CM_ SG_ 1409 TCU_totalResumes "Indicates the total amount of times the modem has been resumed";
CM_ SG_ 1409 TCU_mdmUplinkQueueSize "TCU ECU: mdm uplink queue size";
CM_ SG_ 1409 TCU_mdmRSRP "TCU ECU: mdm RSRP";
CM_ SG_ 1409 TCU_mdmSINR "TCU ECU: mdm SINR";
CM_ SG_ 1409 TCU_mdmUplinkAllowedRate "TCU ECU: mdm uplink allowed rate";
CM_ SG_ 1409 TCU_mdmUplinkAvgRage "TCU ECU: mdm uplink avg rage";
CM_ SG_ 1409 TCU_mdmServiceState "TCU ECU: mdm service state";
CM_ SG_ 1409 TCU_mdmIMSStatus "Indicates the current IP Multimedia System (IMS) registration state.";
CM_ SG_ 1409 TCU_mdmSIMStatus "TCU ECU: mdm SIM status";
CM_ SG_ 1409 TCU_mdmBusyActive "Reports whether the modem busy service is active on the modem application processor; raw 4294967295 = signal not available (SNA)";
CM_ BO_ 1408 "TCU ECU message: status";
CM_ SG_ 1408 TCU_statusMux "TCU ECU: status mux";
CM_ SG_ 1408 TCU_wakeUpReason "TCU ECU: wake up reason; raw 4294967295 = signal not available (SNA)";
CM_ SG_ 1408 TCU_tcuCmdId "TCU ECU: tcu cmd id";
CM_ SG_ 1408 TCU_goingToSleep "TCU ECU: going to sleep; raw 4294967295 = signal not available (SNA)";
CM_ BO_ 1631 "Tire pressure monitoring message: uds response";
CM_ SG_ 1631 TPMS_udsResponseData "Tire pressure monitoring: uds response data";
BA_DEF_ BO_ "GenMsgCycleTime" INT 0 3600000;
BA_DEF_ BO_ "GenMsgSendType" ENUM "Cyclic","NotUsed","NotUsed","NotUsed","NotUsed","NotUsed","NotUsed","IfActive","NoMsgSendType","NotUsed";
BA_DEF_ BO_ "VFrameFormat" ENUM "StandardCAN","ExtendedCAN","reserved","J1939PG","reserved","reserved","reserved","reserved","reserved","reserved","reserved","reserved","reserved","reserved","StandardCAN_FD","ExtendedCAN_FD";
BA_DEF_ BO_ "CANFD_BRS" ENUM "0","1";
BA_DEF_ SG_ "GenSigSNA" STRING;
BA_DEF_ SG_ "SystemSignalLongSymbol" STRING;
BA_DEF_ SG_ "Confidence" ENUM "validated","plausible","layout-only","contradicted";
BA_DEF_DEF_ "GenMsgCycleTime" 0;
BA_DEF_DEF_ "GenMsgSendType" "NoMsgSendType";
BA_DEF_DEF_ "VFrameFormat" "StandardCAN";
BA_DEF_DEF_ "CANFD_BRS" "1";
BA_DEF_DEF_ "GenSigSNA" "";
BA_DEF_DEF_ "SystemSignalLongSymbol" "";
BA_DEF_DEF_ "Confidence" "layout-only";
BA_ "GenMsgCycleTime" BO_ 998 1000;
BA_ "GenMsgSendType" BO_ 998 0;
BA_ "GenMsgCycleTime" BO_ 831 10000;
BA_ "GenMsgSendType" BO_ 831 0;
BA_ "GenMsgCycleTime" BO_ 852 100;
BA_ "GenMsgSendType" BO_ 852 0;
BA_ "GenMsgCycleTime" BO_ 1472 1000;
BA_ "GenMsgSendType" BO_ 1472 0;
BA_ "GenMsgCycleTime" BO_ 1409 1000;
BA_ "GenMsgSendType" BO_ 1409 0;
BA_ "GenMsgCycleTime" BO_ 1408 1000;
BA_ "GenMsgSendType" BO_ 1408 0;
BA_ "Confidence" SG_ 998 RCU_matrixIndex 1;
BA_ "SystemSignalLongSymbol" SG_ 998 RCU_a033_VCFRONTLVPowerStateChec "RCU_a033_VCFRONTLVPowerStateChecksum";
BA_ "SystemSignalLongSymbol" SG_ 998 RCU_a034_VCFRONTLVPowerStateCoun "RCU_a034_VCFRONTLVPowerStateCounter";
BA_ "SystemSignalLongSymbol" SG_ 998 RCU_a037_IDBinputRodStrokeInvali "RCU_a037_IDBinputRodStrokeInvalid";
BA_ "SystemSignalLongSymbol" SG_ 998 RCU_a043_VCFRONTiBoosterLvStateI "RCU_a043_VCFRONTiBoosterLvStateInvalid";
BA_ "SystemSignalLongSymbol" SG_ 998 RCU_a055_IDBsimulatorPressFaulte "RCU_a055_IDBsimulatorPressFaulted";
BA_ "SystemSignalLongSymbol" SG_ 998 RCU_a056_redundantControllerIsMa "RCU_a056_redundantControllerIsMaster";
BA_ "SystemSignalLongSymbol" SG_ 998 RCU_a058_DIbrakeTorqueCommandAnd "RCU_a058_DIbrakeTorqueCommandAndFlagMismatch";
BA_ "Confidence" SG_ 831 RCU_infoIndex 1;
BA_ "Confidence" SG_ 1344 SCCM_alertID 1;
BA_ "Confidence" SG_ 1344 SCCM_alertState 1;
BA_ "Confidence" SG_ 1344 SCCM_a003_debouncePosition 1;
BA_ "Confidence" SG_ 1344 SCCM_a003_rawPosition 1;
BA_ "Confidence" SG_ 1344 SCCM_a003_errorPosition 1;
BA_ "Confidence" SG_ 1344 SCCM_a003_adcValue 1;
BA_ "Confidence" SG_ 1344 SCCM_a004_debouncePosition 1;
BA_ "Confidence" SG_ 1344 SCCM_a004_rawPosition 1;
BA_ "Confidence" SG_ 1344 SCCM_a004_errorPosition 1;
BA_ "Confidence" SG_ 1344 SCCM_a004_adcValue 1;
BA_ "Confidence" SG_ 1344 SCCM_a005_debouncePosition 1;
BA_ "Confidence" SG_ 1344 SCCM_a005_rawPosition 1;
BA_ "Confidence" SG_ 1344 SCCM_a005_errorPosition 1;
BA_ "Confidence" SG_ 1344 SCCM_a005_adcValue 1;
BA_ "Confidence" SG_ 1344 SCCM_a006_debouncePosition 1;
BA_ "Confidence" SG_ 1344 SCCM_a006_rawPosition 1;
BA_ "Confidence" SG_ 1344 SCCM_a006_errorPosition 1;
BA_ "Confidence" SG_ 1344 SCCM_a006_adcValue 1;
BA_ "Confidence" SG_ 1344 SCCM_a007_debouncePosition 1;
BA_ "Confidence" SG_ 1344 SCCM_a007_rawPosition 1;
BA_ "Confidence" SG_ 1344 SCCM_a007_errorPosition 1;
BA_ "Confidence" SG_ 1344 SCCM_a007_adcValue1 1;
BA_ "Confidence" SG_ 1344 SCCM_a007_adcValue2 1;
BA_ "Confidence" SG_ 1344 SCCM_a008_debouncePosition 1;
BA_ "Confidence" SG_ 1344 SCCM_a008_rawPosition 1;
BA_ "Confidence" SG_ 1344 SCCM_a008_errorPosition 1;
BA_ "Confidence" SG_ 1344 SCCM_a008_adcValue1 1;
BA_ "Confidence" SG_ 1344 SCCM_a008_adcValue2 1;
BA_ "Confidence" SG_ 1344 SCCM_a009_debouncePosition 1;
BA_ "Confidence" SG_ 1344 SCCM_a009_rawPosition 1;
BA_ "Confidence" SG_ 1344 SCCM_a009_errorPosition 1;
BA_ "Confidence" SG_ 1344 SCCM_a009_adcValue1 1;
BA_ "Confidence" SG_ 1344 SCCM_a009_adcValue2 1;
BA_ "Confidence" SG_ 1344 SCCM_a010_debouncePosition 1;
BA_ "Confidence" SG_ 1344 SCCM_a010_rawPosition 1;
BA_ "Confidence" SG_ 1344 SCCM_a010_errorPosition 1;
BA_ "Confidence" SG_ 1344 SCCM_a010_adcValue1 1;
BA_ "Confidence" SG_ 1344 SCCM_a010_adcValue2 1;
BA_ "Confidence" SG_ 1344 SCCM_a011_debouncePosition 1;
BA_ "Confidence" SG_ 1344 SCCM_a011_rawPosition 1;
BA_ "Confidence" SG_ 1344 SCCM_a011_errorPosition 1;
BA_ "Confidence" SG_ 1344 SCCM_a011_adcValue1 1;
BA_ "Confidence" SG_ 1344 SCCM_a011_adcValue2 1;
BA_ "Confidence" SG_ 1344 SCCM_a012_debouncePosition 1;
BA_ "Confidence" SG_ 1344 SCCM_a012_rawPosition 1;
BA_ "Confidence" SG_ 1344 SCCM_a012_errorPosition 1;
BA_ "Confidence" SG_ 1344 SCCM_a012_adcValue1 1;
BA_ "Confidence" SG_ 1344 SCCM_a012_adcValue2 1;
BA_ "Confidence" SG_ 1344 SCCM_a013_voltage 1;
BA_ "Confidence" SG_ 1344 SCCM_a014_voltage 1;
BA_ "Confidence" SG_ 1344 SCCM_a015_intMainIndex 1;
BA_ "Confidence" SG_ 1344 SCCM_a015_intSubIndex 1;
BA_ "Confidence" SG_ 1344 SCCM_a015_intMemIndex 1;
BA_ "Confidence" SG_ 1344 SCCM_a016_mainAdcTest 1;
BA_ "Confidence" SG_ 1344 SCCM_a016_mainCpuTest 1;
BA_ "Confidence" SG_ 1344 SCCM_a016_wdtTest 1;
BA_ "Confidence" SG_ 1344 SCCM_a016_subCpuTest 1;
BA_ "Confidence" SG_ 1344 SCCM_a016_subAdcTest 1;
BA_ "Confidence" SG_ 1344 SCCM_a017_mainRamTest 1;
BA_ "Confidence" SG_ 1344 SCCM_a017_mainRomTest 1;
BA_ "Confidence" SG_ 1344 SCCM_a017_stackHardLimitTest 1;
BA_ "Confidence" SG_ 1344 SCCM_a017_mainDataFlashTest 1;
BA_ "Confidence" SG_ 1344 SCCM_a017_subRamTest 1;
BA_ "Confidence" SG_ 1344 SCCM_a017_subRomTest 1;
BA_ "Confidence" SG_ 1344 SCCM_a017_subStackHardLimitTest 1;
BA_ "Confidence" SG_ 1344 SCCM_a017_svError 1;
BA_ "Confidence" SG_ 1344 SCCM_a018_internalSASState 1;
BA_ "Confidence" SG_ 1344 SCCM_a019_internalSASState 1;
BA_ "Confidence" SG_ 1344 SCCM_a020_internalSASState 1;
BA_ "Confidence" SG_ 1344 SCCM_a021_adcValue1 1;
BA_ "Confidence" SG_ 1344 SCCM_a021_adcValue2 1;
BA_ "Confidence" SG_ 1344 SCCM_a021_adcValue3 1;
BA_ "Confidence" SG_ 1344 SCCM_a021_adcValue4 1;
BA_ "Confidence" SG_ 1344 SCCM_a021_adcValue5 1;
BA_ "Confidence" SG_ 1344 SCCM_a021_adcValue6 1;
BA_ "Confidence" SG_ 1344 SCCM_a022_adcValue1 1;
BA_ "Confidence" SG_ 1344 SCCM_a022_adcValue2 1;
BA_ "Confidence" SG_ 1344 SCCM_a022_adcValue3 1;
BA_ "Confidence" SG_ 1344 SCCM_a022_adcValue4 1;
BA_ "Confidence" SG_ 1344 SCCM_a022_adcValue5 1;
BA_ "Confidence" SG_ 1344 SCCM_a022_adcValue6 1;
BA_ "Confidence" SG_ 1344 SCCM_a023_adcValue1 1;
BA_ "Confidence" SG_ 1344 SCCM_a023_adcValue2 1;
BA_ "Confidence" SG_ 1344 SCCM_a023_adcValue3 1;
BA_ "Confidence" SG_ 1344 SCCM_a023_adcValue4 1;
BA_ "Confidence" SG_ 1344 SCCM_a023_adcValue5 1;
BA_ "Confidence" SG_ 1344 SCCM_a023_adcValue6 1;
BA_ "Confidence" SG_ 1344 SCCM_a024_adcValue1 1;
BA_ "Confidence" SG_ 1344 SCCM_a024_adcValue2 1;
BA_ "Confidence" SG_ 1344 SCCM_a024_adcValue3 1;
BA_ "Confidence" SG_ 1344 SCCM_a024_adcValue4 1;
BA_ "Confidence" SG_ 1344 SCCM_a024_adcValue5 1;
BA_ "Confidence" SG_ 1344 SCCM_a024_adcValue6 1;
BA_ "Confidence" SG_ 1344 SCCM_a025_taskState 1;
BA_ "Confidence" SG_ 1344 SCCM_a026_debouncePosition 1;
BA_ "Confidence" SG_ 1344 SCCM_a026_rawPosition 1;
BA_ "Confidence" SG_ 1344 SCCM_a026_errorPosition 1;
BA_ "Confidence" SG_ 1344 SCCM_a026_adcValue1 1;
BA_ "Confidence" SG_ 1344 SCCM_a026_adcValue2 1;
BA_ "Confidence" SG_ 1344 SCCM_a027_debouncePosition 1;
BA_ "Confidence" SG_ 1344 SCCM_a027_rawPosition 1;
BA_ "Confidence" SG_ 1344 SCCM_a027_errorPosition 1;
BA_ "Confidence" SG_ 1344 SCCM_a027_adcValue1 1;
BA_ "Confidence" SG_ 1344 SCCM_a027_adcValue2 1;
BA_ "Confidence" SG_ 1344 SCCM_a028_debouncePosition 1;
BA_ "Confidence" SG_ 1344 SCCM_a028_rawPosition 1;
BA_ "Confidence" SG_ 1344 SCCM_a028_errorPosition 1;
BA_ "Confidence" SG_ 1344 SCCM_a028_adcValue1 1;
BA_ "Confidence" SG_ 1344 SCCM_a028_adcValue2 1;
BA_ "Confidence" SG_ 1344 SCCM_a029_debouncePosition 1;
BA_ "Confidence" SG_ 1344 SCCM_a029_rawPosition 1;
BA_ "Confidence" SG_ 1344 SCCM_a029_errorPosition 1;
BA_ "Confidence" SG_ 1344 SCCM_a029_adcValue1 1;
BA_ "Confidence" SG_ 1344 SCCM_a029_adcValue2 1;
BA_ "Confidence" SG_ 1344 SCCM_a061_voltage 1;
BA_ "Confidence" SG_ 1344 SCCM_a062_voltage 1;
BA_ "Confidence" SG_ 1344 SCCM_a063_UntrimmedAngle 1;
BA_ "GenSigSNA" SG_ 1344 SCCM_a063_UntrimmedAngle "16383";
BA_ "Confidence" SG_ 1344 SCCM_a064_Speed 1;
BA_ "GenSigSNA" SG_ 1344 SCCM_a064_Speed "16383";
BA_ "Confidence" SG_ 1344 SCCM_a065_M1RawAngleCurrent 1;
BA_ "Confidence" SG_ 1344 SCCM_a065_M1RawAnglePrevious 1;
BA_ "Confidence" SG_ 1344 SCCM_a065_M2RawAngleCurrent 1;
BA_ "Confidence" SG_ 1344 SCCM_a065_M2RawAnglePrevious 1;
BA_ "Confidence" SG_ 1344 SCCM_a066_M1RawAngleCurrent 1;
BA_ "Confidence" SG_ 1344 SCCM_a066_M1RawAnglePrevious 1;
BA_ "Confidence" SG_ 1344 SCCM_a066_M2RawAngleCurrent 1;
BA_ "Confidence" SG_ 1344 SCCM_a066_M2RawAnglePrevious 1;
BA_ "Confidence" SG_ 1344 SCCM_a077_M1ExpectAngleCurrent 1;
BA_ "Confidence" SG_ 1344 SCCM_a077_M1ExpectAnglePrevious 1;
BA_ "Confidence" SG_ 1344 SCCM_a077_M1AngleCurrent 1;
BA_ "Confidence" SG_ 1344 SCCM_a077_M1AnglePrevious 1;
BA_ "Confidence" SG_ 1344 SCCM_a079_ChipTemperature 1;
BA_ "Confidence" SG_ 1344 SCCM_a121_turnIndicatorStalkAngl 1;
BA_ "SystemSignalLongSymbol" SG_ 1344 SCCM_a121_turnIndicatorStalkAngl "SCCM_a121_turnIndicatorStalkAngle";
BA_ "Confidence" SG_ 1344 SCCM_a121_turnIndicatorHallAngle 1;
BA_ "Confidence" SG_ 1344 SCCM_a122_turnIndicatorSpeed 1;
BA_ "Confidence" SG_ 1344 SCCM_a123_turnIndicatorStalkAngl 1;
BA_ "SystemSignalLongSymbol" SG_ 1344 SCCM_a123_turnIndicatorStalkAngl "SCCM_a123_turnIndicatorStalkAngle";
BA_ "Confidence" SG_ 1344 SCCM_a124_turnIndicatorStalkAngl 1;
BA_ "SystemSignalLongSymbol" SG_ 1344 SCCM_a124_turnIndicatorStalkAngl "SCCM_a124_turnIndicatorStalkAngle";
BA_ "Confidence" SG_ 1344 SCCM_a125_turnIndicatorHallAngle 1;
BA_ "Confidence" SG_ 1344 SCCM_a125_turnIndicatorVectorAng 1;
BA_ "SystemSignalLongSymbol" SG_ 1344 SCCM_a125_turnIndicatorVectorAng "SCCM_a125_turnIndicatorVectorAngle";
BA_ "SystemSignalLongSymbol" SG_ 1344 SCCM_a126_turnIndicatorXVectorOu "SCCM_a126_turnIndicatorXVectorOutOfRange";
BA_ "SystemSignalLongSymbol" SG_ 1344 SCCM_a126_turnIndicatorYVectorOu "SCCM_a126_turnIndicatorYVectorOutOfRange";
BA_ "SystemSignalLongSymbol" SG_ 1344 SCCM_a126_turnIndicatorZVectorOu "SCCM_a126_turnIndicatorZVectorOutOfRange";
BA_ "SystemSignalLongSymbol" SG_ 1344 SCCM_a126_turnIndicatorResu_0001 "SCCM_a126_turnIndicatorResultantOutOfRange";
BA_ "Confidence" SG_ 1344 SCCM_a126_turnIndicatorXMagnitud 1;
BA_ "SystemSignalLongSymbol" SG_ 1344 SCCM_a126_turnIndicatorXMagnitud "SCCM_a126_turnIndicatorXMagnitude";
BA_ "Confidence" SG_ 1344 SCCM_a126_turnIndicatorYMagnitud 1;
BA_ "SystemSignalLongSymbol" SG_ 1344 SCCM_a126_turnIndicatorYMagnitud "SCCM_a126_turnIndicatorYMagnitude";
BA_ "Confidence" SG_ 1344 SCCM_a126_turnIndicatorZMagnitud 1;
BA_ "SystemSignalLongSymbol" SG_ 1344 SCCM_a126_turnIndicatorZMagnitud "SCCM_a126_turnIndicatorZMagnitude";
BA_ "Confidence" SG_ 1344 SCCM_a126_turnIndicatorResultant 1;
BA_ "SystemSignalLongSymbol" SG_ 1344 SCCM_a126_turnIndicatorResultant "SCCM_a126_turnIndicatorResultantMagnitude";
BA_ "Confidence" SG_ 1680 SCCM_functionalResponseData_0 1;
BA_ "Confidence" SG_ 1680 SCCM_functionalResponseData_1 1;
BA_ "Confidence" SG_ 1680 SCCM_functionalResponseData_2 1;
BA_ "Confidence" SG_ 1680 SCCM_functionalResponseData_3 1;
BA_ "Confidence" SG_ 1680 SCCM_functionalResponseData_4 1;
BA_ "Confidence" SG_ 1680 SCCM_functionalResponseData_5 1;
BA_ "Confidence" SG_ 1680 SCCM_functionalResponseData_6 1;
BA_ "Confidence" SG_ 1680 SCCM_functionalResponseData_7 1;
BA_ "Confidence" SG_ 1531 SDCR_alertID 1;
BA_ "Confidence" SG_ 1531 SDCR_alertState 1;
BA_ "Confidence" SG_ 1531 SDCR_a001_pyroSenseV 1;
BA_ "Confidence" SG_ 1531 SDCR_a001_HVBackupSupplyV 1;
BA_ "Confidence" SG_ 1531 SDCR_a001_boostRailV 1;
BA_ "Confidence" SG_ 1531 SDCR_a001_expectedPyroV_max 1;
BA_ "Confidence" SG_ 1531 SDCR_a001_expectedPyroV_min 1;
BA_ "Confidence" SG_ 1531 SDCR_a001_fromState 1;
BA_ "Confidence" SG_ 1531 SDCR_a004_HVBackupSupplyV 1;
BA_ "Confidence" SG_ 1531 SDCR_a004_boostRailV 1;
BA_ "SystemSignalLongSymbol" SG_ 1531 SDCR_a006_triggerReason_faultCur "SDCR_a006_triggerReason_faultCurrents";
BA_ "SystemSignalLongSymbol" SG_ 1531 SDCR_a006_triggerReason_hvBadAtS "SDCR_a006_triggerReason_hvBadAtSpeed";
BA_ "SystemSignalLongSymbol" SG_ 1531 SDCR_a006_triggerReason_highBack "SDCR_a006_triggerReason_highBackEMF";
BA_ "SystemSignalLongSymbol" SG_ 1531 SDCR_a006_hvPowerNotGoodQualifie "SDCR_a006_hvPowerNotGoodQualified";
BA_ "Confidence" SG_ 1531 SDCR_a006_HVBackupSupplyV 1;
BA_ "Confidence" SG_ 1531 SDCR_a006_boostRailV 1;
BA_ "Confidence" SG_ 1531 SDCR_a006_maxAbsSpeed 1;
BA_ "Confidence" SG_ 1531 SDCR_a006_vBat 1;
BA_ "SystemSignalLongSymbol" SG_ 1531 SDCR_a007_faultReason_faultCurre "SDCR_a007_faultReason_faultCurrentsAtSpeed";
BA_ "SystemSignalLongSymbol" SG_ 1531 SDCR_a007_faultReason_unmitigate "SDCR_a007_faultReason_unmitigatedUCR";
BA_ "SystemSignalLongSymbol" SG_ 1531 SDCR_a007_faultReason_propagatin "SDCR_a007_faultReason_propagating3PS";
BA_ "Confidence" SG_ 1531 SDCR_a007_transientHandling 1;
BA_ "Confidence" SG_ 1531 SDCR_a007_maxAbsElcSpeed 1;
BA_ "Confidence" SG_ 1531 SDCR_a007_avgIa 1;
BA_ "Confidence" SG_ 1531 SDCR_a007_avgIb 1;
BA_ "Confidence" SG_ 1531 SDCR_a007_maxAbsCurrents 1;
BA_ "Confidence" SG_ 1531 SDCR_a010_boostRailV 1;
BA_ "Confidence" SG_ 1531 SDCR_a010_Vref 1;
BA_ "Confidence" SG_ 1531 SDCR_a011_IaAvg 1;
BA_ "Confidence" SG_ 1531 SDCR_a011_IbAvg 1;
BA_ "Confidence" SG_ 1531 SDCR_a012_boostRailV 1;
BA_ "Confidence" SG_ 1531 SDCR_a012_HVBackupSupplyV 1;
BA_ "Confidence" SG_ 1531 SDCR_a012_vBat 1;
BA_ "Confidence" SG_ 1531 SDCR_a013_boostRailV 1;
BA_ "Confidence" SG_ 1531 SDCR_a013_HVBackupSupplyV 1;
BA_ "Confidence" SG_ 1531 SDCR_a013_vBat 1;
BA_ "Confidence" SG_ 1531 SDCR_a014_boostRailV 1;
BA_ "Confidence" SG_ 1531 SDCR_a014_HVBackupSupplyV 1;
BA_ "Confidence" SG_ 1531 SDCR_a014_vBat 1;
BA_ "SystemSignalLongSymbol" SG_ 1531 SDCR_a015_reason_vPhaseShortedLo "SDCR_a015_reason_vPhaseShortedLow";
BA_ "SystemSignalLongSymbol" SG_ 1531 SDCR_a015_reason_vPhaseShortedHi "SDCR_a015_reason_vPhaseShortedHigh";
BA_ "Confidence" SG_ 1531 SDCR_a015_vBat 1;
BA_ "Confidence" SG_ 1531 SDCR_a015_va 1;
BA_ "Confidence" SG_ 1531 SDCR_a015_vb 1;
BA_ "Confidence" SG_ 1531 SDCR_a015_vc 1;
BA_ "SystemSignalLongSymbol" SG_ 1531 SDCR_a018_triggerReason_faultCur "SDCR_a018_triggerReason_faultCurrents";
BA_ "SystemSignalLongSymbol" SG_ 1531 SDCR_a018_triggerReason_hvBadAtS "SDCR_a018_triggerReason_hvBadAtSpeed";
BA_ "SystemSignalLongSymbol" SG_ 1531 SDCR_a018_triggerReason_highBack "SDCR_a018_triggerReason_highBackEMF";
BA_ "SystemSignalLongSymbol" SG_ 1531 SDCR_a018_hvPowerNotGoodQualifie "SDCR_a018_hvPowerNotGoodQualified";
BA_ "Confidence" SG_ 1531 SDCR_a018_HVBackupSupplyV 1;
BA_ "Confidence" SG_ 1531 SDCR_a018_boostRailV 1;
BA_ "Confidence" SG_ 1531 SDCR_a018_maxAbsSpeed 1;
BA_ "Confidence" SG_ 1531 SDCR_a018_vBat 1;
BA_ "SystemSignalLongSymbol" SG_ 1531 SDCR_a019_faultReason_faultCurre "SDCR_a019_faultReason_faultCurrentsAtSpeed";
BA_ "SystemSignalLongSymbol" SG_ 1531 SDCR_a019_faultReason_unmitigate "SDCR_a019_faultReason_unmitigatedUCR";
BA_ "SystemSignalLongSymbol" SG_ 1531 SDCR_a019_faultReason_propagatin "SDCR_a019_faultReason_propagating3PS";
BA_ "Confidence" SG_ 1531 SDCR_a019_transientHandling 1;
BA_ "Confidence" SG_ 1531 SDCR_a019_maxAbsElcSpeed 1;
BA_ "Confidence" SG_ 1531 SDCR_a019_avgIa 1;
BA_ "Confidence" SG_ 1531 SDCR_a019_avgIb 1;
BA_ "Confidence" SG_ 1531 SDCR_a019_maxAbsCurrents 1;
BA_ "Confidence" SG_ 1531 SDCR_a020_errorCode 1;
BA_ "Confidence" SG_ 1531 SDCR_a021_busBarTempC 1;
BA_ "GenSigSNA" SG_ 1531 SDCR_a021_busBarTempC "0";
BA_ "Confidence" SG_ 1531 SDCR_a021_busBarTempA 1;
BA_ "GenSigSNA" SG_ 1531 SDCR_a021_busBarTempA "0";
BA_ "Confidence" SG_ 1531 SDCR_a021_tempCVoltage 1;
BA_ "Confidence" SG_ 1531 SDCR_a021_tempAVoltage 1;
BA_ "Confidence" SG_ 1531 SDCR_a025_HVBackupSupplyV 1;
BA_ "Confidence" SG_ 1531 SDCR_a025_boostRailV 1;
BA_ "Confidence" SG_ 1531 SDCR_a029_lvState 1;
BA_ "Confidence" SG_ 1531 SDCR_a034_Ia 1;
BA_ "Confidence" SG_ 1531 SDCR_a034_Ib 1;
BA_ "Confidence" SG_ 1787 SDCR_udsResponseData 1;
BA_ "Confidence" SG_ 1835 TAS_alertID 1;
BA_ "Confidence" SG_ 1835 TAS_alertState 1;
BA_ "Confidence" SG_ 1835 TAS_a030_PWMdutyCycleFL 1;
BA_ "Confidence" SG_ 1835 TAS_a030_PWMfrequencyFL 1;
BA_ "Confidence" SG_ 1835 TAS_a030_PWMfaultFL 1;
BA_ "Confidence" SG_ 1835 TAS_a031_PWMdutyCycleFR 1;
BA_ "Confidence" SG_ 1835 TAS_a031_PWMfrequencyFR 1;
BA_ "Confidence" SG_ 1835 TAS_a031_PWMfaultFR 1;
BA_ "Confidence" SG_ 1835 TAS_a032_PWMdutyCycleRL 1;
BA_ "Confidence" SG_ 1835 TAS_a032_PWMfrequencyRL 1;
BA_ "Confidence" SG_ 1835 TAS_a032_PWMfaultRL 1;
BA_ "Confidence" SG_ 1835 TAS_a033_PWMdutyCycleRR 1;
BA_ "Confidence" SG_ 1835 TAS_a033_PWMfrequencyRR 1;
BA_ "Confidence" SG_ 1835 TAS_a033_PWMfaultRR 1;
BA_ "Confidence" SG_ 1835 TAS_a034_PWMdutyCycleFL 1;
BA_ "Confidence" SG_ 1835 TAS_a034_PWMfrequencyFL 1;
BA_ "Confidence" SG_ 1835 TAS_a034_PWMfaultFL 1;
BA_ "Confidence" SG_ 1835 TAS_a035_PWMdutyCycleFR 1;
BA_ "Confidence" SG_ 1835 TAS_a035_PWMfrequencyFR 1;
BA_ "Confidence" SG_ 1835 TAS_a035_PWMfaultFR 1;
BA_ "Confidence" SG_ 1835 TAS_a036_PWMdutyCycleRL 1;
BA_ "Confidence" SG_ 1835 TAS_a036_PWMfrequencyRL 1;
BA_ "Confidence" SG_ 1835 TAS_a036_PWMfaultRL 1;
BA_ "Confidence" SG_ 1835 TAS_a037_PWMdutyCycleRR 1;
BA_ "Confidence" SG_ 1835 TAS_a037_PWMfrequencyRR 1;
BA_ "Confidence" SG_ 1835 TAS_a037_PWMfaultRR 1;
BA_ "Confidence" SG_ 1835 TAS_a038_PWMdutyCycleFL 1;
BA_ "Confidence" SG_ 1835 TAS_a038_PWMfrequencyFL 1;
BA_ "Confidence" SG_ 1835 TAS_a038_PWMfaultFL 1;
BA_ "Confidence" SG_ 1835 TAS_a039_PWMdutyCycleFR 1;
BA_ "Confidence" SG_ 1835 TAS_a039_PWMfrequencyFR 1;
BA_ "Confidence" SG_ 1835 TAS_a039_PWMfaultFR 1;
BA_ "Confidence" SG_ 1835 TAS_a040_PWMdutyCycleRL 1;
BA_ "Confidence" SG_ 1835 TAS_a040_PWMfrequencyRL 1;
BA_ "Confidence" SG_ 1835 TAS_a040_PWMfaultRL 1;
BA_ "Confidence" SG_ 1835 TAS_a041_PWMdutyCycleRR 1;
BA_ "Confidence" SG_ 1835 TAS_a041_PWMfrequencyRR 1;
BA_ "Confidence" SG_ 1835 TAS_a041_PWMfaultRR 1;
BA_ "Confidence" SG_ 1835 TAS_a070_voltage12V 1;
BA_ "Confidence" SG_ 1835 TAS_a071_voltage12V 1;
BA_ "Confidence" SG_ 1835 TAS_a072_voltage5VOnBoard 1;
BA_ "Confidence" SG_ 1835 TAS_a073_voltage5VOnBoard 1;
BA_ "Confidence" SG_ 1835 TAS_a074_voltage5VOffBoard 1;
BA_ "Confidence" SG_ 1835 TAS_a075_voltage5VOffBoard 1;
BA_ "Confidence" SG_ 1835 TAS_a076_voltage5VOffBoard 1;
BA_ "Confidence" SG_ 1835 TAS_a077_sensorVoltage 1;
BA_ "Confidence" SG_ 1835 TAS_a077_sensorRefVoltage 1;
BA_ "Confidence" SG_ 1835 TAS_a078_sensorVoltage 1;
BA_ "Confidence" SG_ 1835 TAS_a078_sensorRefVoltage 1;
BA_ "Confidence" SG_ 1835 TAS_a080_voltage5VHeight 1;
BA_ "Confidence" SG_ 1835 TAS_a081_voltage5VHeight 1;
BA_ "Confidence" SG_ 1835 TAS_a082_voltage5VHeight 1;
BA_ "Confidence" SG_ 1835 TAS_a083_voltage5VAnalog 1;
BA_ "Confidence" SG_ 1835 TAS_a084_voltage5VAnalog 1;
BA_ "Confidence" SG_ 1835 TAS_a085_voltage5VAnalog 1;
BA_ "Confidence" SG_ 1835 TAS_a086_voltage12VSwitched 1;
BA_ "Confidence" SG_ 1835 TAS_a087_voltage12VSwitched 1;
BA_ "SystemSignalLongSymbol" SG_ 1835 TAS_a098_VCFRONT_LVPowerState_MI "TAS_a098_VCFRONT_LVPowerState_MIA";
BA_ "SystemSignalLongSymbol" SG_ 1835 TAS_a098_VCFRONT_systemStatus_MI "TAS_a098_VCFRONT_systemStatus_MIA";
BA_ "SystemSignalLongSymbol" SG_ 1835 TAS_a099_UI_driverAssistMapData_ "TAS_a099_UI_driverAssistMapData_MIA";
BA_ "SystemSignalLongSymbol" SG_ 1835 TAS_a099_UI_suspensionControl_MI "TAS_a099_UI_suspensionControl_MIA";
BA_ "Confidence" SG_ 1835 TAS_a164_detectedDamperSolenoid 1;
BA_ "Confidence" SG_ 1835 TAS_a164_expectedDamperSolenoid 1;
BA_ "Confidence" SG_ 1835 TAS_a165_damperValveFault 1;
BA_ "Confidence" SG_ 1835 TAS_a166_damperValveFault 1;
BA_ "Confidence" SG_ 1835 TAS_a167_damperValveFault 1;
BA_ "Confidence" SG_ 1835 TAS_a168_damperValveFault 1;
BA_ "Confidence" SG_ 1835 TAS_a169_damperValveFault 1;
BA_ "Confidence" SG_ 1835 TAS_a170_damperValveFault 1;
BA_ "Confidence" SG_ 1835 TAS_a171_damperValveFault 1;
BA_ "Confidence" SG_ 1835 TAS_a172_damperValveFault 1;
BA_ "Confidence" SG_ 1835 TAS_a173_heightDelta_mm 1;
BA_ "Confidence" SG_ 1835 TAS_a174_heightDelta_mm 1;
BA_ "Confidence" SG_ 1835 TAS_a175_heightDelta_mm 1;
BA_ "Confidence" SG_ 1835 TAS_a176_heightDelta_mm 1;
BA_ "Confidence" SG_ 1835 TAS_a190_a2bFaultType 1;
BA_ "Confidence" SG_ 1835 TAS_a190_a2bInterruptType 1;
BA_ "Confidence" SG_ 1835 TAS_a190_a2bFaultSource 1;
BA_ "Confidence" SG_ 1835 TAS_a191_a2bFaultType 1;
BA_ "Confidence" SG_ 1835 TAS_a191_a2bInterruptType 1;
BA_ "Confidence" SG_ 1835 TAS_a191_a2bFaultSource 1;
BA_ "Confidence" SG_ 1835 TAS_a192_rideHeightVelDspFL 1;
BA_ "Confidence" SG_ 1835 TAS_a192_rideHeightVelDspFR 1;
BA_ "Confidence" SG_ 1835 TAS_a192_rideHeightVelDspRL 1;
BA_ "Confidence" SG_ 1835 TAS_a192_rideHeightVelDspRR 1;
BA_ "Confidence" SG_ 1835 TAS_a192_rideHeightVelObserverFL 1;
BA_ "Confidence" SG_ 1835 TAS_a192_rideHeightVelObserverFR 1;
BA_ "Confidence" SG_ 1835 TAS_a192_rideHeightVelObserverRL 1;
BA_ "Confidence" SG_ 1835 TAS_a192_rideHeightVelObserverRR 1;
BA_ "Confidence" SG_ 1835 TAS_a210_heightSensorDeltaFL 1;
BA_ "Confidence" SG_ 1835 TAS_a210_heightSensorDeltaFR 1;
BA_ "Confidence" SG_ 1835 TAS_a210_heightSensorDeltaRL 1;
BA_ "Confidence" SG_ 1835 TAS_a210_heightSensorDeltaRR 1;
BA_ "Confidence" SG_ 1835 TAS_a220_galleryPressure 1;
BA_ "Confidence" SG_ 1835 TAS_a220_timeInExhaust 1;
BA_ "Confidence" SG_ 1835 TAS_a221_galleryPressureDelta 1;
BA_ "Confidence" SG_ 1835 TAS_a221_timeInIdle 1;
BA_ "Confidence" SG_ 1835 TAS_a222_galleryPressureDelta 1;
BA_ "Confidence" SG_ 1835 TAS_a223_galleryPressure 1;
BA_ "Confidence" SG_ 1835 TAS_a224_galleryPressure 1;
BA_ "Confidence" SG_ 1835 TAS_a225_galleryPressure 1;
BA_ "Confidence" SG_ 1835 TAS_a226_PWMdutyCycleFL 1;
BA_ "Confidence" SG_ 1835 TAS_a226_PWMfrequencyFL 1;
BA_ "Confidence" SG_ 1835 TAS_a226_PWMfaultFL 1;
BA_ "Confidence" SG_ 1835 TAS_a227_PWMdutyCycleFR 1;
BA_ "Confidence" SG_ 1835 TAS_a227_PWMfrequencyFR 1;
BA_ "Confidence" SG_ 1835 TAS_a227_PWMfaultFR 1;
BA_ "Confidence" SG_ 1835 TAS_a228_PWMdutyCycleRL 1;
BA_ "Confidence" SG_ 1835 TAS_a228_PWMfrequencyRL 1;
BA_ "Confidence" SG_ 1835 TAS_a228_PWMfaultRL 1;
BA_ "Confidence" SG_ 1835 TAS_a229_PWMdutyCycleRR 1;
BA_ "Confidence" SG_ 1835 TAS_a229_PWMfrequencyRR 1;
BA_ "Confidence" SG_ 1835 TAS_a229_PWMfaultRR 1;
BA_ "Confidence" SG_ 1835 TAS_a232_detectedSuspensionType 1;
BA_ "Confidence" SG_ 1835 TAS_a232_expectedSuspensionType 1;
BA_ "Confidence" SG_ 1835 TAS_a234_detectedDamperHydraulic 1;
BA_ "Confidence" SG_ 1835 TAS_a234_expectedDamperHydraulic 1;
BA_ "Confidence" SG_ 1835 TAS_a240_adjustCountRatioSpring 1;
BA_ "Confidence" SG_ 1835 TAS_a240_adjustCountRatio 1;
BA_ "GenSigSNA" SG_ 1835 TAS_a240_adjustCountRatio "255";
BA_ "Confidence" SG_ 1835 TAS_a240_adjustTimeRatioSpring 1;
BA_ "Confidence" SG_ 1835 TAS_a240_adjustTimeRatio 1;
BA_ "GenSigSNA" SG_ 1835 TAS_a240_adjustTimeRatio "255";
BA_ "Confidence" SG_ 1835 TAS_a240_compExhTimeRatio 1;
BA_ "Confidence" SG_ 1835 TAS_a240_crossPressure 1;
BA_ "Confidence" SG_ 1835 TAS_a285_twistLevel 1;
BA_ "Confidence" SG_ 1835 TAS_a290_twistLevel 1;
BA_ "Confidence" SG_ 1835 TAS_a291_frontAxleHeight 1;
BA_ "Confidence" SG_ 1835 TAS_a292_rearAxleHeight 1;
BA_ "Confidence" SG_ 1835 TAS_a293_frontAxleHeight 1;
BA_ "Confidence" SG_ 1835 TAS_a294_rearAxleHeight 1;
BA_ "Confidence" SG_ 1835 TAS_a295_targetHeight 1;
BA_ "Confidence" SG_ 1835 TAS_a296_detectedChassisType 1;
BA_ "Confidence" SG_ 1835 TAS_a296_expectedChassisType 1;
BA_ "Confidence" SG_ 1835 TAS_a319_detectedDrivetrainType 1;
BA_ "Confidence" SG_ 1835 TAS_a319_expectedDrivetrainType 1;
BA_ "Confidence" SG_ 852 TAS_matrixIndex 1;
BA_ "SystemSignalLongSymbol" SG_ 852 TAS_a066_undefinedInstructionAbo "TAS_a066_undefinedInstructionAbort";
BA_ "SystemSignalLongSymbol" SG_ 852 TAS_a150_accelAvgImplausible_FL_ "TAS_a150_accelAvgImplausible_FL_X";
BA_ "SystemSignalLongSymbol" SG_ 852 TAS_a151_accelAvgImplausible_FL_ "TAS_a151_accelAvgImplausible_FL_Y";
BA_ "SystemSignalLongSymbol" SG_ 852 TAS_a152_accelAvgImplausible_FL_ "TAS_a152_accelAvgImplausible_FL_Z";
BA_ "SystemSignalLongSymbol" SG_ 852 TAS_a153_accelAvgImplausible_FR_ "TAS_a153_accelAvgImplausible_FR_X";
BA_ "SystemSignalLongSymbol" SG_ 852 TAS_a154_accelAvgImplausible_FR_ "TAS_a154_accelAvgImplausible_FR_Y";
BA_ "SystemSignalLongSymbol" SG_ 852 TAS_a155_accelAvgImplausible_FR_ "TAS_a155_accelAvgImplausible_FR_Z";
BA_ "SystemSignalLongSymbol" SG_ 852 TAS_a156_accelAvgImplausible_RL_ "TAS_a156_accelAvgImplausible_RL_X";
BA_ "SystemSignalLongSymbol" SG_ 852 TAS_a157_accelAvgImplausible_RL_ "TAS_a157_accelAvgImplausible_RL_Y";
BA_ "SystemSignalLongSymbol" SG_ 852 TAS_a158_accelAvgImplausible_RL_ "TAS_a158_accelAvgImplausible_RL_Z";
BA_ "SystemSignalLongSymbol" SG_ 852 TAS_a159_accelAvgImplausible_RR_ "TAS_a159_accelAvgImplausible_RR_X";
BA_ "SystemSignalLongSymbol" SG_ 852 TAS_a160_accelAvgImplausible_RR_ "TAS_a160_accelAvgImplausible_RR_Y";
BA_ "SystemSignalLongSymbol" SG_ 852 TAS_a161_accelAvgImplausible_RR_ "TAS_a161_accelAvgImplausible_RR_Z";
BA_ "SystemSignalLongSymbol" SG_ 852 TAS_a192_rideHeightObserverDiver "TAS_a192_rideHeightObserverDivergence";
BA_ "SystemSignalLongSymbol" SG_ 852 TAS_a197_invalidAdaptiveModeRequ "TAS_a197_invalidAdaptiveModeRequested";
BA_ "Confidence" SG_ 1627 TAS_udsResponseData 1;
BA_ "Confidence" SG_ 1410 TCU_alertID 1;
BA_ "Confidence" SG_ 1410 TCU_alertState 1;
BA_ "Confidence" SG_ 1409 TCU_logMux 1;
BA_ "Confidence" SG_ 1409 TCU_cpuTemp 1;
BA_ "Confidence" SG_ 1409 TCU_cpuUsage 1;
BA_ "Confidence" SG_ 1409 TCU_mdmCoreTemperature 1;
BA_ "Confidence" SG_ 1409 TCU_availableMemory 1;
BA_ "Confidence" SG_ 1409 TCU_pwm 1;
BA_ "Confidence" SG_ 1409 TCU_pwmcap 1;
BA_ "Confidence" SG_ 1409 TCU_totalResumes 1;
BA_ "Confidence" SG_ 1409 TCU_mdmUplinkQueueSize 1;
BA_ "Confidence" SG_ 1409 TCU_mdmRSRP 1;
BA_ "Confidence" SG_ 1409 TCU_mdmSINR 1;
BA_ "Confidence" SG_ 1409 TCU_mdmUplinkAllowedRate 1;
BA_ "Confidence" SG_ 1409 TCU_mdmIMSStatus 1;
BA_ "Confidence" SG_ 1409 TCU_mdmBusyActive 1;
BA_ "GenSigSNA" SG_ 1409 TCU_mdmBusyActive "4294967295";
BA_ "Confidence" SG_ 1408 TCU_statusMux 1;
BA_ "Confidence" SG_ 1408 TCU_wakeUpReason 1;
BA_ "GenSigSNA" SG_ 1408 TCU_wakeUpReason "4294967295";
BA_ "Confidence" SG_ 1408 TCU_goingToSleep 1;
BA_ "GenSigSNA" SG_ 1408 TCU_goingToSleep "4294967295";
BA_ "Confidence" SG_ 1631 TPMS_udsResponseData 1;
VAL_ 998 RCU_matrixIndex 0 "RCU_AlertMatrix0" ;
VAL_ 831 RCU_infoIndex 255 "END" 31 "SUBCOMPONENT_GITHASH" 30 "PACKAGE_SN_8_14" 29 "PACKAGE_SN_1_7" 27 "PACKAGE_PN_15_20" 26 "PACKAGE_PN_8_14" 25 "PACKAGE_PN_1_7" 23 "SUBCOMPONENT2" 22 "VARIANTCRC" 20 "UDS_PROTOCOL_BOOTCRC" 19 "VERSION_DEPRECATED" 18 "BOOTLOADER_GITHASH" 17 "APP_GITHASH" 16 "SUBCOMPONENT" 15 "BOOTLOADER_CRC" 14 "BOOTLOADER_SVN" 13 "APP_CRC" 11 "PCBAID_ASSYID_USAGEID" 10 "BUILD_HWID_COMPONENTID" 9 "DEPRECATED_9" 8 "DEPRECATED_8" 7 "DEPRECATED_7" 6 "DEPRECATED_6" 5 "DEPRECATED_5" 4 "DEPRECATED_4" 3 "DEPRECATED_3" 2 "DEPRECATED_2" 1 "DEPRECATED_1" 0 "DEPRECATED_0" ;
VAL_ 1344 SCCM_alertID 126 "a126_turnIndicatorHallMagOutOfRange" 125 "a125_turnIndicatorHallAngleMismatch" 124 "a124_turnIndicatorIdleInvalid" 123 "a123_turnIndicatorStuckActive" 122 "a122_turnIndicatorSpeedInvalid" 121 "a121_turnIndicatorAngleInvalid" 82 "a082_runtimeTestFailed" 81 "a081_startupTestFailed" 80 "a080_ADCSelfTestFailed" 79 "a079_chipTempOutOfRange" 78 "a078_ADCCalibrationError" 77 "a077_gearAngleNotPlausible" 76 "a076_memoryError_2" 75 "a075_hardwareError_2" 74 "a074_PLLLossOfLock" 73 "a073_watchdogReset" 72 "a072_spiBitErrors" 71 "a071_angleHallSensorError" 70 "a070_angleTrimMismatch" 69 "a069_calibrationMismatch" 68 "a068_CANLVPowerState_LOC" 67 "a067_CANBusOff_2" 66 "a066_angleSpeedNotPlausible" 65 "a065_angleNotPlausible" 64 "a064_angleSpeedOutOfRange_2" 63 "a063_angleOutOfRange_2" 62 "a062_voltageLow_2" 61 "a061_voltageHigh_2" 29 "a029_parkButtonMalfunction" 28 "a028_parkButtonShortToGround" 27 "a027_parkButtonOpenCircuit" 26 "a026_parkButtonInvalidSignal" 25 "a025_runTimeError" 24 "a024_gearStalkGenErr" 23 "a023_gearStalkShortCircuit" 22 "a022_gearStalkOpenCircuit" 21 "a021_gearStalkSignalInvalid" 20 "a020_angleInternalError" 19 "a019_angleOutOfRange" 18 "a018_angleSpeedOutOfRange" 17 "a017_memoryError" 16 "a016_hardwareError" 15 "a015_softwareError" 14 "a014_voltageLow" 13 "a013_voltageHigh" 12 "a012_turnGenErr" 11 "a011_turnIndHWErr" 10 "a010_turnIndShortToGnd" 9 "a009_turnIndOpen" 8 "a008_turnIndInvalidTrans" 7 "a007_turnIndComInfo" 6 "a006_tipWipeShortToGND" 5 "a005_tipWipeOpen" 4 "a004_highBeamShortToGND" 3 "a003_highBeamOpen" 2 "a002_CANTOut" 1 "a001_CANBusOff" 0 "ALERT_DO_NOT_USE_ZERO" ;
VAL_ 1344 SCCM_alertState 1 "SET" 0 "CLEARED" ;
VAL_ 1344 SCCM_a063_UntrimmedAngle 16383 "SNA" ;
VAL_ 1344 SCCM_a064_Speed 16383 "SNA" ;
VAL_ 1531 SDCR_alertID 34 "a034_phaseCurrentIrrational" 33 "a033_placeholder33" 32 "a032_placeholder32" 31 "a031_placeholder31" 30 "a030_placeholder30" 29 "a029_diMIA" 28 "a028_vcLVStateMIA" 27 "a027_diCanMIA" 26 "a026_faultCurrentMonitoringDisabled" 25 "a025_diSwitchingFdbkIrrational" 24 "a024_gtwMIA" 23 "a023_ecuLogAvailable" 22 "a022_TaskInitError" 21 "a021_busBarTempIrrational" 20 "a020_eepromSPIError" 19 "a019_historicalFaultCurrents" 18 "a018_historicalPyroTrigger" 17 "a017_adcSPIError" 16 "a016_systemReset" 15 "a015_phaseVIrrational" 14 "a014_vBusIrrational" 13 "a013_vBkupIrrational" 12 "a012_vBoostSecIrrational" 11 "a011_phaseCurrentOffset" 10 "a010_vrefIrrational" 9 "a009_uartVersionMismatch" 8 "a008_hvlinkMIA" 7 "a007_faultCurrentsDetected" 6 "a006_pyroTriggered" 5 "a005_motorSpeedIrrational" 4 "a004_pmRunningFdbkIrrational" 3 "a003_diUartMIA" 2 "a002_diPstSkipped" 1 "a001_powerOnSelfTestFailed" 0 "ALERT_DO_NOT_USE_ZERO" ;
VAL_ 1531 SDCR_alertState 1 "SET" 0 "CLEARED" ;
VAL_ 1531 SDCR_a001_fromState 7 "SKIPPED" 6 "FAILED" 5 "PASSED" 4 "TEST_PYRO_L_ON" 3 "TEST_PYRO_BOTH_OFF2" 2 "TEST_PYRO_H_ON" 1 "TEST_PYRO_BOTH_OFF1" 0 "PENDING" ;
VAL_ 1531 SDCR_a007_transientHandling 3 "3PS_WAITED" 2 "3PS_EARLY_EXIT" 1 "SKIPPED_3PS" 0 "ALL_SKIPPED" ;
VAL_ 1531 SDCR_a019_transientHandling 3 "3PS_WAITED" 2 "3PS_EARLY_EXIT" 1 "SKIPPED_3PS" 0 "ALL_SKIPPED" ;
VAL_ 1531 SDCR_a020_errorCode 201 "FAILED_WRITE_SANITY_CHECK" 200 "FAILED_READ_SANITY_CHECK" 4 "GENERIC_SPI_ERROR" 3 "MUTEX_ERROR" 2 "PAGE_ROLLOVER" 1 "ADDRESS_OUT_OF_BOUNDS" ;
VAL_ 1531 SDCR_a021_busBarTempC 0 "SNA" ;
VAL_ 1531 SDCR_a021_busBarTempA 0 "SNA" ;
VAL_ 1531 SDCR_a029_lvState 3 "FAULT" 2 "GOING_DOWN" 1 "ON" 0 "OFF" ;
VAL_ 1835 TAS_alertID 333 "a333_levelingThresholds2" 332 "a332_levelingThresholds1" 322 "a322_speedBumpAttributes2" 321 "a321_speedBumpAttributes1" 320 "a320_offsetsRotationalRates" 319 "a319_drivetrainTypeMismatch" 318 "a318_dampingCntrlInputMIA" 317 "a317_offsetsRotationalRates" 316 "a316_offsetsAccels" 315 "a315_pcbaHighTemp" 314 "a314_dampingReduced" 313 "a313_dampingCntrlDisabled" 312 "a312_rotationalRatesMIA" 311 "a311_accelsMIA" 310 "a310_controlFrozenData" 309 "a309_controlFrozen" 308 "a308_endstopBoundaryRbnd" 307 "a307_endstopBoundaryComp" 306 "a306_hardwareProtectFrozen" 305 "a305_newEndstopPosition" 304 "a304_massEstimateFrozenData" 303 "a303_massEstimateFrozen" 301 "a301_offsetEstimateData2" 300 "a300_offsetEstimateData1" 299 "a299_offsetEstimateTooLarge" 298 "a298_vinNotLearned" 297 "a297_vinMismatch" 296 "a296_chassisTypeMismatch" 295 "a295_targetHeightNotMet" 294 "a294_rearAxleTooLow" 293 "a293_frontAxleTooLow" 292 "a292_rearAxleTooHigh" 291 "a291_frontAxleTooHigh" 290 "a290_twistSustainedAtSpeed" 289 "a289_driveCycleStats4" 288 "a288_driveCycleStats3" 287 "a287_driveCycleStats2" 286 "a286_driveCycleStats1" 285 "a285_twistSustainedUserVis" 284 "a284_serviceRunModeActive" 240 "a240_airSpringLeak" 234 "a234_damperHydraulicMismatch" 233 "a233_compressorStuckOn" 232 "a232_suspensionTypeMismatch" 231 "a231_notifyRoughRoadRaise" 230 "a230_notifyGeofence" 229 "a229_PWMfastDetectRR" 228 "a228_PWMfastDetectRL" 227 "a227_PWMfastDetectFR" 226 "a226_PWMfastDetectFL" 225 "a225_galleryPressureTooHigh" 224 "a224_openAirline" 223 "a223_blockedAirline" 222 "a222_compressorPrefillFault" 221 "a221_valveLeakDetected" 220 "a220_exhaustGalleryFault" 218 "a218_limpHomeMode40" 217 "a217_limpHomeMode30" 216 "a216_limpHomeMode20" 215 "a215_limpHomeMode10" 214 "a214_redWarningLamp" 213 "a213_yellowWarningLamp" 211 "a211_noRideHeightCalib" 210 "a210_outOfRangeCalibration" 201 "a201_low12VBattery" 200 "a200_jackModeActive" 197 "a197_invalidAdaptiveModeRequested" 196 "a196_adaptiveDampingUsingDSP" 195 "a195_a2bRearAxleDataError" 194 "a194_a2bFrontAxleDataError" 193 "a193_EPAS3P_MIA" 192 "a192_rideHeightObserverDivergence" 191 "a191_a2bRearAxleFault" 190 "a190_a2bFrontAxleFault" 176 "a176_staticLeakDetectRR" 175 "a175_staticLeakDetectRL" 174 "a174_staticLeakDetectFR" 173 "a173_staticLeakDetectFL" 172 "a172_damperValveRbndRR" 171 "a171_damperValveCompRR" 170 "a170_damperValveRbndRL" 169 "a169_damperValveCompRL" 168 "a168_damperValveRbndFR" 167 "a167_damperValveCompFR" 166 "a166_damperValveRbndFL" 165 "a165_damperValveCompFL" 164 "a164_damperSolenoidMismatch" 161 "a161_accelAvgImplausible_RR_Z" 160 "a160_accelAvgImplausible_RR_Y" 159 "a159_accelAvgImplausible_RR_X" 158 "a158_accelAvgImplausible_RL_Z" 157 "a157_accelAvgImplausible_RL_Y" 156 "a156_accelAvgImplausible_RL_X" 155 "a155_accelAvgImplausible_FR_Z" 154 "a154_accelAvgImplausible_FR_Y" 153 "a153_accelAvgImplausible_FR_X" 152 "a152_accelAvgImplausible_FL_Z" 151 "a151_accelAvgImplausible_FL_Y" 150 "a150_accelAvgImplausible_FL_X" 107 "a107_HighStackUsage" 106 "a106_HighCPULoad" 105 "a105_ECUDebugMode" 103 "a103_GTW_MIA" 102 "a102_DI_MIA" 101 "a101_ESP_MIA" 100 "a100_RCM_MIA" 99 "a099_UI_MIA" 98 "a098_VCFRONT_MIA" 93 "a093_OTPError" 87 "a087_overVoltage12VSwtchd" 86 "a086_underVoltage12VSwtchd" 85 "a085_overVoltage5VAnalog" 84 "a084_underVoltage5VAnalog" 83 "a083_shortCircuit5VAnalog" 82 "a082_overVoltage5VHeight" 81 "a081_underVoltage5VHeight" 80 "a080_shortCircuit5VHeight" 78 "a078_pressureSigVTooHigh" 77 "a077_pressureSigVTooLow" 76 "a076_overVoltage5VOffBoard" 75 "a075_underVoltage5VOffBoard" 74 "a074_shortCircuit5VOffBoard" 73 "a073_underVoltage5VOnBoard" 72 "a072_shortCircuit5VOnBoard" 71 "a071_overVoltage12V" 70 "a070_underVoltage12V" 67 "a067_reservedHandlerAbort" 66 "a066_undefinedInstructionAbort" 65 "a065_ahbWriteFault" 64 "a064_abortFaultExt" 63 "a063_abortFault" 62 "a062_XCPWasConnected" 61 "a061_XCPConnected" 46 "a046_Task1000msError" 45 "a045_Task100msError" 44 "a044_Task10msError" 43 "a043_Task1msError" 41 "a041_PWMopenRR" 40 "a040_PWMopenRL" 39 "a039_PWMopenFR" 38 "a038_PWMopenFL" 37 "a037_PWMshortRR" 36 "a036_PWMshortRL" 35 "a035_PWMshortFR" 34 "a034_PWMshortFL" 33 "a033_PWMerrorRR" 32 "a032_PWMerrorRL" 31 "a031_PWMerrorFR" 30 "a030_PWMerrorFL" 25 "a025_CrashEvent" 24 "a024_prefetchAbort" 23 "a023_rtosResetRequested" 22 "a022_TaskInitError" 21 "a021_TaskSchedulerError" 16 "a016_NVMMRecordError" 15 "a015_NVMMError" 12 "a012_CPUReset" 3 "a003_SWAssertion" 2 "a002_PowerLossReset" 1 "a001_WatchdogReset" 0 "ALERT_DO_NOT_USE_ZERO" ;
VAL_ 1835 TAS_alertState 1 "SET" 0 "CLEARED" ;
VAL_ 1835 TAS_a030_PWMfaultFL 9 "NONE" 8 "COUNT" 7 "OPEN_CIRCUIT" 6 "SHORT_CIRCUIT" 5 "MIA" 4 "OVER_MAX_DELTA_DUTY" 3 "UNDER_MIN_PERIOD" 2 "OVER_MAX_PERIOD" 1 "UNDER_MIN_DUTY" 0 "OVER_MAX_DUTY" ;
VAL_ 1835 TAS_a031_PWMfaultFR 9 "NONE" 8 "COUNT" 7 "OPEN_CIRCUIT" 6 "SHORT_CIRCUIT" 5 "MIA" 4 "OVER_MAX_DELTA_DUTY" 3 "UNDER_MIN_PERIOD" 2 "OVER_MAX_PERIOD" 1 "UNDER_MIN_DUTY" 0 "OVER_MAX_DUTY" ;
VAL_ 1835 TAS_a032_PWMfaultRL 9 "NONE" 8 "COUNT" 7 "OPEN_CIRCUIT" 6 "SHORT_CIRCUIT" 5 "MIA" 4 "OVER_MAX_DELTA_DUTY" 3 "UNDER_MIN_PERIOD" 2 "OVER_MAX_PERIOD" 1 "UNDER_MIN_DUTY" 0 "OVER_MAX_DUTY" ;
VAL_ 1835 TAS_a033_PWMfaultRR 9 "NONE" 8 "COUNT" 7 "OPEN_CIRCUIT" 6 "SHORT_CIRCUIT" 5 "MIA" 4 "OVER_MAX_DELTA_DUTY" 3 "UNDER_MIN_PERIOD" 2 "OVER_MAX_PERIOD" 1 "UNDER_MIN_DUTY" 0 "OVER_MAX_DUTY" ;
VAL_ 1835 TAS_a034_PWMfaultFL 9 "NONE" 8 "COUNT" 7 "OPEN_CIRCUIT" 6 "SHORT_CIRCUIT" 5 "MIA" 4 "OVER_MAX_DELTA_DUTY" 3 "UNDER_MIN_PERIOD" 2 "OVER_MAX_PERIOD" 1 "UNDER_MIN_DUTY" 0 "OVER_MAX_DUTY" ;
VAL_ 1835 TAS_a035_PWMfaultFR 9 "NONE" 8 "COUNT" 7 "OPEN_CIRCUIT" 6 "SHORT_CIRCUIT" 5 "MIA" 4 "OVER_MAX_DELTA_DUTY" 3 "UNDER_MIN_PERIOD" 2 "OVER_MAX_PERIOD" 1 "UNDER_MIN_DUTY" 0 "OVER_MAX_DUTY" ;
VAL_ 1835 TAS_a036_PWMfaultRL 9 "NONE" 8 "COUNT" 7 "OPEN_CIRCUIT" 6 "SHORT_CIRCUIT" 5 "MIA" 4 "OVER_MAX_DELTA_DUTY" 3 "UNDER_MIN_PERIOD" 2 "OVER_MAX_PERIOD" 1 "UNDER_MIN_DUTY" 0 "OVER_MAX_DUTY" ;
VAL_ 1835 TAS_a037_PWMfaultRR 9 "NONE" 8 "COUNT" 7 "OPEN_CIRCUIT" 6 "SHORT_CIRCUIT" 5 "MIA" 4 "OVER_MAX_DELTA_DUTY" 3 "UNDER_MIN_PERIOD" 2 "OVER_MAX_PERIOD" 1 "UNDER_MIN_DUTY" 0 "OVER_MAX_DUTY" ;
VAL_ 1835 TAS_a038_PWMfaultFL 9 "NONE" 8 "COUNT" 7 "OPEN_CIRCUIT" 6 "SHORT_CIRCUIT" 5 "MIA" 4 "OVER_MAX_DELTA_DUTY" 3 "UNDER_MIN_PERIOD" 2 "OVER_MAX_PERIOD" 1 "UNDER_MIN_DUTY" 0 "OVER_MAX_DUTY" ;
VAL_ 1835 TAS_a039_PWMfaultFR 9 "NONE" 8 "COUNT" 7 "OPEN_CIRCUIT" 6 "SHORT_CIRCUIT" 5 "MIA" 4 "OVER_MAX_DELTA_DUTY" 3 "UNDER_MIN_PERIOD" 2 "OVER_MAX_PERIOD" 1 "UNDER_MIN_DUTY" 0 "OVER_MAX_DUTY" ;
VAL_ 1835 TAS_a040_PWMfaultRL 9 "NONE" 8 "COUNT" 7 "OPEN_CIRCUIT" 6 "SHORT_CIRCUIT" 5 "MIA" 4 "OVER_MAX_DELTA_DUTY" 3 "UNDER_MIN_PERIOD" 2 "OVER_MAX_PERIOD" 1 "UNDER_MIN_DUTY" 0 "OVER_MAX_DUTY" ;
VAL_ 1835 TAS_a041_PWMfaultRR 9 "NONE" 8 "COUNT" 7 "OPEN_CIRCUIT" 6 "SHORT_CIRCUIT" 5 "MIA" 4 "OVER_MAX_DELTA_DUTY" 3 "UNDER_MIN_PERIOD" 2 "OVER_MAX_PERIOD" 1 "UNDER_MIN_DUTY" 0 "OVER_MAX_DUTY" ;
VAL_ 1835 TAS_a164_detectedDamperSolenoid 4 "NC_COMPRESSION_NC_REBOUND" 3 "NC_COMPRESSION_NO_REBOUND" 2 "NO_COMPRESSION_NC_REBOUND" 1 "NO_COMPRESSION_NO_REBOUND" 0 "UNKNOWN" ;
VAL_ 1835 TAS_a164_expectedDamperSolenoid 4 "NC_COMPRESSION_NC_REBOUND" 3 "NC_COMPRESSION_NO_REBOUND" 2 "NO_COMPRESSION_NC_REBOUND" 1 "NO_COMPRESSION_NO_REBOUND" 0 "UNKNOWN" ;
VAL_ 1835 TAS_a165_damperValveFault 15 "REMOTE_VALVE_FAULTED" 14 "POSTIVE_TO_NEGATIVE_SHORT" 13 "DRIVER_OVER_TEMPERATURE" 12 "FEEDBACK_CURRENT_MIA" 11 "TARGET_CURRENT_MIA" 10 "LOW_SIDE_STATUS_IMPLAUSIBLE" 9 "CURRENT_MISMATCH" 8 "CURRENT_IMPLAUSIBLE" 7 "HIGH_RESISTANCE" 6 "LOW_RESISTANCE" 5 "CROSS_CONNECTION_SHORT" 4 "OPEN_CIRCUIT" 3 "VOLTAGE_ON_CIRCUIT" 2 "SHORT_TO_GND" 1 "SHORT_TO_VBAT" 0 "NONE_UNUSED" ;
VAL_ 1835 TAS_a166_damperValveFault 15 "REMOTE_VALVE_FAULTED" 14 "POSTIVE_TO_NEGATIVE_SHORT" 13 "DRIVER_OVER_TEMPERATURE" 12 "FEEDBACK_CURRENT_MIA" 11 "TARGET_CURRENT_MIA" 10 "LOW_SIDE_STATUS_IMPLAUSIBLE" 9 "CURRENT_MISMATCH" 8 "CURRENT_IMPLAUSIBLE" 7 "HIGH_RESISTANCE" 6 "LOW_RESISTANCE" 5 "CROSS_CONNECTION_SHORT" 4 "OPEN_CIRCUIT" 3 "VOLTAGE_ON_CIRCUIT" 2 "SHORT_TO_GND" 1 "SHORT_TO_VBAT" 0 "NONE_UNUSED" ;
VAL_ 1835 TAS_a167_damperValveFault 15 "REMOTE_VALVE_FAULTED" 14 "POSTIVE_TO_NEGATIVE_SHORT" 13 "DRIVER_OVER_TEMPERATURE" 12 "FEEDBACK_CURRENT_MIA" 11 "TARGET_CURRENT_MIA" 10 "LOW_SIDE_STATUS_IMPLAUSIBLE" 9 "CURRENT_MISMATCH" 8 "CURRENT_IMPLAUSIBLE" 7 "HIGH_RESISTANCE" 6 "LOW_RESISTANCE" 5 "CROSS_CONNECTION_SHORT" 4 "OPEN_CIRCUIT" 3 "VOLTAGE_ON_CIRCUIT" 2 "SHORT_TO_GND" 1 "SHORT_TO_VBAT" 0 "NONE_UNUSED" ;
VAL_ 1835 TAS_a168_damperValveFault 15 "REMOTE_VALVE_FAULTED" 14 "POSTIVE_TO_NEGATIVE_SHORT" 13 "DRIVER_OVER_TEMPERATURE" 12 "FEEDBACK_CURRENT_MIA" 11 "TARGET_CURRENT_MIA" 10 "LOW_SIDE_STATUS_IMPLAUSIBLE" 9 "CURRENT_MISMATCH" 8 "CURRENT_IMPLAUSIBLE" 7 "HIGH_RESISTANCE" 6 "LOW_RESISTANCE" 5 "CROSS_CONNECTION_SHORT" 4 "OPEN_CIRCUIT" 3 "VOLTAGE_ON_CIRCUIT" 2 "SHORT_TO_GND" 1 "SHORT_TO_VBAT" 0 "NONE_UNUSED" ;
VAL_ 1835 TAS_a169_damperValveFault 15 "REMOTE_VALVE_FAULTED" 14 "POSTIVE_TO_NEGATIVE_SHORT" 13 "DRIVER_OVER_TEMPERATURE" 12 "FEEDBACK_CURRENT_MIA" 11 "TARGET_CURRENT_MIA" 10 "LOW_SIDE_STATUS_IMPLAUSIBLE" 9 "CURRENT_MISMATCH" 8 "CURRENT_IMPLAUSIBLE" 7 "HIGH_RESISTANCE" 6 "LOW_RESISTANCE" 5 "CROSS_CONNECTION_SHORT" 4 "OPEN_CIRCUIT" 3 "VOLTAGE_ON_CIRCUIT" 2 "SHORT_TO_GND" 1 "SHORT_TO_VBAT" 0 "NONE_UNUSED" ;
VAL_ 1835 TAS_a170_damperValveFault 15 "REMOTE_VALVE_FAULTED" 14 "POSTIVE_TO_NEGATIVE_SHORT" 13 "DRIVER_OVER_TEMPERATURE" 12 "FEEDBACK_CURRENT_MIA" 11 "TARGET_CURRENT_MIA" 10 "LOW_SIDE_STATUS_IMPLAUSIBLE" 9 "CURRENT_MISMATCH" 8 "CURRENT_IMPLAUSIBLE" 7 "HIGH_RESISTANCE" 6 "LOW_RESISTANCE" 5 "CROSS_CONNECTION_SHORT" 4 "OPEN_CIRCUIT" 3 "VOLTAGE_ON_CIRCUIT" 2 "SHORT_TO_GND" 1 "SHORT_TO_VBAT" 0 "NONE_UNUSED" ;
VAL_ 1835 TAS_a171_damperValveFault 15 "REMOTE_VALVE_FAULTED" 14 "POSTIVE_TO_NEGATIVE_SHORT" 13 "DRIVER_OVER_TEMPERATURE" 12 "FEEDBACK_CURRENT_MIA" 11 "TARGET_CURRENT_MIA" 10 "LOW_SIDE_STATUS_IMPLAUSIBLE" 9 "CURRENT_MISMATCH" 8 "CURRENT_IMPLAUSIBLE" 7 "HIGH_RESISTANCE" 6 "LOW_RESISTANCE" 5 "CROSS_CONNECTION_SHORT" 4 "OPEN_CIRCUIT" 3 "VOLTAGE_ON_CIRCUIT" 2 "SHORT_TO_GND" 1 "SHORT_TO_VBAT" 0 "NONE_UNUSED" ;
VAL_ 1835 TAS_a172_damperValveFault 15 "REMOTE_VALVE_FAULTED" 14 "POSTIVE_TO_NEGATIVE_SHORT" 13 "DRIVER_OVER_TEMPERATURE" 12 "FEEDBACK_CURRENT_MIA" 11 "TARGET_CURRENT_MIA" 10 "LOW_SIDE_STATUS_IMPLAUSIBLE" 9 "CURRENT_MISMATCH" 8 "CURRENT_IMPLAUSIBLE" 7 "HIGH_RESISTANCE" 6 "LOW_RESISTANCE" 5 "CROSS_CONNECTION_SHORT" 4 "OPEN_CIRCUIT" 3 "VOLTAGE_ON_CIRCUIT" 2 "SHORT_TO_GND" 1 "SHORT_TO_VBAT" 0 "NONE_UNUSED" ;
VAL_ 1835 TAS_a190_a2bFaultType 8 "OTHER" 7 "DEVICE_RESET" 6 "NO_CLOCK_SYNC" 5 "MASTER_VENDOR_ID" 4 "NODE_DROP" 3 "FAILED_DISCOVERY" 2 "DATA" 1 "HARDWARE" 0 "NONE" ;
VAL_ 1835 TAS_a190_a2bInterruptType 255 "MSTR_RUNNING" 254 "STANDBY_DONE" 253 "SUB_READ_INTTYPE_ERROR" 252 "STARTUP_ERROR" 251 "NONE" 128 "INTERRUPT_MESSAGING_ERROR" 51 "MAILBOX_1_EMPTY" 50 "MAILBOX_1_FULL" 49 "MAILBOX_0_EMPTY" 48 "MAILBOX_0_FULL" 42 "NON_LOCALIZED_SHORT_TO_VBAT" 41 "NON_LOCALIZED_SHORT_TO_GROUND" 26 "INTERRUPT_CRC_ERROR" 25 "I2CERR" 24 "DSCDONE" 23 "IO7PND" 22 "IO6PND" 21 "IO5PND" 20 "IO4PND" 19 "IO3PND" 18 "IO2PND" 17 "IO1PND" 16 "IO0PND" 15 "UNDETERMINED_CABLE_FAULT" 14 "DISCONNECTED_WRONG_PORT_REVERSE" 13 "INTTYPE_REVERSE_CONNECTED_AD2428" 12 "INTTYPE_DISCONNECTED_AD2428" 11 "BP_SHORT_BN" 10 "BN_SHORT_VBAT" 9 "BP_SHORT_GND" 6 "SRF_CRC_ERROR" 5 "SRF_MISS_ERROR" 4 "BIT_ERROR_COUNT_OVERFLOW" 3 "DATA_SLOT_PARITY_ERROR" 2 "CRC_ERROR" 1 "DATA_SLOT_DECODING_ERROR" 0 "HEADER_COUNT_ERROR" ;
VAL_ 1835 TAS_a190_a2bFaultSource 3 "UNDETERMINED" 2 "MASTER" 1 "LEFT" 0 "RIGHT" ;
VAL_ 1835 TAS_a191_a2bFaultType 8 "OTHER" 7 "DEVICE_RESET" 6 "NO_CLOCK_SYNC" 5 "MASTER_VENDOR_ID" 4 "NODE_DROP" 3 "FAILED_DISCOVERY" 2 "DATA" 1 "HARDWARE" 0 "NONE" ;
VAL_ 1835 TAS_a191_a2bInterruptType 255 "MSTR_RUNNING" 254 "STANDBY_DONE" 253 "SUB_READ_INTTYPE_ERROR" 252 "STARTUP_ERROR" 251 "NONE" 128 "INTERRUPT_MESSAGING_ERROR" 51 "MAILBOX_1_EMPTY" 50 "MAILBOX_1_FULL" 49 "MAILBOX_0_EMPTY" 48 "MAILBOX_0_FULL" 42 "NON_LOCALIZED_SHORT_TO_VBAT" 41 "NON_LOCALIZED_SHORT_TO_GROUND" 26 "INTERRUPT_CRC_ERROR" 25 "I2CERR" 24 "DSCDONE" 23 "IO7PND" 22 "IO6PND" 21 "IO5PND" 20 "IO4PND" 19 "IO3PND" 18 "IO2PND" 17 "IO1PND" 16 "IO0PND" 15 "UNDETERMINED_CABLE_FAULT" 14 "DISCONNECTED_WRONG_PORT_REVERSE" 13 "INTTYPE_REVERSE_CONNECTED_AD2428" 12 "INTTYPE_DISCONNECTED_AD2428" 11 "BP_SHORT_BN" 10 "BN_SHORT_VBAT" 9 "BP_SHORT_GND" 6 "SRF_CRC_ERROR" 5 "SRF_MISS_ERROR" 4 "BIT_ERROR_COUNT_OVERFLOW" 3 "DATA_SLOT_PARITY_ERROR" 2 "CRC_ERROR" 1 "DATA_SLOT_DECODING_ERROR" 0 "HEADER_COUNT_ERROR" ;
VAL_ 1835 TAS_a191_a2bFaultSource 3 "UNDETERMINED" 2 "MASTER" 1 "LEFT" 0 "RIGHT" ;
VAL_ 1835 TAS_a226_PWMfaultFL 9 "NONE" 8 "COUNT" 7 "OPEN_CIRCUIT" 6 "SHORT_CIRCUIT" 5 "MIA" 4 "OVER_MAX_DELTA_DUTY" 3 "UNDER_MIN_PERIOD" 2 "OVER_MAX_PERIOD" 1 "UNDER_MIN_DUTY" 0 "OVER_MAX_DUTY" ;
VAL_ 1835 TAS_a227_PWMfaultFR 9 "NONE" 8 "COUNT" 7 "OPEN_CIRCUIT" 6 "SHORT_CIRCUIT" 5 "MIA" 4 "OVER_MAX_DELTA_DUTY" 3 "UNDER_MIN_PERIOD" 2 "OVER_MAX_PERIOD" 1 "UNDER_MIN_DUTY" 0 "OVER_MAX_DUTY" ;
VAL_ 1835 TAS_a228_PWMfaultRL 9 "NONE" 8 "COUNT" 7 "OPEN_CIRCUIT" 6 "SHORT_CIRCUIT" 5 "MIA" 4 "OVER_MAX_DELTA_DUTY" 3 "UNDER_MIN_PERIOD" 2 "OVER_MAX_PERIOD" 1 "UNDER_MIN_DUTY" 0 "OVER_MAX_DUTY" ;
VAL_ 1835 TAS_a229_PWMfaultRR 9 "NONE" 8 "COUNT" 7 "OPEN_CIRCUIT" 6 "SHORT_CIRCUIT" 5 "MIA" 4 "OVER_MAX_DELTA_DUTY" 3 "UNDER_MIN_PERIOD" 2 "OVER_MAX_PERIOD" 1 "UNDER_MIN_DUTY" 0 "OVER_MAX_DUTY" ;
VAL_ 1835 TAS_a232_detectedSuspensionType 6 "TESLA_ADAPTIVE" 5 "TESLA_PLUS" 4 "TESLA_STANDARD" 3 "CONTI_PLUS" 2 "CONTI_STANDARD" 1 "NONE" 0 "UNKNOWN" ;
VAL_ 1835 TAS_a232_expectedSuspensionType 6 "TESLA_ADAPTIVE" 5 "TESLA_PLUS" 4 "TESLA_STANDARD" 3 "CONTI_PLUS" 2 "CONTI_STANDARD" 1 "NONE" 0 "UNKNOWN" ;
VAL_ 1835 TAS_a234_detectedDamperHydraulic 2 "P3" 1 "V0" 0 "UNKNOWN" ;
VAL_ 1835 TAS_a234_expectedDamperHydraulic 2 "P3" 1 "V0" 0 "UNKNOWN" ;
VAL_ 1835 TAS_a240_adjustCountRatioSpring 4 "UNKNOWN" 3 "RR" 2 "RL" 1 "FR" 0 "FL" ;
VAL_ 1835 TAS_a240_adjustCountRatio 255 "SNA" ;
VAL_ 1835 TAS_a240_adjustTimeRatioSpring 4 "UNKNOWN" 3 "RR" 2 "RL" 1 "FR" 0 "FL" ;
VAL_ 1835 TAS_a240_adjustTimeRatio 255 "SNA" ;
VAL_ 1835 TAS_a296_detectedChassisType 4 "CYBERTRUCK" 3 "MODEL3" 2 "MODELX" 1 "MODELS" 0 "UNKNOWN" ;
VAL_ 1835 TAS_a296_expectedChassisType 4 "CYBERTRUCK" 3 "MODEL3" 2 "MODELX" 1 "MODELS" 0 "UNKNOWN" ;
VAL_ 1835 TAS_a319_detectedDrivetrainType 3 "AWD_DUAL_REAR" 2 "AWD" 1 "RWD" 0 "UNKNOWN" ;
VAL_ 1835 TAS_a319_expectedDrivetrainType 3 "AWD_DUAL_REAR" 2 "AWD" 1 "RWD" 0 "UNKNOWN" ;
VAL_ 852 TAS_matrixIndex 5 "AlertMatrix5" 4 "AlertMatrix4" 3 "AlertMatrix3" 2 "AlertMatrix2" 1 "AlertMatrix1" 0 "AlertMatrix0" ;
VAL_ 1410 TCU_alertID 6 "w006_MpssUnavailable" 5 "w005_SIMSlotError" 4 "w004_MSDTransmissionFailed" 3 "w003_ECallFailed" 2 "w002_CellRegRejected" 1 "w001_IMSRegistrationFailed" 0 "ALERT_DO_NOT_USE_ZERO" ;
VAL_ 1410 TCU_alertState 1 "SET" 0 "CLEARED" ;
VAL_ 1409 TCU_logMux 15 "mdmBusyActive" 14 "mdmSIMStatus" 13 "mdmIMSStatus" 12 "mdmServiceState" 11 "mdmUplinkAvgRage" 10 "mdmUplinkAllowedRate" 9 "mdmSINR" 8 "mdmRSRP" 7 "mdmUplinkQueueSize" 6 "totalResumes" 5 "pwmcap" 4 "pwm" 3 "availableMemory" 2 "mdmCoreTemperature" 1 "cpuUsage" 0 "cpuTemp" ;
VAL_ 1409 TCU_mdmBusyActive 4294967295 "SNA" ;
VAL_ 1408 TCU_statusMux 2 "goingToSleep" 1 "tcuCmdId" 0 "wakeUpReason" ;
VAL_ 1408 TCU_wakeUpReason 4294967295 "SNA" ;
VAL_ 1408 TCU_goingToSleep 4294967295 "SNA" ;
